VERSION ""

NS_ :

BS_:

BU_: GWM SCMB_PSM HVAC_RCCM GENERIC_GWMWakeup SOBDMD_AHCM_FOH TRM _delete SODL RTM PDM SCMH SCMG RSM SODR DDM RGTM DSM SCME TSTR

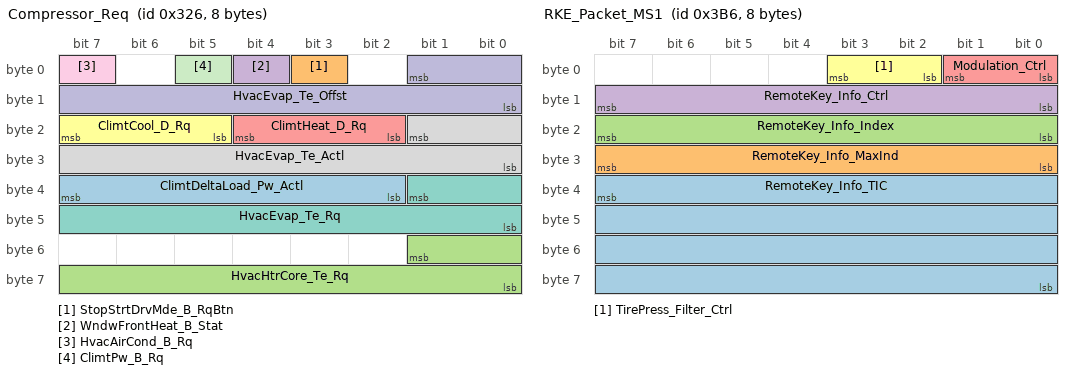
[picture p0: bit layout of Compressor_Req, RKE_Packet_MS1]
BO_ 806 Compressor_Req: 8 HVAC_RCCM
 SG_ ClimtDeltaLoad_Pw_Actl : 39|6@0+ (50,-1600) [-1600|1450] "watts"  GWM
 SG_ StopStrtDrvMde_B_RqBtn : 3|1@0+ (1,0) [0|1] "SED"  GWM
 SG_ HvacHtrCore_Te_Rq : 49|10@0+ (0.25,-50) [-50|205.75] "degC"  GWM
 SG_ WndwFrontHeat_B_Stat : 4|1@0+ (1,0) [0|1] "SED"  GWM
 SG_ ClimtHeat_D_Rq : 20|3@0+ (1,0) [0|7] "SED"  GWM
 SG_ ClimtCool_D_Rq : 23|3@0+ (1,0) [0|7] "SED"  GWM
 SG_ HvacEvap_Te_Rq : 33|10@0+ (0.125,-50) [-50|77.875] "Degrees C"  GWM
 SG_ HvacEvap_Te_Actl : 17|10@0+ (0.125,-50) [-50|77.75] "Degrees C"  GWM
 SG_ HvacAirCond_B_Rq : 7|1@0+ (1,0) [0|1] "SED"  GWM
 SG_ HvacEvap_Te_Offst : 1|10@0+ (0.125,-50) [-50|77.875] "Degrees C"  GWM
 SG_ ClimtPw_B_Rq : 5|1@0+ (1,0) [0|1] "SED"  GWM

BO_ 950 RKE_Packet_MS1: 8 GWM
 SG_ RemoteKey_Info_TIC : 39|32@0+ (1,0) [0|4294967295] "Unitless"  RTM
 SG_ RemoteKey_Info_MaxInd : 31|8@0+ (1,0) [0|255] "Unitless"  RTM
 SG_ RemoteKey_Info_Index : 23|8@0+ (1,0) [0|255] "Unitless"  RTM
 SG_ RemoteKey_Info_Ctrl : 15|8@0+ (1,0) [0|255] "Unitless" Vector__XXX
 SG_ Modulation_Ctrl : 1|2@0+ (1,0) [0|3] "SED" Vector__XXX
 SG_ TirePress_Filter_Ctrl : 3|2@0+ (1,0) [0|3] "SED"  RTM

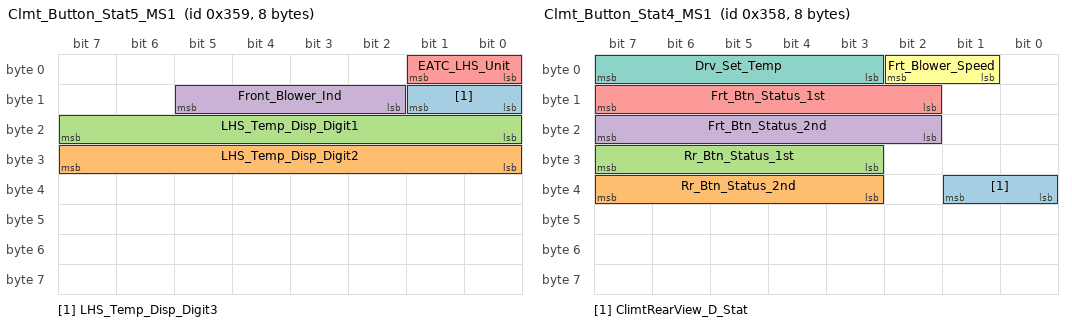
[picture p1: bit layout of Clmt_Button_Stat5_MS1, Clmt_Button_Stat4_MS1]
BO_ 857 Clmt_Button_Stat5_MS1: 8 GWM
 SG_ LHS_Temp_Disp_Digit3 : 9|2@0+ (1,0) [0|3] "SED"  HVAC_RCCM
 SG_ LHS_Temp_Disp_Digit2 : 31|8@0+ (1,0) [0|255] "ASCII"  HVAC_RCCM
 SG_ LHS_Temp_Disp_Digit1 : 23|8@0+ (1,0) [0|255] "ASCII"  HVAC_RCCM
 SG_ Front_Blower_Ind : 13|4@0+ (1,0) [0|15] "SED"  HVAC_RCCM
 SG_ EATC_LHS_Unit : 1|2@0+ (1,0) [0|3] "SED"  HVAC_RCCM

BO_ 856 Clmt_Button_Stat4_MS1: 8 GWM
 SG_ ClimtRearView_D_Stat : 33|2@0+ (1,0) [0|3] "SED" Vector__XXX
 SG_ Rr_Btn_Status_2nd : 39|5@0+ (1,0) [0|31] "SED" Vector__XXX
 SG_ Rr_Btn_Status_1st : 31|5@0+ (1,0) [0|31] "SED" Vector__XXX
 SG_ Frt_Btn_Status_2nd : 23|6@0+ (1,0) [0|63] "SED"  HVAC_RCCM
 SG_ Frt_Btn_Status_1st : 15|6@0+ (1,0) [0|63] "SED"  HVAC_RCCM
 SG_ Frt_Blower_Speed : 2|2@0+ (1,0) [0|3] "SED"  HVAC_RCCM
 SG_ Drv_Set_Temp : 7|5@0+ (1,0) [0|31] "SED"  HVAC_RCCM

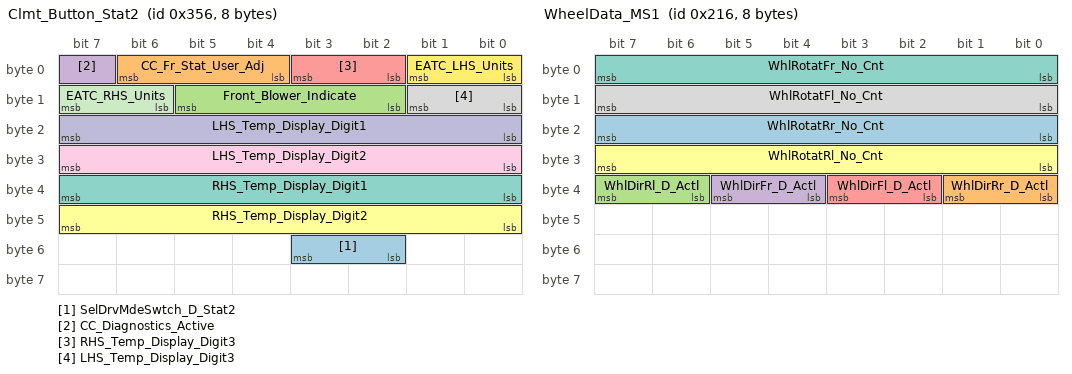
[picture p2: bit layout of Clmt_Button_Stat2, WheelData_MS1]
BO_ 854 Clmt_Button_Stat2: 8 HVAC_RCCM
 SG_ SelDrvMdeSwtch_D_Stat2 : 51|2@0+ (1,0) [0|3] "SED"  GWM
 SG_ CC_Fr_Stat_User_Adj : 6|3@0+ (1,0) [0|7] "SED"  GWM
 SG_ Front_Blower_Indicate : 13|4@0+ (1,0) [0|15] "SED"  GWM
 SG_ CC_Diagnostics_Active : 7|1@0+ (1,0) [0|1] "SED"  GWM
 SG_ RHS_Temp_Display_Digit3 : 3|2@0+ (1,0) [0|3] "SED"  GWM
 SG_ RHS_Temp_Display_Digit2 : 47|8@0+ (1,0) [0|255] "ASCII"  GWM
 SG_ RHS_Temp_Display_Digit1 : 39|8@0+ (1,0) [0|255] "ASCII"  GWM
 SG_ LHS_Temp_Display_Digit3 : 9|2@0+ (1,0) [0|3] "SED"  GWM
 SG_ LHS_Temp_Display_Digit2 : 31|8@0+ (1,0) [0|255] "ASCII"  GWM
 SG_ LHS_Temp_Display_Digit1 : 23|8@0+ (1,0) [0|255] "ASCII"  GWM
 SG_ EATC_RHS_Units : 15|2@0+ (1,0) [0|3] "SED"  GWM
 SG_ EATC_LHS_Units : 1|2@0+ (1,0) [0|3] "SED"  GWM

BO_ 534 WheelData_MS1: 8 GWM
 SG_ WhlRotatRr_No_Cnt : 23|8@0+ (1,0) [0|255] "Unitless"  SODL,SODR
 SG_ WhlDirRr_D_Actl : 33|2@0+ (1,0) [0|3] "SED"  SODL,SODR
 SG_ WhlDirRl_D_Actl : 39|2@0+ (1,0) [0|3] "SED"  SODL,SODR
 SG_ WhlDirFr_D_Actl : 37|2@0+ (1,0) [0|3] "SED"  SODL,SODR
 SG_ WhlDirFl_D_Actl : 35|2@0+ (1,0) [0|3] "SED"  SODL,SODR
 SG_ WhlRotatRl_No_Cnt : 31|8@0+ (1,0) [0|255] "Unitless"  SODL,SODR
 SG_ WhlRotatFr_No_Cnt : 7|8@0+ (1,0) [0|255] "Unitless"  SODL,SODR
 SG_ WhlRotatFl_No_Cnt : 15|8@0+ (1,0) [0|255] "Unitless"  SODL,SODR

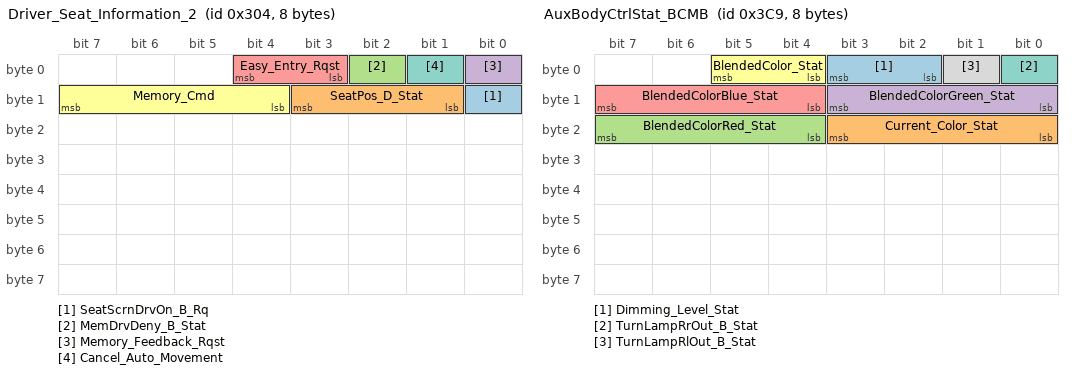
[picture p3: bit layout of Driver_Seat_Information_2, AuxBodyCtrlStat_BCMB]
BO_ 772 Driver_Seat_Information_2: 8 DSM
 SG_ SeatScrnDrvOn_B_Rq : 8|1@0+ (1,0) [0|1] "SED"  GWM
 SG_ SeatPos_D_Stat : 11|3@0+ (1,0) [0|7] "SED"  GWM
 SG_ MemDrvDeny_B_Stat : 2|1@0+ (1,0) [0|1] "SED"  GWM
 SG_ Memory_Feedback_Rqst : 0|1@0+ (1,0) [0|1] "SED"  GWM
 SG_ Easy_Entry_Rqst : 4|2@0+ (1,0) [0|3] "SED"  GWM,SCMH,SCMG
 SG_ Memory_Cmd : 15|4@0+ (1,0) [0|15] "SED"  GWM,SCMH,DDM,PDM,SCMG
 SG_ Cancel_Auto_Movement : 1|1@0+ (1,0) [0|1] "SED"  GWM,SCMH,PDM,DDM,SCMG

BO_ 935 Side_Detect_R_Stat: 8 SODR
 SG_ LcwaRight_D_Stat : 52|3@0+ (1,0) [0|7] "SED"  GWM
 SG_ LcwaDetctRight2_B_Stat : 40|1@0+ (1,0) [0|1] "SED"  GWM
 SG_ LcwaDetctRight1_B_Stat : 41|1@0+ (1,0) [0|1] "SED"  GWM
 SG_ RbaCtaRight_D_Stat : 55|3@0+ (1,0) [0|7] "SED"  SODL,GWM
 SG_ BttRight_D_Stat : 45|3@0+ (1,0) [0|7] "SED"  SODL,GWM
 SG_ BttRight_D_RqDrv : 47|2@0+ (1,0) [0|3] "SED"  SODL,GWM
 SG_ CtaAlrtRight2_D_Stat : 30|3@0+ (1,0) [0|7] "SED"  GWM
 SG_ CtaRightBrkEnbl_B_Rq : 31|1@0+ (1,0) [0|1] "SED"  SODL,GWM
 SG_ CtaRightBrkDecel_B_Rq : 7|1@0+ (1,0) [0|1] "SED"  SODL,GWM
 SG_ Side_Detect_R_Illum : 39|8@0+ (1,0) [0|255] "Percent"  DDM,PDM,GWM
 SG_ CtaSnsRight_D_Stat : 25|2@0+ (1,0) [0|3] "SED"  SODL,GWM
 SG_ CtaAlrtRight_D_Stat : 8|1@0+ (1,0) [0|1] "SED"  DDM,PDM,GWM
 SG_ CtaRight_D_Stat : 18|3@0+ (1,0) [0|7] "SED"  SODL,GWM
 SG_ SodRight_D_Stat : 15|3@0+ (1,0) [0|7] "SED"  SODL,GWM
 SG_ SodSnsRight_D_Stat : 12|2@0+ (1,0) [0|3] "SED"  DDM,PDM,GWM,SODL
 SG_ SodAlrtRight_D_Stat : 10|2@0+ (1,0) [0|3] "SED"  DDM,PDM,GWM
 SG_ SodDetctRight_D_Stat : 23|3@0+ (1,0) [0|7] "SED"  GWM
 SG_ SodWarnRight_Prd_Rq : 6|7@0+ (1,0) [0|127] "millisecond"  DDM,PDM,GWM
 SG_ SodInnrRight_D_Stat : 20|2@0+ (1,0) [0|3] "SED"  SODL,GWM
 SG_ CtaInnrRight_D_Stat : 27|2@0+ (1,0) [0|3] "SED"  GWM,SODL

BO_ 934 Side_Detect_L_Stat: 8 SODL
 SG_ RbaCtaLeft_D_Stat : 55|3@0+ (1,0) [0|7] "SED"  GWM,SODR
 SG_ LcwaLeft_D_Stat : 52|3@0+ (1,0) [0|7] "SED"  GWM,SODR
 SG_ LcwaDetctLeft2_B_Stat : 40|1@0+ (1,0) [0|1] "SED"  GWM,SODR
 SG_ LcwaDetctLeft1_B_Stat : 41|1@0+ (1,0) [0|1] "SED"  GWM,SODR
 SG_ BttLeft_D_Stat : 45|3@0+ (1,0) [0|7] "SED"  GWM,SODR
 SG_ BttLeft_D_RqDrv : 47|2@0+ (1,0) [0|3] "SED"  SODR,GWM
 SG_ CtaAlrtLeft2_D_Stat : 30|3@0+ (1,0) [0|7] "SED"  GWM
 SG_ CtaLeftBrkDecel_B_Rq : 7|1@0+ (1,0) [0|1] "SED"  SODR,GWM
 SG_ CtaLeftBrkEnbl_B_Rq : 31|1@0+ (1,0) [0|1] "SED"  SODR,GWM
 SG_ Side_Detect_L_Illum : 39|8@0+ (1,0) [0|255] "Percent"  GWM,DDM,PDM
 SG_ CtaInnrLeft_D_Stat : 27|2@0+ (1,0) [0|3] "SED"  GWM,SODR
 SG_ CtaSnsLeft_D_Stat : 25|2@0+ (1,0) [0|3] "SED"  SODR,GWM
 SG_ SodDetctLeft_D_Stat : 23|3@0+ (1,0) [0|7] "SED"  GWM
 SG_ CtaLeft_D_Stat : 18|3@0+ (1,0) [0|7] "SED"  SODR,GWM
 SG_ CtaAlrtLeft_D_Stat : 8|1@0+ (1,0) [0|1] "SED"  DDM,PDM,GWM
 SG_ SodLeft_D_Stat : 15|3@0+ (1,0) [0|7] "SED"  SODR,GWM
 SG_ SodSnsLeft_D_Stat : 12|2@0+ (1,0) [0|3] "SED"  DDM,PDM,SODR,GWM
 SG_ SodAlrtLeft_D_Stat : 10|2@0+ (1,0) [0|3] "SED"  DDM,PDM,GWM
 SG_ SodWarnLeft_Prd_Rq : 6|7@0+ (1,0) [0|127] "millisecond"  DDM,PDM,GWM
 SG_ SodInnrLeft_D_Stat : 20|2@0+ (1,0) [0|3] "SED"  SODR,GWM

BO_ 969 AuxBodyCtrlStat_BCMB: 8 GENERIC_GWMWakeup
 SG_ Dimming_Level_Stat : 3|2@0+ (1,0) [0|3] "SED"  GWM
 SG_ Current_Color_Stat : 19|4@0+ (1,0) [0|15] "SED"  GWM
 SG_ BlendedColorRed_Stat : 23|4@0+ (1,0) [0|15] "SED"  GWM
 SG_ BlendedColorGreen_Stat : 11|4@0+ (1,0) [0|15] "SED"  GWM
 SG_ BlendedColorBlue_Stat : 15|4@0+ (1,0) [0|15] "SED"  GWM
 SG_ BlendedColor_Stat : 5|2@0+ (1,0) [0|3] "SED"  GWM
 SG_ TurnLampRrOut_B_Stat : 0|1@0+ (1,0) [0|1] "SED"  GWM
 SG_ TurnLampRlOut_B_Stat : 1|1@0+ (1,0) [0|1] "SED"  GWM

BO_ 1070 EngineData_2_MS1: 8 GWM
 SG_ StopStrtStdby_D_Indic_UB : 43|1@0+ (1,0) [0|1] "SED" Vector__XXX
 SG_ PassRstrnInd_Req_UB : 42|1@0+ (1,0) [0|1] "SED" Vector__XXX
 SG_ HiElPwInhbt_B_Stat_UB : 61|1@0+ (1,0) [0|1] "SED"  DDM,PDM
 SG_ HiElPwInhbt_B_Stat : 47|1@0+ (1,0) [0|1] "SED"  DDM,PDM
 SG_ StopStrtStdby_D_Indic : 46|3@0+ (1,0) [0|7] "SED" Vector__XXX
 SG_ CoolantFanStepAct_UB : 2|1@0+ (1,0) [0|1] "SED"  HVAC_RCCM
 SG_ CoolantFanStepAct : 7|5@0+ (1,0) [0|31] "Steps"  HVAC_RCCM
 SG_ RstrnImpactEvntStatus_UB : 56|1@0+ (1,0) [0|1] "SED"  HVAC_RCCM,SOBDMD_AHCM_FOH
 SG_ EngAirIn_Te_Actl_UB : 60|1@0+ (1,0) [0|1] "SED"  HVAC_RCCM
 SG_ RstrnImpactEvntStatus : 59|3@0+ (1,0) [0|7] "SED"  HVAC_RCCM,SOBDMD_AHCM_FOH
 SG_ EngAirIn_Te_Actl : 55|10@0+ (0.25,-128) [-128|127.25] "degC"  HVAC_RCCM
 SG_ EngAout_N_Actl_UB : 0|1@0+ (1,0) [0|1] "SED"  HVAC_RCCM,SOBDMD_AHCM_FOH
 SG_ EngAout_N_Actl : 28|13@0+ (2,0) [0|16382] "rpm"  HVAC_RCCM,SOBDMD_AHCM_FOH
 SG_ VehVActlEng_D_Qf : 31|2@0+ (1,0) [0|3] "SED"  SCME,HVAC_RCCM,DSM,RTM,DDM,PDM,SODL,SODR
 SG_ Veh_V_ActlEng_UB : 29|1@0+ (1,0) [0|1] "SED"  SCME,HVAC_RCCM,RGTM,DSM,SCMG,SCMH,DDM,PDM,RTM,SODL,SODR
 SG_ Veh_V_ActlEng : 15|16@0+ (0.01,0) [0|655.35] "kph"  SCME,HVAC_RCCM,SODL,RGTM,DSM,SCMG,SCMH,DDM,PDM,RTM,SODR
 SG_ PassRstrnInd_Req : 41|2@0+ (1,0) [0|3] "SED" Vector__XXX

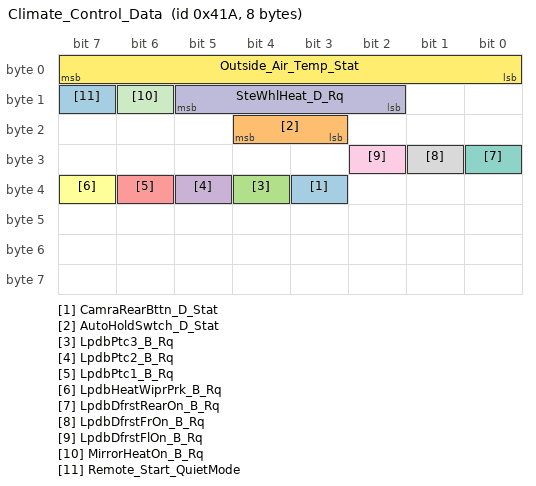
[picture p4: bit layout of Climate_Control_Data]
BO_ 1050 Climate_Control_Data: 8 HVAC_RCCM
 SG_ CamraRearBttn_D_Stat : 35|1@0+ (1,0) [0|1] "SED"  GWM
 SG_ AutoHoldSwtch_D_Stat : 20|2@0+ (1,0) [0|3] "SED"  GWM
 SG_ LpdbPtc3_B_Rq : 36|1@0+ (1,0) [0|1] "SED"  GWM
 SG_ LpdbPtc2_B_Rq : 37|1@0+ (1,0) [0|1] "SED"  GWM
 SG_ LpdbPtc1_B_Rq : 38|1@0+ (1,0) [0|1] "SED"  GWM
 SG_ LpdbHeatWiprPrk_B_Rq : 39|1@0+ (1,0) [0|1] "SED"  GWM
 SG_ LpdbDfrstRearOn_B_Rq : 24|1@0+ (1,0) [0|1] "SED"  GWM
 SG_ LpdbDfrstFrOn_B_Rq : 25|1@0+ (1,0) [0|1] "SED"  GWM
 SG_ LpdbDfrstFlOn_B_Rq : 26|1@0+ (1,0) [0|1] "SED"  GWM
 SG_ SteWhlHeat_D_Rq : 13|4@0+ (1,0) [0|15] "SED"  GWM
 SG_ MirrorHeatOn_B_Rq : 14|1@0+ (1,0) [0|1] "SED"  GWM,DDM,PDM
 SG_ Outside_Air_Temp_Stat : 7|8@0+ (0.5,-40) [-40|86.5] "Degrees C"  RGTM,GWM,DDM,PDM,SOBDMD_AHCM_FOH
 SG_ Remote_Start_QuietMode : 15|1@0+ (1,0) [0|1] "SED"  GWM

BO_ 1856 TesterPhysicalReqDDM: 8 TSTR
 SG_ TesterPhysicalReqDDM : 7|64@0+ (1,0) [0|1.84467E+019] "unitless"  DDM

BO_ 1864 TesterPhysicalResDDM: 8 DDM
 SG_ TesterPhysicalResDDM : 7|64@0+ (1,0) [0|1.84467E+019] "unitless"  TSTR

BO_ 1937 TesterPhysicalReqTRM: 8 TSTR
 SG_ TesterPhysicalReqTRM : 7|64@0+ (1,0) [0|1.84467E+019] "unitless"  TRM

CM_ SG_ 857 LHS_Temp_Disp_Digit3 "Added for MY 08";
CM_ SG_ 857 LHS_Temp_Disp_Digit2 "Added for MY 08";
CM_ SG_ 857 LHS_Temp_Disp_Digit1 "Added for MY 08";
CM_ SG_ 857 EATC_LHS_Unit "Added for MY 08";
CM_ SG_ 854 RHS_Temp_Display_Digit3 "Added for MY 08";
CM_ SG_ 854 RHS_Temp_Display_Digit2 "Added for MY 08";
CM_ SG_ 854 RHS_Temp_Display_Digit1 "Added for MY 08";
CM_ SG_ 854 LHS_Temp_Display_Digit3 "Added for MY 08";
CM_ SG_ 854 LHS_Temp_Display_Digit2 "Added for MY 08";
CM_ SG_ 854 LHS_Temp_Display_Digit1 "Added for MY 08";
CM_ SG_ 854 EATC_RHS_Units "Added for MY 08";
CM_ SG_ 854 EATC_LHS_Units "Added for MY 08";
CM_ SG_ 534 WhlRotatRr_No_Cnt "DCR 1833 to update Tx from GWM to EP100ms. Wheel Count signals are used by complex algorithm to determine Tire Pressure by Location & can't change from 20msec. (jweinfur)";
CM_ SG_ 534 WhlRotatRl_No_Cnt "DCR 1833 to update Tx from GWM to EP100ms. Wheel Count signals are used by complex algorithm to determine Tire Pressure by Location & can't change from 20msec. (jweinfur)";
CM_ SG_ 534 WhlRotatFr_No_Cnt "DCR 1833 to update Tx from GWM to EP100ms. Wheel Count signals are used by complex algorithm to determine Tire Pressure by Location & can't change from 20msec. (jweinfur)";
CM_ SG_ 534 WhlRotatFl_No_Cnt "DCR 1833 to update Tx from GWM to EP100ms. Wheel Count signals are used by complex algorithm to determine Tire Pressure by Location & can't change from 20msec. (jweinfur)";
CM_ SG_ 772 Memory_Feedback_Rqst "Updated to 1 bit for CGEA, Not backwards compatible";
CM_ SG_ 935 Side_Detect_R_Illum "DDMGenSigTimeoutTime=2000";
CM_ SG_ 935 SodRight_D_Stat "IPCGenSigTimeoutTime=1600";
CM_ SG_ 935 SodSnsRight_D_Stat "IPCGenSigTimeoutTime=1600";
CM_ SG_ 935 SodAlrtRight_D_Stat "DDMGenSigTimeoutTime=2000";
CM_ SG_ 935 CtaInnrRight_D_Stat "IPCGenSigTimeoutTime=1600";
CM_ SG_ 934 Side_Detect_L_Illum "DDMGenSigTimeoutTime=2000";
CM_ SG_ 934 CtaInnrLeft_D_Stat "IPCGenSigTimeoutTime=1600";
CM_ SG_ 934 SodLeft_D_Stat "IPCGenSigTimeoutTime=1600";
CM_ SG_ 934 SodSnsLeft_D_Stat "IPCGenSigTimeoutTime=1600";
CM_ SG_ 934 SodAlrtLeft_D_Stat "DDMGenSigTimeoutTime=2000";
CM_ SG_ 969 TurnLampRrOut_B_Stat "Signal not transmitted on vehicles without a BCMB module.";
CM_ SG_ 969 TurnLampRlOut_B_Stat "Signal not transmitted on vehicles without a BCMB module.";
CM_ SG_ 1070 HiElPwInhbt_B_Stat "Signal not transmitted on HEV programs";
CM_ SG_ 1050 Outside_Air_Temp_Stat "Filtered value, i.e. same as disply for customer";
BA_DEF_ BO_  "FrameGatewayNetwork" STRING ;
BA_DEF_ BO_  "FrameGatewayMS1" HEX 0 1407;
BA_DEF_ BO_  "NetworkInitialization" ENUM  "No","Yes";
BA_DEF_ BO_  "FrameGatewayId" HEX 0 1407;
BA_DEF_ BO_  "EventRateOfChange" INT 10 10000;
BA_DEF_ BO_  "GenMsgStartDelayTime" INT 0 10000;
BA_DEF_ BO_  "GenMsgNrOfRepetition" INT 0 100;
BA_DEF_ BO_  "GenMsgDelayTime" INT 0 1000;
BA_DEF_ BO_  "GenMsgCycleTime" INT 0 100000;
BA_DEF_ BO_  "GenMsgSendType" ENUM  "FixedPeriodic","Event","EnabledPeriodic","NotUsed","NotUsed","EventPeriodic","NotUsed","NotUsed","NoMsgSendType";
BA_DEF_ SG_  "U_P702_MY2021_Tx" ENUM  "No","Yes";
BA_DEF_ SG_  "U_CX727_MY2021_Tx" ENUM  "No","Yes";
BA_DEF_ SG_  "U_VN127_MY20_Tx" ENUM  "No","Yes";
BA_DEF_ SG_  "U_H567_MY20_Tx" ENUM  "No","Yes";
BA_DEF_ SG_  "U_CX430_MY2021_Tx" ENUM  "No","Yes";
BA_DEF_ SG_  "U_U611_U625_MY20_Phev_Tx" ENUM  "No","Yes";
BA_DEF_ SG_  "U_B562_MY18_Diesel_Tx" ENUM  "No","Yes";
BA_DEF_ SG_  "U_CX482_CX483_MY20_Tx" ENUM  "No","Yes";
BA_DEF_ SG_  "U_U611_U625_MY20_Hev_Tx" ENUM  "No","Yes";
BA_DEF_ SG_  "U_U611_U625_MY20_Gas_Tx" ENUM  "No","Yes";
BA_DEF_ SG_  "U_B500_MY18_Diesel_Tx" ENUM  "No","Yes";
BA_DEF_ SG_  "U_B500_MY18_Gas_Tx" ENUM  "No","Yes";
BA_DEF_ SG_  "U_C490_MY18_Tx" ENUM  "No","Yes";
BA_DEF_ SG_  "U_B562_MY18_Gas_Tx" ENUM  "No","Yes";
BA_DEF_ SG_  "U_C519_MY18_5_Gas_Tx" ENUM  "No","Yes";
BA_DEF_ SG_  "U_C519_MY18_5_Diesel_Tx" ENUM  "No","Yes";
BA_DEF_ SG_  "U_B515_MCA_MY17_Gas_Tx" ENUM  "No","Yes";
BA_DEF_ SG_  "U_B515_MCA_MY17_Diesel_Tx" ENUM  "No","Yes";
BA_DEF_ SG_  "U_B479_MY17_Diesel_Tx" ENUM  "No","Yes";
BA_DEF_ SG_  "U_B479_MY17_Gas_Tx" ENUM  "No","Yes";
BA_DEF_ SG_  "U_P702_MY2021_Rx" ENUM  "No","Yes";
BA_DEF_ SG_  "U_CX727_MY2021_Rx" ENUM  "No","Yes";
BA_DEF_ SG_  "U_VN127_MY20_Rx" ENUM  "No","Yes";
BA_DEF_ SG_  "U_H567_MY20_Rx" ENUM  "No","Yes";
BA_DEF_ SG_  "U_CX430_MY2021_Rx" ENUM  "No","Yes";
BA_DEF_ SG_  "U_U611_U625_MY20_Phev_Rx" ENUM  "No","Yes";
BA_DEF_ SG_  "U_B562_MY18_Diesel_Rx" ENUM  "No","Yes";
BA_DEF_ SG_  "U_CX482_CX483_MY20_Rx" ENUM  "No","Yes";
BA_DEF_ SG_  "U_U611_U625_MY20_Hev_Rx" ENUM  "No","Yes";
BA_DEF_ SG_  "U_U611_U625_MY20_Gas_Rx" ENUM  "No","Yes";
BA_DEF_ SG_  "U_B500_MY18_Diesel_Rx" ENUM  "No","Yes";
BA_DEF_ SG_  "U_B500_MY18_Gas_Rx" ENUM  "No","Yes";
BA_DEF_ SG_  "U_C490_MY18_Rx" ENUM  "No","Yes";
BA_DEF_ SG_  "U_B562_MY18_Gas_Rx" ENUM  "No","Yes";
BA_DEF_ SG_  "U_LC1_B515_MY17_Gas_Rx" ENUM  "No","Yes";
BA_DEF_ SG_  "U_LC1_B515_MY17_Diesel_Rx" ENUM  "No","Yes";
BA_DEF_ SG_  "U_C519_MY18_5_Gas_Rx" ENUM  "No","Yes";
BA_DEF_ SG_  "U_C519_MY18_5_Diesel_Rx" ENUM  "No","Yes";
BA_DEF_ SG_  "U_B515_MCA_MY17_Gas_Rx" ENUM  "No","Yes";
BA_DEF_ SG_  "U_B515_MCA_MY17_Diesel_Rx" ENUM  "No","Yes";
BA_DEF_ SG_  "U_B479_MY17_Diesel_Rx" ENUM  "No","Yes";
BA_DEF_ SG_  "U_B479_MY17_Gas_Rx" ENUM  "No","Yes";
BA_DEF_ SG_  "U_B562LC_MY15_Gas_Rx" ENUM  "No","Yes";
BA_DEF_ SG_  "U_B562LC_MY15_Diesel_Rx" ENUM  "No","Yes";
BA_DEF_ SG_  "GenSigStartValue" HEX 0 268435455;
BA_DEF_ SG_  "MetaData" ENUM  "No","Yes";
BA_DEF_ SG_  "ContentDependant" ENUM  "No","Yes";
BA_DEF_ SG_  "GenSigStartValueInteger" INT 0 1000000000;
BA_DEF_ SG_  "UsedOnPgmDBC" ENUM  "No","Yes";
BA_DEF_ SG_  "CrossOver_InfoCAN" ENUM  "No","Yes";
BA_DEF_ SG_  "WakeupSignal" ENUM  "No","Yes";
BA_DEF_ SG_  "GenSigInactiveValue" INT 0 100000;
BA_DEF_ SG_  "GenSigSendType" ENUM  "Cyclic","OnWrite","vector_leerstring","OnChange","vector_leerstring","IfActive","vector_leerstring","NoSigSendType";
BA_DEF_ BO_  "AuthFreshnessCounterSyncAttempt" INT 0 2;
BA_DEF_ BO_  "GenMsgRoutingTimeoutTime" INT 0 5000;
BA_DEF_ BO_  "MessageGateway" ENUM  "No","Yes";
BA_DEF_ BO_  "NmAsrMessage" ENUM  "No","Yes";
BA_DEF_ BO_  "DiagState" ENUM  "No","Yes";
BA_DEF_ BO_  "DiagRequest" ENUM  "No","Yes";
BA_DEF_ BO_  "DiagResponse" ENUM  "No","Yes";
BA_DEF_ BO_  "NmMessage" ENUM  "No","Yes";
BA_DEF_ BO_  "GenMsgILSupport" ENUM  "No","Yes";
BA_DEF_DEF_  "FrameGatewayNetwork" "NONE";
BA_DEF_DEF_  "FrameGatewayMS1" 0;
BA_DEF_DEF_  "NetworkInitialization" "Yes";
BA_DEF_DEF_  "FrameGatewayId" 0;
BA_DEF_DEF_  "EventRateOfChange" 10000;
BA_DEF_DEF_  "GenMsgStartDelayTime" 0;
BA_DEF_DEF_  "GenMsgNrOfRepetition" 1;
BA_DEF_DEF_  "GenMsgDelayTime" 20;
BA_DEF_DEF_  "GenMsgCycleTime" 0;
BA_DEF_DEF_  "GenMsgSendType" "NoMsgSendType";
BA_DEF_DEF_  "U_P702_MY2021_Tx" "No";
BA_DEF_DEF_  "U_CX727_MY2021_Tx" "No";
BA_DEF_DEF_  "U_VN127_MY20_Tx" "No";
BA_DEF_DEF_  "U_H567_MY20_Tx" "No";
BA_DEF_DEF_  "U_CX430_MY2021_Tx" "No";
BA_DEF_DEF_  "U_U611_U625_MY20_Phev_Tx" "No";
BA_DEF_DEF_  "U_B562_MY18_Diesel_Tx" "No";
BA_DEF_DEF_  "U_CX482_CX483_MY20_Tx" "No";
BA_DEF_DEF_  "U_U611_U625_MY20_Hev_Tx" "No";
BA_DEF_DEF_  "U_U611_U625_MY20_Gas_Tx" "No";
BA_DEF_DEF_  "U_B500_MY18_Diesel_Tx" "No";
BA_DEF_DEF_  "U_B500_MY18_Gas_Tx" "No";
BA_DEF_DEF_  "U_C490_MY18_Tx" "No";
BA_DEF_DEF_  "U_B562_MY18_Gas_Tx" "No";
BA_DEF_DEF_  "U_C519_MY18_5_Gas_Tx" "No";
BA_DEF_DEF_  "U_C519_MY18_5_Diesel_Tx" "No";
BA_DEF_DEF_  "U_B515_MCA_MY17_Gas_Tx" "No";
BA_DEF_DEF_  "U_B515_MCA_MY17_Diesel_Tx" "No";
BA_DEF_DEF_  "U_B479_MY17_Diesel_Tx" "No";
BA_DEF_DEF_  "U_B479_MY17_Gas_Tx" "No";
BA_DEF_DEF_  "U_P702_MY2021_Rx" "No";
BA_DEF_DEF_  "U_CX727_MY2021_Rx" "No";
BA_DEF_DEF_  "U_VN127_MY20_Rx" "No";
BA_DEF_DEF_  "U_H567_MY20_Rx" "No";
BA_DEF_DEF_  "U_CX430_MY2021_Rx" "No";
BA_DEF_DEF_  "U_U611_U625_MY20_Phev_Rx" "No";
BA_DEF_DEF_  "U_B562_MY18_Diesel_Rx" "No";
BA_DEF_DEF_  "U_CX482_CX483_MY20_Rx" "No";
BA_DEF_DEF_  "U_U611_U625_MY20_Hev_Rx" "No";
BA_DEF_DEF_  "U_U611_U625_MY20_Gas_Rx" "No";
BA_DEF_DEF_  "U_B500_MY18_Diesel_Rx" "No";
BA_DEF_DEF_  "U_B500_MY18_Gas_Rx" "No";
BA_DEF_DEF_  "U_C490_MY18_Rx" "No";
BA_DEF_DEF_  "U_B562_MY18_Gas_Rx" "No";
BA_DEF_DEF_  "U_LC1_B515_MY17_Gas_Rx" "No";
BA_DEF_DEF_  "U_LC1_B515_MY17_Diesel_Rx" "No";
BA_DEF_DEF_  "U_C519_MY18_5_Gas_Rx" "No";
BA_DEF_DEF_  "U_C519_MY18_5_Diesel_Rx" "No";
BA_DEF_DEF_  "U_B515_MCA_MY17_Gas_Rx" "No";
BA_DEF_DEF_  "U_B515_MCA_MY17_Diesel_Rx" "No";
BA_DEF_DEF_  "U_B479_MY17_Diesel_Rx" "No";
BA_DEF_DEF_  "U_B479_MY17_Gas_Rx" "No";
BA_DEF_DEF_  "U_B562LC_MY15_Gas_Rx" "No";
BA_DEF_DEF_  "U_B562LC_MY15_Diesel_Rx" "No";
BA_DEF_DEF_  "GenSigStartValue" 0;
BA_DEF_DEF_  "MetaData" "No";
BA_DEF_DEF_  "ContentDependant" "No";
BA_DEF_DEF_  "GenSigStartValueInteger" 0;
BA_DEF_DEF_  "UsedOnPgmDBC" "Yes";
BA_DEF_DEF_  "CrossOver_InfoCAN" "No";
BA_DEF_DEF_  "WakeupSignal" "No";
BA_DEF_DEF_  "GenSigInactiveValue" 0;
BA_DEF_DEF_  "GenSigSendType" "NoSigSendType";
BA_DEF_DEF_  "AuthFreshnessCounterSyncAttempt" 2;
BA_DEF_DEF_  "GenMsgRoutingTimeoutTime" 0;
BA_DEF_DEF_  "MessageGateway" "No";
BA_DEF_DEF_  "NmAsrMessage" "No";
BA_DEF_DEF_  "DiagState" "No";
BA_DEF_DEF_  "DiagRequest" "No";
BA_DEF_DEF_  "DiagResponse" "No";
BA_DEF_DEF_  "NmMessage" "No";
BA_DEF_DEF_  "GenMsgILSupport" "Yes";
BA_ "GenMsgCycleTime" BO_ 806 100;
BA_ "GenMsgSendType" BO_ 806 0;
BA_ "FrameGatewayNetwork" BO_ 950 "HS1_CAN";
BA_ "FrameGatewayId" BO_ 950 950;
BA_ "GenMsgSendType" BO_ 857 5;
BA_ "GenMsgCycleTime" BO_ 857 1000;
BA_ "FrameGatewayNetwork" BO_ 857 "HS3_CAN";
BA_ "FrameGatewayId" BO_ 857 867;
BA_ "GenMsgSendType" BO_ 856 5;
BA_ "GenMsgCycleTime" BO_ 856 1000;
BA_ "FrameGatewayNetwork" BO_ 856 "HS3_CAN";
BA_ "FrameGatewayId" BO_ 856 866;
BA_ "GenMsgCycleTime" BO_ 854 1000;
BA_ "GenMsgSendType" BO_ 854 5;
BA_ "GenMsgDelayTime" BO_ 534 10;
BA_ "GenMsgCycleTime" BO_ 534 100;
BA_ "GenMsgSendType" BO_ 534 0;
BA_ "GenMsgRoutingTimeoutTime" BO_ 534 60;
BA_ "MessageGateway" BO_ 534 1;
BA_ "GenMsgCycleTime" BO_ 772 1000;
BA_ "GenMsgSendType" BO_ 772 5;
BA_ "GenMsgCycleTime" BO_ 935 200;
BA_ "GenMsgSendType" BO_ 935 5;
BA_ "GenMsgCycleTime" BO_ 934 200;
BA_ "GenMsgSendType" BO_ 934 5;
BA_ "GenMsgCycleTime" BO_ 1070 50;
BA_ "GenMsgSendType" BO_ 1070 5;
BA_ "GenMsgCycleTime" BO_ 1050 1000;
BA_ "GenMsgSendType" BO_ 1050 5;
BA_ "NetworkInitialization" BO_ 1856 0;
BA_ "GenMsgDelayTime" BO_ 1856 0;
BA_ "GenMsgSendType" BO_ 1856 1;
BA_ "DiagRequest" BO_ 1856 1;
BA_ "GenMsgILSupport" BO_ 1856 0;
BA_ "NetworkInitialization" BO_ 1864 0;
BA_ "GenMsgDelayTime" BO_ 1864 0;
BA_ "GenMsgSendType" BO_ 1864 1;
BA_ "DiagResponse" BO_ 1864 1;
BA_ "GenMsgILSupport" BO_ 1864 0;
BA_ "NetworkInitialization" BO_ 1937 0;
BA_ "GenMsgDelayTime" BO_ 1937 0;
BA_ "GenMsgSendType" BO_ 1937 1;
BA_ "DiagRequest" BO_ 1937 1;
BA_ "GenMsgILSupport" BO_ 1937 0;
BA_ "GenSigSendType" SG_ 806 ClimtDeltaLoad_Pw_Actl 3;
BA_ "U_CX727_MY2021_Tx" SG_ 806 ClimtDeltaLoad_Pw_Actl 1;
BA_ "U_CX430_MY2021_Tx" SG_ 806 ClimtDeltaLoad_Pw_Actl 1;
BA_ "U_U611_U625_MY20_Phev_Tx" SG_ 806 ClimtDeltaLoad_Pw_Actl 1;
BA_ "U_B562_MY18_Diesel_Tx" SG_ 806 ClimtDeltaLoad_Pw_Actl 1;
BA_ "U_CX482_CX483_MY20_Tx" SG_ 806 ClimtDeltaLoad_Pw_Actl 1;
BA_ "U_U611_U625_MY20_Hev_Tx" SG_ 806 ClimtDeltaLoad_Pw_Actl 1;
BA_ "U_U611_U625_MY20_Gas_Tx" SG_ 806 ClimtDeltaLoad_Pw_Actl 1;
BA_ "U_B500_MY18_Diesel_Tx" SG_ 806 ClimtDeltaLoad_Pw_Actl 1;
BA_ "U_B500_MY18_Gas_Tx" SG_ 806 ClimtDeltaLoad_Pw_Actl 1;
BA_ "U_B562_MY18_Gas_Tx" SG_ 806 ClimtDeltaLoad_Pw_Actl 1;
BA_ "U_C519_MY18_5_Gas_Tx" SG_ 806 ClimtDeltaLoad_Pw_Actl 1;
BA_ "U_C519_MY18_5_Diesel_Tx" SG_ 806 ClimtDeltaLoad_Pw_Actl 1;
BA_ "U_B515_MCA_MY17_Gas_Tx" SG_ 806 ClimtDeltaLoad_Pw_Actl 1;
BA_ "U_B515_MCA_MY17_Diesel_Tx" SG_ 806 ClimtDeltaLoad_Pw_Actl 1;
BA_ "U_B479_MY17_Diesel_Tx" SG_ 806 ClimtDeltaLoad_Pw_Actl 1;
BA_ "U_B479_MY17_Gas_Tx" SG_ 806 ClimtDeltaLoad_Pw_Actl 1;
BA_ "GenSigStartValueInteger" SG_ 806 ClimtDeltaLoad_Pw_Actl 32;
BA_ "GenSigSendType" SG_ 806 StopStrtDrvMde_B_RqBtn 3;
BA_ "U_CX727_MY2021_Tx" SG_ 806 StopStrtDrvMde_B_RqBtn 1;
BA_ "U_CX430_MY2021_Tx" SG_ 806 StopStrtDrvMde_B_RqBtn 1;
BA_ "U_U611_U625_MY20_Phev_Tx" SG_ 806 StopStrtDrvMde_B_RqBtn 1;
BA_ "U_B562_MY18_Diesel_Tx" SG_ 806 StopStrtDrvMde_B_RqBtn 1;
BA_ "U_CX482_CX483_MY20_Tx" SG_ 806 StopStrtDrvMde_B_RqBtn 1;
BA_ "U_U611_U625_MY20_Hev_Tx" SG_ 806 StopStrtDrvMde_B_RqBtn 1;
BA_ "U_U611_U625_MY20_Gas_Tx" SG_ 806 StopStrtDrvMde_B_RqBtn 1;
BA_ "U_B500_MY18_Diesel_Tx" SG_ 806 StopStrtDrvMde_B_RqBtn 1;
BA_ "U_B500_MY18_Gas_Tx" SG_ 806 StopStrtDrvMde_B_RqBtn 1;
BA_ "U_C490_MY18_Tx" SG_ 806 StopStrtDrvMde_B_RqBtn 1;
BA_ "U_B562_MY18_Gas_Tx" SG_ 806 StopStrtDrvMde_B_RqBtn 1;
BA_ "U_C519_MY18_5_Gas_Tx" SG_ 806 StopStrtDrvMde_B_RqBtn 1;
BA_ "U_C519_MY18_5_Diesel_Tx" SG_ 806 StopStrtDrvMde_B_RqBtn 1;
BA_ "U_B515_MCA_MY17_Gas_Tx" SG_ 806 StopStrtDrvMde_B_RqBtn 1;
BA_ "U_B515_MCA_MY17_Diesel_Tx" SG_ 806 StopStrtDrvMde_B_RqBtn 1;
BA_ "U_B479_MY17_Diesel_Tx" SG_ 806 StopStrtDrvMde_B_RqBtn 1;
BA_ "U_B479_MY17_Gas_Tx" SG_ 806 StopStrtDrvMde_B_RqBtn 1;
BA_ "GenSigSendType" SG_ 806 HvacHtrCore_Te_Rq 3;
BA_ "U_CX727_MY2021_Tx" SG_ 806 HvacHtrCore_Te_Rq 1;
BA_ "U_CX430_MY2021_Tx" SG_ 806 HvacHtrCore_Te_Rq 1;
BA_ "U_U611_U625_MY20_Phev_Tx" SG_ 806 HvacHtrCore_Te_Rq 1;
BA_ "U_B562_MY18_Diesel_Tx" SG_ 806 HvacHtrCore_Te_Rq 1;
BA_ "U_CX482_CX483_MY20_Tx" SG_ 806 HvacHtrCore_Te_Rq 1;
BA_ "U_U611_U625_MY20_Hev_Tx" SG_ 806 HvacHtrCore_Te_Rq 1;
BA_ "U_U611_U625_MY20_Gas_Tx" SG_ 806 HvacHtrCore_Te_Rq 1;
BA_ "U_B562_MY18_Gas_Tx" SG_ 806 HvacHtrCore_Te_Rq 1;
BA_ "U_C519_MY18_5_Gas_Tx" SG_ 806 HvacHtrCore_Te_Rq 1;
BA_ "U_C519_MY18_5_Diesel_Tx" SG_ 806 HvacHtrCore_Te_Rq 1;
BA_ "GenSigSendType" SG_ 806 WndwFrontHeat_B_Stat 3;
BA_ "U_CX727_MY2021_Tx" SG_ 806 WndwFrontHeat_B_Stat 1;
BA_ "U_CX430_MY2021_Tx" SG_ 806 WndwFrontHeat_B_Stat 1;
BA_ "U_U611_U625_MY20_Phev_Tx" SG_ 806 WndwFrontHeat_B_Stat 1;
BA_ "U_B562_MY18_Diesel_Tx" SG_ 806 WndwFrontHeat_B_Stat 1;
BA_ "U_CX482_CX483_MY20_Tx" SG_ 806 WndwFrontHeat_B_Stat 1;
BA_ "U_U611_U625_MY20_Hev_Tx" SG_ 806 WndwFrontHeat_B_Stat 1;
BA_ "U_U611_U625_MY20_Gas_Tx" SG_ 806 WndwFrontHeat_B_Stat 1;
BA_ "U_B500_MY18_Diesel_Tx" SG_ 806 WndwFrontHeat_B_Stat 1;
BA_ "U_B500_MY18_Gas_Tx" SG_ 806 WndwFrontHeat_B_Stat 1;
BA_ "U_B562_MY18_Gas_Tx" SG_ 806 WndwFrontHeat_B_Stat 1;
BA_ "U_C519_MY18_5_Gas_Tx" SG_ 806 WndwFrontHeat_B_Stat 1;
BA_ "U_C519_MY18_5_Diesel_Tx" SG_ 806 WndwFrontHeat_B_Stat 1;
BA_ "U_B515_MCA_MY17_Gas_Tx" SG_ 806 WndwFrontHeat_B_Stat 1;
BA_ "U_B515_MCA_MY17_Diesel_Tx" SG_ 806 WndwFrontHeat_B_Stat 1;
BA_ "U_B479_MY17_Diesel_Tx" SG_ 806 WndwFrontHeat_B_Stat 1;
BA_ "U_B479_MY17_Gas_Tx" SG_ 806 WndwFrontHeat_B_Stat 1;
BA_ "GenSigSendType" SG_ 806 ClimtHeat_D_Rq 3;
BA_ "U_P702_MY2021_Tx" SG_ 806 ClimtHeat_D_Rq 1;
BA_ "U_CX727_MY2021_Tx" SG_ 806 ClimtHeat_D_Rq 1;
BA_ "U_H567_MY20_Tx" SG_ 806 ClimtHeat_D_Rq 1;
BA_ "U_CX430_MY2021_Tx" SG_ 806 ClimtHeat_D_Rq 1;
BA_ "U_U611_U625_MY20_Phev_Tx" SG_ 806 ClimtHeat_D_Rq 1;
BA_ "U_B562_MY18_Diesel_Tx" SG_ 806 ClimtHeat_D_Rq 1;
BA_ "U_CX482_CX483_MY20_Tx" SG_ 806 ClimtHeat_D_Rq 1;
BA_ "U_U611_U625_MY20_Hev_Tx" SG_ 806 ClimtHeat_D_Rq 1;
BA_ "U_U611_U625_MY20_Gas_Tx" SG_ 806 ClimtHeat_D_Rq 1;
BA_ "U_B500_MY18_Diesel_Tx" SG_ 806 ClimtHeat_D_Rq 1;
BA_ "U_B500_MY18_Gas_Tx" SG_ 806 ClimtHeat_D_Rq 1;
BA_ "U_C490_MY18_Tx" SG_ 806 ClimtHeat_D_Rq 1;
BA_ "U_B562_MY18_Gas_Tx" SG_ 806 ClimtHeat_D_Rq 1;
BA_ "U_C519_MY18_5_Gas_Tx" SG_ 806 ClimtHeat_D_Rq 1;
BA_ "U_C519_MY18_5_Diesel_Tx" SG_ 806 ClimtHeat_D_Rq 1;
BA_ "U_B515_MCA_MY17_Gas_Tx" SG_ 806 ClimtHeat_D_Rq 1;
BA_ "U_B515_MCA_MY17_Diesel_Tx" SG_ 806 ClimtHeat_D_Rq 1;
BA_ "U_B479_MY17_Diesel_Tx" SG_ 806 ClimtHeat_D_Rq 1;
BA_ "U_B479_MY17_Gas_Tx" SG_ 806 ClimtHeat_D_Rq 1;
BA_ "GenSigSendType" SG_ 806 ClimtCool_D_Rq 3;
BA_ "U_P702_MY2021_Tx" SG_ 806 ClimtCool_D_Rq 1;
BA_ "U_CX727_MY2021_Tx" SG_ 806 ClimtCool_D_Rq 1;
BA_ "U_CX430_MY2021_Tx" SG_ 806 ClimtCool_D_Rq 1;
BA_ "U_U611_U625_MY20_Phev_Tx" SG_ 806 ClimtCool_D_Rq 1;
BA_ "U_B562_MY18_Diesel_Tx" SG_ 806 ClimtCool_D_Rq 1;
BA_ "U_CX482_CX483_MY20_Tx" SG_ 806 ClimtCool_D_Rq 1;
BA_ "U_U611_U625_MY20_Hev_Tx" SG_ 806 ClimtCool_D_Rq 1;
BA_ "U_U611_U625_MY20_Gas_Tx" SG_ 806 ClimtCool_D_Rq 1;
BA_ "U_B500_MY18_Diesel_Tx" SG_ 806 ClimtCool_D_Rq 1;
BA_ "U_B500_MY18_Gas_Tx" SG_ 806 ClimtCool_D_Rq 1;
BA_ "U_C490_MY18_Tx" SG_ 806 ClimtCool_D_Rq 1;
BA_ "U_B562_MY18_Gas_Tx" SG_ 806 ClimtCool_D_Rq 1;
BA_ "U_C519_MY18_5_Gas_Tx" SG_ 806 ClimtCool_D_Rq 1;
BA_ "U_C519_MY18_5_Diesel_Tx" SG_ 806 ClimtCool_D_Rq 1;
BA_ "U_B515_MCA_MY17_Gas_Tx" SG_ 806 ClimtCool_D_Rq 1;
BA_ "U_B515_MCA_MY17_Diesel_Tx" SG_ 806 ClimtCool_D_Rq 1;
BA_ "U_B479_MY17_Diesel_Tx" SG_ 806 ClimtCool_D_Rq 1;
BA_ "U_B479_MY17_Gas_Tx" SG_ 806 ClimtCool_D_Rq 1;
BA_ "GenSigSendType" SG_ 806 HvacEvap_Te_Rq 3;
BA_ "U_P702_MY2021_Tx" SG_ 806 HvacEvap_Te_Rq 1;
BA_ "U_CX727_MY2021_Tx" SG_ 806 HvacEvap_Te_Rq 1;
BA_ "U_H567_MY20_Tx" SG_ 806 HvacEvap_Te_Rq 1;
BA_ "U_CX430_MY2021_Tx" SG_ 806 HvacEvap_Te_Rq 1;
BA_ "U_U611_U625_MY20_Phev_Tx" SG_ 806 HvacEvap_Te_Rq 1;
BA_ "U_B562_MY18_Diesel_Tx" SG_ 806 HvacEvap_Te_Rq 1;
BA_ "U_CX482_CX483_MY20_Tx" SG_ 806 HvacEvap_Te_Rq 1;
BA_ "U_U611_U625_MY20_Hev_Tx" SG_ 806 HvacEvap_Te_Rq 1;
BA_ "U_U611_U625_MY20_Gas_Tx" SG_ 806 HvacEvap_Te_Rq 1;
BA_ "U_B500_MY18_Diesel_Tx" SG_ 806 HvacEvap_Te_Rq 1;
BA_ "U_B500_MY18_Gas_Tx" SG_ 806 HvacEvap_Te_Rq 1;
BA_ "U_C490_MY18_Tx" SG_ 806 HvacEvap_Te_Rq 1;
BA_ "U_B562_MY18_Gas_Tx" SG_ 806 HvacEvap_Te_Rq 1;
BA_ "U_C519_MY18_5_Gas_Tx" SG_ 806 HvacEvap_Te_Rq 1;
BA_ "U_C519_MY18_5_Diesel_Tx" SG_ 806 HvacEvap_Te_Rq 1;
BA_ "U_B515_MCA_MY17_Gas_Tx" SG_ 806 HvacEvap_Te_Rq 1;
BA_ "U_B515_MCA_MY17_Diesel_Tx" SG_ 806 HvacEvap_Te_Rq 1;
BA_ "U_B479_MY17_Diesel_Tx" SG_ 806 HvacEvap_Te_Rq 1;
BA_ "U_B479_MY17_Gas_Tx" SG_ 806 HvacEvap_Te_Rq 1;
BA_ "GenSigStartValueInteger" SG_ 806 HvacEvap_Te_Rq 400;
BA_ "GenSigSendType" SG_ 806 HvacEvap_Te_Actl 3;
BA_ "U_P702_MY2021_Tx" SG_ 806 HvacEvap_Te_Actl 1;
BA_ "U_CX727_MY2021_Tx" SG_ 806 HvacEvap_Te_Actl 1;
BA_ "U_H567_MY20_Tx" SG_ 806 HvacEvap_Te_Actl 1;
BA_ "U_CX430_MY2021_Tx" SG_ 806 HvacEvap_Te_Actl 1;
BA_ "U_U611_U625_MY20_Phev_Tx" SG_ 806 HvacEvap_Te_Actl 1;
BA_ "U_B562_MY18_Diesel_Tx" SG_ 806 HvacEvap_Te_Actl 1;
BA_ "U_CX482_CX483_MY20_Tx" SG_ 806 HvacEvap_Te_Actl 1;
BA_ "U_U611_U625_MY20_Hev_Tx" SG_ 806 HvacEvap_Te_Actl 1;
BA_ "U_U611_U625_MY20_Gas_Tx" SG_ 806 HvacEvap_Te_Actl 1;
BA_ "U_B500_MY18_Diesel_Tx" SG_ 806 HvacEvap_Te_Actl 1;
BA_ "U_B500_MY18_Gas_Tx" SG_ 806 HvacEvap_Te_Actl 1;
BA_ "U_C490_MY18_Tx" SG_ 806 HvacEvap_Te_Actl 1;
BA_ "U_B562_MY18_Gas_Tx" SG_ 806 HvacEvap_Te_Actl 1;
BA_ "U_C519_MY18_5_Gas_Tx" SG_ 806 HvacEvap_Te_Actl 1;
BA_ "U_C519_MY18_5_Diesel_Tx" SG_ 806 HvacEvap_Te_Actl 1;
BA_ "U_B515_MCA_MY17_Gas_Tx" SG_ 806 HvacEvap_Te_Actl 1;
BA_ "U_B515_MCA_MY17_Diesel_Tx" SG_ 806 HvacEvap_Te_Actl 1;
BA_ "U_B479_MY17_Diesel_Tx" SG_ 806 HvacEvap_Te_Actl 1;
BA_ "U_B479_MY17_Gas_Tx" SG_ 806 HvacEvap_Te_Actl 1;
BA_ "GenSigStartValueInteger" SG_ 806 HvacEvap_Te_Actl 400;
BA_ "GenSigSendType" SG_ 806 HvacAirCond_B_Rq 3;
BA_ "U_P702_MY2021_Tx" SG_ 806 HvacAirCond_B_Rq 1;
BA_ "U_CX727_MY2021_Tx" SG_ 806 HvacAirCond_B_Rq 1;
BA_ "U_H567_MY20_Tx" SG_ 806 HvacAirCond_B_Rq 1;
BA_ "U_CX430_MY2021_Tx" SG_ 806 HvacAirCond_B_Rq 1;
BA_ "U_U611_U625_MY20_Phev_Tx" SG_ 806 HvacAirCond_B_Rq 1;
BA_ "U_B562_MY18_Diesel_Tx" SG_ 806 HvacAirCond_B_Rq 1;
BA_ "U_CX482_CX483_MY20_Tx" SG_ 806 HvacAirCond_B_Rq 1;
BA_ "U_U611_U625_MY20_Hev_Tx" SG_ 806 HvacAirCond_B_Rq 1;
BA_ "U_U611_U625_MY20_Gas_Tx" SG_ 806 HvacAirCond_B_Rq 1;
BA_ "U_B500_MY18_Diesel_Tx" SG_ 806 HvacAirCond_B_Rq 1;
BA_ "U_B500_MY18_Gas_Tx" SG_ 806 HvacAirCond_B_Rq 1;
BA_ "U_C490_MY18_Tx" SG_ 806 HvacAirCond_B_Rq 1;
BA_ "U_B562_MY18_Gas_Tx" SG_ 806 HvacAirCond_B_Rq 1;
BA_ "U_C519_MY18_5_Gas_Tx" SG_ 806 HvacAirCond_B_Rq 1;
BA_ "U_C519_MY18_5_Diesel_Tx" SG_ 806 HvacAirCond_B_Rq 1;
BA_ "U_B515_MCA_MY17_Gas_Tx" SG_ 806 HvacAirCond_B_Rq 1;
BA_ "U_B515_MCA_MY17_Diesel_Tx" SG_ 806 HvacAirCond_B_Rq 1;
BA_ "U_B479_MY17_Diesel_Tx" SG_ 806 HvacAirCond_B_Rq 1;
BA_ "U_B479_MY17_Gas_Tx" SG_ 806 HvacAirCond_B_Rq 1;
BA_ "GenSigSendType" SG_ 806 HvacEvap_Te_Offst 3;
BA_ "U_P702_MY2021_Tx" SG_ 806 HvacEvap_Te_Offst 1;
BA_ "U_CX727_MY2021_Tx" SG_ 806 HvacEvap_Te_Offst 1;
BA_ "U_H567_MY20_Tx" SG_ 806 HvacEvap_Te_Offst 1;
BA_ "U_CX430_MY2021_Tx" SG_ 806 HvacEvap_Te_Offst 1;
BA_ "U_U611_U625_MY20_Phev_Tx" SG_ 806 HvacEvap_Te_Offst 1;
BA_ "U_B562_MY18_Diesel_Tx" SG_ 806 HvacEvap_Te_Offst 1;
BA_ "U_CX482_CX483_MY20_Tx" SG_ 806 HvacEvap_Te_Offst 1;
BA_ "U_U611_U625_MY20_Hev_Tx" SG_ 806 HvacEvap_Te_Offst 1;
BA_ "U_U611_U625_MY20_Gas_Tx" SG_ 806 HvacEvap_Te_Offst 1;
BA_ "U_B500_MY18_Diesel_Tx" SG_ 806 HvacEvap_Te_Offst 1;
BA_ "U_B500_MY18_Gas_Tx" SG_ 806 HvacEvap_Te_Offst 1;
BA_ "U_C490_MY18_Tx" SG_ 806 HvacEvap_Te_Offst 1;
BA_ "U_B562_MY18_Gas_Tx" SG_ 806 HvacEvap_Te_Offst 1;
BA_ "U_C519_MY18_5_Gas_Tx" SG_ 806 HvacEvap_Te_Offst 1;
BA_ "U_C519_MY18_5_Diesel_Tx" SG_ 806 HvacEvap_Te_Offst 1;
BA_ "U_B515_MCA_MY17_Gas_Tx" SG_ 806 HvacEvap_Te_Offst 1;
BA_ "U_B515_MCA_MY17_Diesel_Tx" SG_ 806 HvacEvap_Te_Offst 1;
BA_ "U_B479_MY17_Diesel_Tx" SG_ 806 HvacEvap_Te_Offst 1;
BA_ "U_B479_MY17_Gas_Tx" SG_ 806 HvacEvap_Te_Offst 1;
BA_ "GenSigStartValueInteger" SG_ 806 HvacEvap_Te_Offst 400;
BA_ "GenSigSendType" SG_ 806 ClimtPw_B_Rq 3;
BA_ "U_CX727_MY2021_Tx" SG_ 806 ClimtPw_B_Rq 1;
BA_ "U_CX430_MY2021_Tx" SG_ 806 ClimtPw_B_Rq 1;
BA_ "U_U611_U625_MY20_Phev_Tx" SG_ 806 ClimtPw_B_Rq 1;
BA_ "U_B562_MY18_Diesel_Tx" SG_ 806 ClimtPw_B_Rq 1;
BA_ "U_CX482_CX483_MY20_Tx" SG_ 806 ClimtPw_B_Rq 1;
BA_ "U_U611_U625_MY20_Hev_Tx" SG_ 806 ClimtPw_B_Rq 1;
BA_ "U_U611_U625_MY20_Gas_Tx" SG_ 806 ClimtPw_B_Rq 1;
BA_ "U_B500_MY18_Diesel_Tx" SG_ 806 ClimtPw_B_Rq 1;
BA_ "U_B500_MY18_Gas_Tx" SG_ 806 ClimtPw_B_Rq 1;
BA_ "U_C490_MY18_Tx" SG_ 806 ClimtPw_B_Rq 1;
BA_ "U_B562_MY18_Gas_Tx" SG_ 806 ClimtPw_B_Rq 1;
BA_ "U_C519_MY18_5_Gas_Tx" SG_ 806 ClimtPw_B_Rq 1;
BA_ "U_C519_MY18_5_Diesel_Tx" SG_ 806 ClimtPw_B_Rq 1;
BA_ "U_B515_MCA_MY17_Gas_Tx" SG_ 806 ClimtPw_B_Rq 1;
BA_ "U_B515_MCA_MY17_Diesel_Tx" SG_ 806 ClimtPw_B_Rq 1;
BA_ "U_B479_MY17_Diesel_Tx" SG_ 806 ClimtPw_B_Rq 1;
BA_ "U_B479_MY17_Gas_Tx" SG_ 806 ClimtPw_B_Rq 1;
BA_ "U_P702_MY2021_Rx" SG_ 950 RemoteKey_Info_TIC 1;
BA_ "U_CX727_MY2021_Rx" SG_ 950 RemoteKey_Info_TIC 1;
BA_ "U_VN127_MY20_Rx" SG_ 950 RemoteKey_Info_TIC 1;
BA_ "U_H567_MY20_Rx" SG_ 950 RemoteKey_Info_TIC 1;
BA_ "U_CX430_MY2021_Rx" SG_ 950 RemoteKey_Info_TIC 1;
BA_ "U_U611_U625_MY20_Phev_Rx" SG_ 950 RemoteKey_Info_TIC 1;
BA_ "U_CX482_CX483_MY20_Rx" SG_ 950 RemoteKey_Info_TIC 1;
BA_ "U_U611_U625_MY20_Hev_Rx" SG_ 950 RemoteKey_Info_TIC 1;
BA_ "U_U611_U625_MY20_Gas_Rx" SG_ 950 RemoteKey_Info_TIC 1;
BA_ "U_C519_MY18_5_Gas_Rx" SG_ 950 RemoteKey_Info_TIC 1;
BA_ "U_C519_MY18_5_Diesel_Rx" SG_ 950 RemoteKey_Info_TIC 1;
BA_ "U_B515_MCA_MY17_Gas_Rx" SG_ 950 RemoteKey_Info_TIC 1;
BA_ "U_B515_MCA_MY17_Diesel_Rx" SG_ 950 RemoteKey_Info_TIC 1;
BA_ "U_B479_MY17_Diesel_Rx" SG_ 950 RemoteKey_Info_TIC 1;
BA_ "U_B479_MY17_Gas_Rx" SG_ 950 RemoteKey_Info_TIC 1;
BA_ "U_P702_MY2021_Rx" SG_ 950 RemoteKey_Info_MaxInd 1;
BA_ "U_CX727_MY2021_Rx" SG_ 950 RemoteKey_Info_MaxInd 1;
BA_ "U_VN127_MY20_Rx" SG_ 950 RemoteKey_Info_MaxInd 1;
BA_ "U_H567_MY20_Rx" SG_ 950 RemoteKey_Info_MaxInd 1;
BA_ "U_CX430_MY2021_Rx" SG_ 950 RemoteKey_Info_MaxInd 1;
BA_ "U_U611_U625_MY20_Phev_Rx" SG_ 950 RemoteKey_Info_MaxInd 1;
BA_ "U_CX482_CX483_MY20_Rx" SG_ 950 RemoteKey_Info_MaxInd 1;
BA_ "U_U611_U625_MY20_Hev_Rx" SG_ 950 RemoteKey_Info_MaxInd 1;
BA_ "U_U611_U625_MY20_Gas_Rx" SG_ 950 RemoteKey_Info_MaxInd 1;
BA_ "U_C519_MY18_5_Gas_Rx" SG_ 950 RemoteKey_Info_MaxInd 1;
BA_ "U_C519_MY18_5_Diesel_Rx" SG_ 950 RemoteKey_Info_MaxInd 1;
BA_ "U_B515_MCA_MY17_Gas_Rx" SG_ 950 RemoteKey_Info_MaxInd 1;
BA_ "U_B515_MCA_MY17_Diesel_Rx" SG_ 950 RemoteKey_Info_MaxInd 1;
BA_ "U_B479_MY17_Diesel_Rx" SG_ 950 RemoteKey_Info_MaxInd 1;
BA_ "U_B479_MY17_Gas_Rx" SG_ 950 RemoteKey_Info_MaxInd 1;
BA_ "U_P702_MY2021_Rx" SG_ 950 RemoteKey_Info_Index 1;
BA_ "U_CX727_MY2021_Rx" SG_ 950 RemoteKey_Info_Index 1;
BA_ "U_VN127_MY20_Rx" SG_ 950 RemoteKey_Info_Index 1;
BA_ "U_H567_MY20_Rx" SG_ 950 RemoteKey_Info_Index 1;
BA_ "U_CX430_MY2021_Rx" SG_ 950 RemoteKey_Info_Index 1;
BA_ "U_U611_U625_MY20_Phev_Rx" SG_ 950 RemoteKey_Info_Index 1;
BA_ "U_CX482_CX483_MY20_Rx" SG_ 950 RemoteKey_Info_Index 1;
BA_ "U_U611_U625_MY20_Hev_Rx" SG_ 950 RemoteKey_Info_Index 1;
BA_ "U_U611_U625_MY20_Gas_Rx" SG_ 950 RemoteKey_Info_Index 1;
BA_ "U_C519_MY18_5_Gas_Rx" SG_ 950 RemoteKey_Info_Index 1;
BA_ "U_C519_MY18_5_Diesel_Rx" SG_ 950 RemoteKey_Info_Index 1;
BA_ "U_B515_MCA_MY17_Gas_Rx" SG_ 950 RemoteKey_Info_Index 1;
BA_ "U_B515_MCA_MY17_Diesel_Rx" SG_ 950 RemoteKey_Info_Index 1;
BA_ "U_B479_MY17_Diesel_Rx" SG_ 950 RemoteKey_Info_Index 1;
BA_ "U_B479_MY17_Gas_Rx" SG_ 950 RemoteKey_Info_Index 1;
BA_ "U_P702_MY2021_Rx" SG_ 950 TirePress_Filter_Ctrl 1;
BA_ "U_CX727_MY2021_Rx" SG_ 950 TirePress_Filter_Ctrl 1;
BA_ "U_VN127_MY20_Rx" SG_ 950 TirePress_Filter_Ctrl 1;
BA_ "U_H567_MY20_Rx" SG_ 950 TirePress_Filter_Ctrl 1;
BA_ "U_CX430_MY2021_Rx" SG_ 950 TirePress_Filter_Ctrl 1;
BA_ "U_U611_U625_MY20_Phev_Rx" SG_ 950 TirePress_Filter_Ctrl 1;
BA_ "U_CX482_CX483_MY20_Rx" SG_ 950 TirePress_Filter_Ctrl 1;
BA_ "U_U611_U625_MY20_Hev_Rx" SG_ 950 TirePress_Filter_Ctrl 1;
BA_ "U_U611_U625_MY20_Gas_Rx" SG_ 950 TirePress_Filter_Ctrl 1;
BA_ "U_C519_MY18_5_Gas_Rx" SG_ 950 TirePress_Filter_Ctrl 1;
BA_ "U_C519_MY18_5_Diesel_Rx" SG_ 950 TirePress_Filter_Ctrl 1;
BA_ "U_B515_MCA_MY17_Gas_Rx" SG_ 950 TirePress_Filter_Ctrl 1;
BA_ "U_B515_MCA_MY17_Diesel_Rx" SG_ 950 TirePress_Filter_Ctrl 1;
BA_ "U_B479_MY17_Diesel_Rx" SG_ 950 TirePress_Filter_Ctrl 1;
BA_ "U_B479_MY17_Gas_Rx" SG_ 950 TirePress_Filter_Ctrl 1;
BA_ "GenSigStartValue" SG_ 950 TirePress_Filter_Ctrl 2;
BA_ "GenSigStartValueInteger" SG_ 950 TirePress_Filter_Ctrl 2;
BA_ "U_P702_MY2021_Rx" SG_ 857 LHS_Temp_Disp_Digit3 1;
BA_ "U_CX727_MY2021_Rx" SG_ 857 LHS_Temp_Disp_Digit3 1;
BA_ "U_CX430_MY2021_Rx" SG_ 857 LHS_Temp_Disp_Digit3 1;
BA_ "U_U611_U625_MY20_Phev_Rx" SG_ 857 LHS_Temp_Disp_Digit3 1;
BA_ "U_B562_MY18_Diesel_Rx" SG_ 857 LHS_Temp_Disp_Digit3 1;
BA_ "U_CX482_CX483_MY20_Rx" SG_ 857 LHS_Temp_Disp_Digit3 1;
BA_ "U_U611_U625_MY20_Hev_Rx" SG_ 857 LHS_Temp_Disp_Digit3 1;
BA_ "U_U611_U625_MY20_Gas_Rx" SG_ 857 LHS_Temp_Disp_Digit3 1;
BA_ "U_B500_MY18_Diesel_Rx" SG_ 857 LHS_Temp_Disp_Digit3 1;
BA_ "U_B500_MY18_Gas_Rx" SG_ 857 LHS_Temp_Disp_Digit3 1;
BA_ "U_B562_MY18_Gas_Rx" SG_ 857 LHS_Temp_Disp_Digit3 1;
BA_ "U_C519_MY18_5_Gas_Rx" SG_ 857 LHS_Temp_Disp_Digit3 1;
BA_ "U_C519_MY18_5_Diesel_Rx" SG_ 857 LHS_Temp_Disp_Digit3 1;
BA_ "U_B515_MCA_MY17_Gas_Rx" SG_ 857 LHS_Temp_Disp_Digit3 1;
BA_ "U_B515_MCA_MY17_Diesel_Rx" SG_ 857 LHS_Temp_Disp_Digit3 1;
BA_ "U_B479_MY17_Diesel_Rx" SG_ 857 LHS_Temp_Disp_Digit3 1;
BA_ "U_B479_MY17_Gas_Rx" SG_ 857 LHS_Temp_Disp_Digit3 1;
BA_ "GenSigSendType" SG_ 857 LHS_Temp_Disp_Digit3 3;
BA_ "CrossOver_InfoCAN" SG_ 857 LHS_Temp_Disp_Digit3 1;
BA_ "U_P702_MY2021_Rx" SG_ 857 LHS_Temp_Disp_Digit2 1;
BA_ "U_CX727_MY2021_Rx" SG_ 857 LHS_Temp_Disp_Digit2 1;
BA_ "U_CX430_MY2021_Rx" SG_ 857 LHS_Temp_Disp_Digit2 1;
BA_ "U_U611_U625_MY20_Phev_Rx" SG_ 857 LHS_Temp_Disp_Digit2 1;
BA_ "U_B562_MY18_Diesel_Rx" SG_ 857 LHS_Temp_Disp_Digit2 1;
BA_ "U_CX482_CX483_MY20_Rx" SG_ 857 LHS_Temp_Disp_Digit2 1;
BA_ "U_U611_U625_MY20_Hev_Rx" SG_ 857 LHS_Temp_Disp_Digit2 1;
BA_ "U_U611_U625_MY20_Gas_Rx" SG_ 857 LHS_Temp_Disp_Digit2 1;
BA_ "U_B500_MY18_Diesel_Rx" SG_ 857 LHS_Temp_Disp_Digit2 1;
BA_ "U_B500_MY18_Gas_Rx" SG_ 857 LHS_Temp_Disp_Digit2 1;
BA_ "U_B562_MY18_Gas_Rx" SG_ 857 LHS_Temp_Disp_Digit2 1;
BA_ "U_C519_MY18_5_Gas_Rx" SG_ 857 LHS_Temp_Disp_Digit2 1;
BA_ "U_C519_MY18_5_Diesel_Rx" SG_ 857 LHS_Temp_Disp_Digit2 1;
BA_ "U_B515_MCA_MY17_Gas_Rx" SG_ 857 LHS_Temp_Disp_Digit2 1;
BA_ "U_B515_MCA_MY17_Diesel_Rx" SG_ 857 LHS_Temp_Disp_Digit2 1;
BA_ "U_B479_MY17_Diesel_Rx" SG_ 857 LHS_Temp_Disp_Digit2 1;
BA_ "U_B479_MY17_Gas_Rx" SG_ 857 LHS_Temp_Disp_Digit2 1;
BA_ "GenSigSendType" SG_ 857 LHS_Temp_Disp_Digit2 3;
BA_ "CrossOver_InfoCAN" SG_ 857 LHS_Temp_Disp_Digit2 1;
BA_ "U_P702_MY2021_Rx" SG_ 857 LHS_Temp_Disp_Digit1 1;
BA_ "U_CX727_MY2021_Rx" SG_ 857 LHS_Temp_Disp_Digit1 1;
BA_ "U_CX430_MY2021_Rx" SG_ 857 LHS_Temp_Disp_Digit1 1;
BA_ "U_U611_U625_MY20_Phev_Rx" SG_ 857 LHS_Temp_Disp_Digit1 1;
BA_ "U_B562_MY18_Diesel_Rx" SG_ 857 LHS_Temp_Disp_Digit1 1;
BA_ "U_CX482_CX483_MY20_Rx" SG_ 857 LHS_Temp_Disp_Digit1 1;
BA_ "U_U611_U625_MY20_Hev_Rx" SG_ 857 LHS_Temp_Disp_Digit1 1;
BA_ "U_U611_U625_MY20_Gas_Rx" SG_ 857 LHS_Temp_Disp_Digit1 1;
BA_ "U_B500_MY18_Diesel_Rx" SG_ 857 LHS_Temp_Disp_Digit1 1;
BA_ "U_B500_MY18_Gas_Rx" SG_ 857 LHS_Temp_Disp_Digit1 1;
BA_ "U_B562_MY18_Gas_Rx" SG_ 857 LHS_Temp_Disp_Digit1 1;
BA_ "U_C519_MY18_5_Gas_Rx" SG_ 857 LHS_Temp_Disp_Digit1 1;
BA_ "U_C519_MY18_5_Diesel_Rx" SG_ 857 LHS_Temp_Disp_Digit1 1;
BA_ "U_B515_MCA_MY17_Gas_Rx" SG_ 857 LHS_Temp_Disp_Digit1 1;
BA_ "U_B515_MCA_MY17_Diesel_Rx" SG_ 857 LHS_Temp_Disp_Digit1 1;
BA_ "U_B479_MY17_Diesel_Rx" SG_ 857 LHS_Temp_Disp_Digit1 1;
BA_ "U_B479_MY17_Gas_Rx" SG_ 857 LHS_Temp_Disp_Digit1 1;
BA_ "GenSigSendType" SG_ 857 LHS_Temp_Disp_Digit1 3;
BA_ "CrossOver_InfoCAN" SG_ 857 LHS_Temp_Disp_Digit1 1;
BA_ "U_P702_MY2021_Rx" SG_ 857 Front_Blower_Ind 1;
BA_ "U_CX727_MY2021_Rx" SG_ 857 Front_Blower_Ind 1;
BA_ "U_CX430_MY2021_Rx" SG_ 857 Front_Blower_Ind 1;
BA_ "U_U611_U625_MY20_Phev_Rx" SG_ 857 Front_Blower_Ind 1;
BA_ "U_B562_MY18_Diesel_Rx" SG_ 857 Front_Blower_Ind 1;
BA_ "U_CX482_CX483_MY20_Rx" SG_ 857 Front_Blower_Ind 1;
BA_ "U_U611_U625_MY20_Hev_Rx" SG_ 857 Front_Blower_Ind 1;
BA_ "U_U611_U625_MY20_Gas_Rx" SG_ 857 Front_Blower_Ind 1;
BA_ "U_B500_MY18_Diesel_Rx" SG_ 857 Front_Blower_Ind 1;
BA_ "U_B500_MY18_Gas_Rx" SG_ 857 Front_Blower_Ind 1;
BA_ "U_B562_MY18_Gas_Rx" SG_ 857 Front_Blower_Ind 1;
BA_ "U_C519_MY18_5_Gas_Rx" SG_ 857 Front_Blower_Ind 1;
BA_ "U_C519_MY18_5_Diesel_Rx" SG_ 857 Front_Blower_Ind 1;
BA_ "U_B515_MCA_MY17_Gas_Rx" SG_ 857 Front_Blower_Ind 1;
BA_ "U_B515_MCA_MY17_Diesel_Rx" SG_ 857 Front_Blower_Ind 1;
BA_ "U_B479_MY17_Diesel_Rx" SG_ 857 Front_Blower_Ind 1;
BA_ "U_B479_MY17_Gas_Rx" SG_ 857 Front_Blower_Ind 1;
BA_ "GenSigSendType" SG_ 857 Front_Blower_Ind 3;
BA_ "GenSigStartValue" SG_ 857 Front_Blower_Ind 15;
BA_ "GenSigStartValueInteger" SG_ 857 Front_Blower_Ind 15;
BA_ "CrossOver_InfoCAN" SG_ 857 Front_Blower_Ind 1;
BA_ "U_P702_MY2021_Rx" SG_ 857 EATC_LHS_Unit 1;
BA_ "U_CX727_MY2021_Rx" SG_ 857 EATC_LHS_Unit 1;
BA_ "U_CX430_MY2021_Rx" SG_ 857 EATC_LHS_Unit 1;
BA_ "U_U611_U625_MY20_Phev_Rx" SG_ 857 EATC_LHS_Unit 1;
BA_ "U_B562_MY18_Diesel_Rx" SG_ 857 EATC_LHS_Unit 1;
BA_ "U_CX482_CX483_MY20_Rx" SG_ 857 EATC_LHS_Unit 1;
BA_ "U_U611_U625_MY20_Hev_Rx" SG_ 857 EATC_LHS_Unit 1;
BA_ "U_U611_U625_MY20_Gas_Rx" SG_ 857 EATC_LHS_Unit 1;
BA_ "U_B500_MY18_Diesel_Rx" SG_ 857 EATC_LHS_Unit 1;
BA_ "U_B500_MY18_Gas_Rx" SG_ 857 EATC_LHS_Unit 1;
BA_ "U_B562_MY18_Gas_Rx" SG_ 857 EATC_LHS_Unit 1;
BA_ "U_C519_MY18_5_Gas_Rx" SG_ 857 EATC_LHS_Unit 1;
BA_ "U_C519_MY18_5_Diesel_Rx" SG_ 857 EATC_LHS_Unit 1;
BA_ "U_B515_MCA_MY17_Gas_Rx" SG_ 857 EATC_LHS_Unit 1;
BA_ "U_B515_MCA_MY17_Diesel_Rx" SG_ 857 EATC_LHS_Unit 1;
BA_ "U_B479_MY17_Diesel_Rx" SG_ 857 EATC_LHS_Unit 1;
BA_ "U_B479_MY17_Gas_Rx" SG_ 857 EATC_LHS_Unit 1;
BA_ "GenSigSendType" SG_ 857 EATC_LHS_Unit 3;
BA_ "CrossOver_InfoCAN" SG_ 857 EATC_LHS_Unit 1;
BA_ "CrossOver_InfoCAN" SG_ 856 Rr_Btn_Status_2nd 1;
BA_ "CrossOver_InfoCAN" SG_ 856 Rr_Btn_Status_1st 1;
BA_ "GenSigSendType" SG_ 856 Frt_Btn_Status_2nd 3;
BA_ "U_P702_MY2021_Rx" SG_ 856 Frt_Btn_Status_2nd 1;
BA_ "U_CX727_MY2021_Rx" SG_ 856 Frt_Btn_Status_2nd 1;
BA_ "U_CX430_MY2021_Rx" SG_ 856 Frt_Btn_Status_2nd 1;
BA_ "U_U611_U625_MY20_Phev_Rx" SG_ 856 Frt_Btn_Status_2nd 1;
BA_ "U_B562_MY18_Diesel_Rx" SG_ 856 Frt_Btn_Status_2nd 1;
BA_ "U_CX482_CX483_MY20_Rx" SG_ 856 Frt_Btn_Status_2nd 1;
BA_ "U_U611_U625_MY20_Hev_Rx" SG_ 856 Frt_Btn_Status_2nd 1;
BA_ "U_U611_U625_MY20_Gas_Rx" SG_ 856 Frt_Btn_Status_2nd 1;
BA_ "U_B500_MY18_Diesel_Rx" SG_ 856 Frt_Btn_Status_2nd 1;
BA_ "U_B500_MY18_Gas_Rx" SG_ 856 Frt_Btn_Status_2nd 1;
BA_ "U_B562_MY18_Gas_Rx" SG_ 856 Frt_Btn_Status_2nd 1;
BA_ "U_C519_MY18_5_Gas_Rx" SG_ 856 Frt_Btn_Status_2nd 1;
BA_ "U_C519_MY18_5_Diesel_Rx" SG_ 856 Frt_Btn_Status_2nd 1;
BA_ "U_B515_MCA_MY17_Gas_Rx" SG_ 856 Frt_Btn_Status_2nd 1;
BA_ "U_B515_MCA_MY17_Diesel_Rx" SG_ 856 Frt_Btn_Status_2nd 1;
BA_ "U_B479_MY17_Diesel_Rx" SG_ 856 Frt_Btn_Status_2nd 1;
BA_ "U_B479_MY17_Gas_Rx" SG_ 856 Frt_Btn_Status_2nd 1;
BA_ "CrossOver_InfoCAN" SG_ 856 Frt_Btn_Status_2nd 1;
BA_ "GenSigSendType" SG_ 856 Frt_Btn_Status_1st 3;
BA_ "U_P702_MY2021_Rx" SG_ 856 Frt_Btn_Status_1st 1;
BA_ "U_CX727_MY2021_Rx" SG_ 856 Frt_Btn_Status_1st 1;
BA_ "U_CX430_MY2021_Rx" SG_ 856 Frt_Btn_Status_1st 1;
BA_ "U_U611_U625_MY20_Phev_Rx" SG_ 856 Frt_Btn_Status_1st 1;
BA_ "U_B562_MY18_Diesel_Rx" SG_ 856 Frt_Btn_Status_1st 1;
BA_ "U_CX482_CX483_MY20_Rx" SG_ 856 Frt_Btn_Status_1st 1;
BA_ "U_U611_U625_MY20_Hev_Rx" SG_ 856 Frt_Btn_Status_1st 1;
BA_ "U_U611_U625_MY20_Gas_Rx" SG_ 856 Frt_Btn_Status_1st 1;
BA_ "U_B500_MY18_Diesel_Rx" SG_ 856 Frt_Btn_Status_1st 1;
BA_ "U_B500_MY18_Gas_Rx" SG_ 856 Frt_Btn_Status_1st 1;
BA_ "U_B562_MY18_Gas_Rx" SG_ 856 Frt_Btn_Status_1st 1;
BA_ "U_C519_MY18_5_Gas_Rx" SG_ 856 Frt_Btn_Status_1st 1;
BA_ "U_C519_MY18_5_Diesel_Rx" SG_ 856 Frt_Btn_Status_1st 1;
BA_ "U_B515_MCA_MY17_Gas_Rx" SG_ 856 Frt_Btn_Status_1st 1;
BA_ "U_B515_MCA_MY17_Diesel_Rx" SG_ 856 Frt_Btn_Status_1st 1;
BA_ "U_B479_MY17_Diesel_Rx" SG_ 856 Frt_Btn_Status_1st 1;
BA_ "U_B479_MY17_Gas_Rx" SG_ 856 Frt_Btn_Status_1st 1;
BA_ "CrossOver_InfoCAN" SG_ 856 Frt_Btn_Status_1st 1;
BA_ "GenSigSendType" SG_ 856 Frt_Blower_Speed 3;
BA_ "U_P702_MY2021_Rx" SG_ 856 Frt_Blower_Speed 1;
BA_ "U_CX727_MY2021_Rx" SG_ 856 Frt_Blower_Speed 1;
BA_ "U_CX430_MY2021_Rx" SG_ 856 Frt_Blower_Speed 1;
BA_ "U_U611_U625_MY20_Phev_Rx" SG_ 856 Frt_Blower_Speed 1;
BA_ "U_B562_MY18_Diesel_Rx" SG_ 856 Frt_Blower_Speed 1;
BA_ "U_CX482_CX483_MY20_Rx" SG_ 856 Frt_Blower_Speed 1;
BA_ "U_U611_U625_MY20_Hev_Rx" SG_ 856 Frt_Blower_Speed 1;
BA_ "U_U611_U625_MY20_Gas_Rx" SG_ 856 Frt_Blower_Speed 1;
BA_ "U_B500_MY18_Diesel_Rx" SG_ 856 Frt_Blower_Speed 1;
BA_ "U_B500_MY18_Gas_Rx" SG_ 856 Frt_Blower_Speed 1;
BA_ "U_B562_MY18_Gas_Rx" SG_ 856 Frt_Blower_Speed 1;
BA_ "U_C519_MY18_5_Gas_Rx" SG_ 856 Frt_Blower_Speed 1;
BA_ "U_C519_MY18_5_Diesel_Rx" SG_ 856 Frt_Blower_Speed 1;
BA_ "U_B515_MCA_MY17_Gas_Rx" SG_ 856 Frt_Blower_Speed 1;
BA_ "U_B515_MCA_MY17_Diesel_Rx" SG_ 856 Frt_Blower_Speed 1;
BA_ "U_B479_MY17_Diesel_Rx" SG_ 856 Frt_Blower_Speed 1;
BA_ "U_B479_MY17_Gas_Rx" SG_ 856 Frt_Blower_Speed 1;
BA_ "CrossOver_InfoCAN" SG_ 856 Frt_Blower_Speed 1;
BA_ "GenSigSendType" SG_ 856 Drv_Set_Temp 3;
BA_ "U_P702_MY2021_Rx" SG_ 856 Drv_Set_Temp 1;
BA_ "U_CX727_MY2021_Rx" SG_ 856 Drv_Set_Temp 1;
BA_ "U_CX430_MY2021_Rx" SG_ 856 Drv_Set_Temp 1;
BA_ "U_U611_U625_MY20_Phev_Rx" SG_ 856 Drv_Set_Temp 1;
BA_ "U_B562_MY18_Diesel_Rx" SG_ 856 Drv_Set_Temp 1;
BA_ "U_CX482_CX483_MY20_Rx" SG_ 856 Drv_Set_Temp 1;
BA_ "U_U611_U625_MY20_Hev_Rx" SG_ 856 Drv_Set_Temp 1;
BA_ "U_U611_U625_MY20_Gas_Rx" SG_ 856 Drv_Set_Temp 1;
BA_ "U_B500_MY18_Diesel_Rx" SG_ 856 Drv_Set_Temp 1;
BA_ "U_B500_MY18_Gas_Rx" SG_ 856 Drv_Set_Temp 1;
BA_ "U_B562_MY18_Gas_Rx" SG_ 856 Drv_Set_Temp 1;
BA_ "U_C519_MY18_5_Gas_Rx" SG_ 856 Drv_Set_Temp 1;
BA_ "U_C519_MY18_5_Diesel_Rx" SG_ 856 Drv_Set_Temp 1;
BA_ "U_B515_MCA_MY17_Gas_Rx" SG_ 856 Drv_Set_Temp 1;
BA_ "U_B515_MCA_MY17_Diesel_Rx" SG_ 856 Drv_Set_Temp 1;
BA_ "U_B479_MY17_Diesel_Rx" SG_ 856 Drv_Set_Temp 1;
BA_ "U_B479_MY17_Gas_Rx" SG_ 856 Drv_Set_Temp 1;
BA_ "CrossOver_InfoCAN" SG_ 856 Drv_Set_Temp 1;
BA_ "U_CX727_MY2021_Tx" SG_ 854 SelDrvMdeSwtch_D_Stat2 1;
BA_ "U_CX430_MY2021_Tx" SG_ 854 SelDrvMdeSwtch_D_Stat2 1;
BA_ "U_U611_U625_MY20_Phev_Tx" SG_ 854 SelDrvMdeSwtch_D_Stat2 1;
BA_ "U_CX482_CX483_MY20_Tx" SG_ 854 SelDrvMdeSwtch_D_Stat2 1;
BA_ "U_U611_U625_MY20_Hev_Tx" SG_ 854 SelDrvMdeSwtch_D_Stat2 1;
BA_ "U_U611_U625_MY20_Gas_Tx" SG_ 854 SelDrvMdeSwtch_D_Stat2 1;
BA_ "U_B500_MY18_Diesel_Tx" SG_ 854 SelDrvMdeSwtch_D_Stat2 1;
BA_ "U_B500_MY18_Gas_Tx" SG_ 854 SelDrvMdeSwtch_D_Stat2 1;
BA_ "U_C519_MY18_5_Gas_Tx" SG_ 854 SelDrvMdeSwtch_D_Stat2 1;
BA_ "U_C519_MY18_5_Diesel_Tx" SG_ 854 SelDrvMdeSwtch_D_Stat2 1;
BA_ "U_B515_MCA_MY17_Gas_Tx" SG_ 854 SelDrvMdeSwtch_D_Stat2 1;
BA_ "U_B515_MCA_MY17_Diesel_Tx" SG_ 854 SelDrvMdeSwtch_D_Stat2 1;
BA_ "U_B479_MY17_Diesel_Tx" SG_ 854 SelDrvMdeSwtch_D_Stat2 1;
BA_ "U_B479_MY17_Gas_Tx" SG_ 854 SelDrvMdeSwtch_D_Stat2 1;
BA_ "GenSigSendType" SG_ 854 SelDrvMdeSwtch_D_Stat2 3;
BA_ "U_P702_MY2021_Tx" SG_ 854 CC_Fr_Stat_User_Adj 1;
BA_ "U_CX727_MY2021_Tx" SG_ 854 CC_Fr_Stat_User_Adj 1;
BA_ "U_CX430_MY2021_Tx" SG_ 854 CC_Fr_Stat_User_Adj 1;
BA_ "U_U611_U625_MY20_Phev_Tx" SG_ 854 CC_Fr_Stat_User_Adj 1;
BA_ "U_B562_MY18_Diesel_Tx" SG_ 854 CC_Fr_Stat_User_Adj 1;
BA_ "U_CX482_CX483_MY20_Tx" SG_ 854 CC_Fr_Stat_User_Adj 1;
BA_ "U_U611_U625_MY20_Hev_Tx" SG_ 854 CC_Fr_Stat_User_Adj 1;
BA_ "U_U611_U625_MY20_Gas_Tx" SG_ 854 CC_Fr_Stat_User_Adj 1;
BA_ "U_B500_MY18_Diesel_Tx" SG_ 854 CC_Fr_Stat_User_Adj 1;
BA_ "U_B500_MY18_Gas_Tx" SG_ 854 CC_Fr_Stat_User_Adj 1;
BA_ "U_B562_MY18_Gas_Tx" SG_ 854 CC_Fr_Stat_User_Adj 1;
BA_ "U_C519_MY18_5_Gas_Tx" SG_ 854 CC_Fr_Stat_User_Adj 1;
BA_ "U_C519_MY18_5_Diesel_Tx" SG_ 854 CC_Fr_Stat_User_Adj 1;
BA_ "U_B515_MCA_MY17_Gas_Tx" SG_ 854 CC_Fr_Stat_User_Adj 1;
BA_ "U_B515_MCA_MY17_Diesel_Tx" SG_ 854 CC_Fr_Stat_User_Adj 1;
BA_ "U_B479_MY17_Diesel_Tx" SG_ 854 CC_Fr_Stat_User_Adj 1;
BA_ "U_B479_MY17_Gas_Tx" SG_ 854 CC_Fr_Stat_User_Adj 1;
BA_ "GenSigSendType" SG_ 854 CC_Fr_Stat_User_Adj 3;
BA_ "CrossOver_InfoCAN" SG_ 854 CC_Fr_Stat_User_Adj 1;
BA_ "U_P702_MY2021_Tx" SG_ 854 Front_Blower_Indicate 1;
BA_ "U_CX727_MY2021_Tx" SG_ 854 Front_Blower_Indicate 1;
BA_ "U_CX430_MY2021_Tx" SG_ 854 Front_Blower_Indicate 1;
BA_ "U_U611_U625_MY20_Phev_Tx" SG_ 854 Front_Blower_Indicate 1;
BA_ "U_B562_MY18_Diesel_Tx" SG_ 854 Front_Blower_Indicate 1;
BA_ "U_CX482_CX483_MY20_Tx" SG_ 854 Front_Blower_Indicate 1;
BA_ "U_U611_U625_MY20_Hev_Tx" SG_ 854 Front_Blower_Indicate 1;
BA_ "U_U611_U625_MY20_Gas_Tx" SG_ 854 Front_Blower_Indicate 1;
BA_ "U_B500_MY18_Diesel_Tx" SG_ 854 Front_Blower_Indicate 1;
BA_ "U_B500_MY18_Gas_Tx" SG_ 854 Front_Blower_Indicate 1;
BA_ "U_B562_MY18_Gas_Tx" SG_ 854 Front_Blower_Indicate 1;
BA_ "U_C519_MY18_5_Gas_Tx" SG_ 854 Front_Blower_Indicate 1;
BA_ "U_C519_MY18_5_Diesel_Tx" SG_ 854 Front_Blower_Indicate 1;
BA_ "U_B515_MCA_MY17_Gas_Tx" SG_ 854 Front_Blower_Indicate 1;
BA_ "U_B515_MCA_MY17_Diesel_Tx" SG_ 854 Front_Blower_Indicate 1;
BA_ "U_B479_MY17_Diesel_Tx" SG_ 854 Front_Blower_Indicate 1;
BA_ "U_B479_MY17_Gas_Tx" SG_ 854 Front_Blower_Indicate 1;
BA_ "GenSigSendType" SG_ 854 Front_Blower_Indicate 3;
BA_ "GenSigStartValue" SG_ 854 Front_Blower_Indicate 15;
BA_ "GenSigStartValueInteger" SG_ 854 Front_Blower_Indicate 15;
BA_ "CrossOver_InfoCAN" SG_ 854 Front_Blower_Indicate 1;
BA_ "U_P702_MY2021_Tx" SG_ 854 CC_Diagnostics_Active 1;
BA_ "U_CX727_MY2021_Tx" SG_ 854 CC_Diagnostics_Active 1;
BA_ "U_CX430_MY2021_Tx" SG_ 854 CC_Diagnostics_Active 1;
BA_ "U_U611_U625_MY20_Phev_Tx" SG_ 854 CC_Diagnostics_Active 1;
BA_ "U_B562_MY18_Diesel_Tx" SG_ 854 CC_Diagnostics_Active 1;
BA_ "U_CX482_CX483_MY20_Tx" SG_ 854 CC_Diagnostics_Active 1;
BA_ "U_U611_U625_MY20_Hev_Tx" SG_ 854 CC_Diagnostics_Active 1;
BA_ "U_U611_U625_MY20_Gas_Tx" SG_ 854 CC_Diagnostics_Active 1;
BA_ "U_B500_MY18_Diesel_Tx" SG_ 854 CC_Diagnostics_Active 1;
BA_ "U_B500_MY18_Gas_Tx" SG_ 854 CC_Diagnostics_Active 1;
BA_ "U_B562_MY18_Gas_Tx" SG_ 854 CC_Diagnostics_Active 1;
BA_ "U_C519_MY18_5_Gas_Tx" SG_ 854 CC_Diagnostics_Active 1;
BA_ "U_C519_MY18_5_Diesel_Tx" SG_ 854 CC_Diagnostics_Active 1;
BA_ "U_B515_MCA_MY17_Gas_Tx" SG_ 854 CC_Diagnostics_Active 1;
BA_ "U_B515_MCA_MY17_Diesel_Tx" SG_ 854 CC_Diagnostics_Active 1;
BA_ "U_B479_MY17_Diesel_Tx" SG_ 854 CC_Diagnostics_Active 1;
BA_ "U_B479_MY17_Gas_Tx" SG_ 854 CC_Diagnostics_Active 1;
BA_ "GenSigSendType" SG_ 854 CC_Diagnostics_Active 3;
BA_ "CrossOver_InfoCAN" SG_ 854 CC_Diagnostics_Active 1;
BA_ "U_P702_MY2021_Tx" SG_ 854 RHS_Temp_Display_Digit3 1;
BA_ "U_CX727_MY2021_Tx" SG_ 854 RHS_Temp_Display_Digit3 1;
BA_ "U_CX430_MY2021_Tx" SG_ 854 RHS_Temp_Display_Digit3 1;
BA_ "U_U611_U625_MY20_Phev_Tx" SG_ 854 RHS_Temp_Display_Digit3 1;
BA_ "U_CX482_CX483_MY20_Tx" SG_ 854 RHS_Temp_Display_Digit3 1;
BA_ "U_U611_U625_MY20_Hev_Tx" SG_ 854 RHS_Temp_Display_Digit3 1;
BA_ "U_U611_U625_MY20_Gas_Tx" SG_ 854 RHS_Temp_Display_Digit3 1;
BA_ "U_B500_MY18_Diesel_Tx" SG_ 854 RHS_Temp_Display_Digit3 1;
BA_ "U_B500_MY18_Gas_Tx" SG_ 854 RHS_Temp_Display_Digit3 1;
BA_ "U_C519_MY18_5_Gas_Tx" SG_ 854 RHS_Temp_Display_Digit3 1;
BA_ "U_C519_MY18_5_Diesel_Tx" SG_ 854 RHS_Temp_Display_Digit3 1;
BA_ "U_B515_MCA_MY17_Gas_Tx" SG_ 854 RHS_Temp_Display_Digit3 1;
BA_ "U_B515_MCA_MY17_Diesel_Tx" SG_ 854 RHS_Temp_Display_Digit3 1;
BA_ "U_B479_MY17_Diesel_Tx" SG_ 854 RHS_Temp_Display_Digit3 1;
BA_ "U_B479_MY17_Gas_Tx" SG_ 854 RHS_Temp_Display_Digit3 1;
BA_ "GenSigSendType" SG_ 854 RHS_Temp_Display_Digit3 3;
BA_ "CrossOver_InfoCAN" SG_ 854 RHS_Temp_Display_Digit3 1;
BA_ "U_P702_MY2021_Tx" SG_ 854 RHS_Temp_Display_Digit2 1;
BA_ "U_CX727_MY2021_Tx" SG_ 854 RHS_Temp_Display_Digit2 1;
BA_ "U_CX430_MY2021_Tx" SG_ 854 RHS_Temp_Display_Digit2 1;
BA_ "U_U611_U625_MY20_Phev_Tx" SG_ 854 RHS_Temp_Display_Digit2 1;
BA_ "U_CX482_CX483_MY20_Tx" SG_ 854 RHS_Temp_Display_Digit2 1;
BA_ "U_U611_U625_MY20_Hev_Tx" SG_ 854 RHS_Temp_Display_Digit2 1;
BA_ "U_U611_U625_MY20_Gas_Tx" SG_ 854 RHS_Temp_Display_Digit2 1;
BA_ "U_B500_MY18_Diesel_Tx" SG_ 854 RHS_Temp_Display_Digit2 1;
BA_ "U_B500_MY18_Gas_Tx" SG_ 854 RHS_Temp_Display_Digit2 1;
BA_ "U_C519_MY18_5_Gas_Tx" SG_ 854 RHS_Temp_Display_Digit2 1;
BA_ "U_C519_MY18_5_Diesel_Tx" SG_ 854 RHS_Temp_Display_Digit2 1;
BA_ "U_B515_MCA_MY17_Gas_Tx" SG_ 854 RHS_Temp_Display_Digit2 1;
BA_ "U_B515_MCA_MY17_Diesel_Tx" SG_ 854 RHS_Temp_Display_Digit2 1;
BA_ "U_B479_MY17_Diesel_Tx" SG_ 854 RHS_Temp_Display_Digit2 1;
BA_ "U_B479_MY17_Gas_Tx" SG_ 854 RHS_Temp_Display_Digit2 1;
BA_ "GenSigSendType" SG_ 854 RHS_Temp_Display_Digit2 3;
BA_ "CrossOver_InfoCAN" SG_ 854 RHS_Temp_Display_Digit2 1;
BA_ "U_P702_MY2021_Tx" SG_ 854 RHS_Temp_Display_Digit1 1;
BA_ "U_CX727_MY2021_Tx" SG_ 854 RHS_Temp_Display_Digit1 1;
BA_ "U_CX430_MY2021_Tx" SG_ 854 RHS_Temp_Display_Digit1 1;
BA_ "U_U611_U625_MY20_Phev_Tx" SG_ 854 RHS_Temp_Display_Digit1 1;
BA_ "U_CX482_CX483_MY20_Tx" SG_ 854 RHS_Temp_Display_Digit1 1;
BA_ "U_U611_U625_MY20_Hev_Tx" SG_ 854 RHS_Temp_Display_Digit1 1;
BA_ "U_U611_U625_MY20_Gas_Tx" SG_ 854 RHS_Temp_Display_Digit1 1;
BA_ "U_B500_MY18_Diesel_Tx" SG_ 854 RHS_Temp_Display_Digit1 1;
BA_ "U_B500_MY18_Gas_Tx" SG_ 854 RHS_Temp_Display_Digit1 1;
BA_ "U_C519_MY18_5_Gas_Tx" SG_ 854 RHS_Temp_Display_Digit1 1;
BA_ "U_C519_MY18_5_Diesel_Tx" SG_ 854 RHS_Temp_Display_Digit1 1;
BA_ "U_B515_MCA_MY17_Gas_Tx" SG_ 854 RHS_Temp_Display_Digit1 1;
BA_ "U_B515_MCA_MY17_Diesel_Tx" SG_ 854 RHS_Temp_Display_Digit1 1;
BA_ "U_B479_MY17_Diesel_Tx" SG_ 854 RHS_Temp_Display_Digit1 1;
BA_ "U_B479_MY17_Gas_Tx" SG_ 854 RHS_Temp_Display_Digit1 1;
BA_ "GenSigSendType" SG_ 854 RHS_Temp_Display_Digit1 3;
BA_ "CrossOver_InfoCAN" SG_ 854 RHS_Temp_Display_Digit1 1;
BA_ "U_P702_MY2021_Tx" SG_ 854 LHS_Temp_Display_Digit3 1;
BA_ "U_CX727_MY2021_Tx" SG_ 854 LHS_Temp_Display_Digit3 1;
BA_ "U_CX430_MY2021_Tx" SG_ 854 LHS_Temp_Display_Digit3 1;
BA_ "U_U611_U625_MY20_Phev_Tx" SG_ 854 LHS_Temp_Display_Digit3 1;
BA_ "U_B562_MY18_Diesel_Tx" SG_ 854 LHS_Temp_Display_Digit3 1;
BA_ "U_CX482_CX483_MY20_Tx" SG_ 854 LHS_Temp_Display_Digit3 1;
BA_ "U_U611_U625_MY20_Hev_Tx" SG_ 854 LHS_Temp_Display_Digit3 1;
BA_ "U_U611_U625_MY20_Gas_Tx" SG_ 854 LHS_Temp_Display_Digit3 1;
BA_ "U_B500_MY18_Diesel_Tx" SG_ 854 LHS_Temp_Display_Digit3 1;
BA_ "U_B500_MY18_Gas_Tx" SG_ 854 LHS_Temp_Display_Digit3 1;
BA_ "U_B562_MY18_Gas_Tx" SG_ 854 LHS_Temp_Display_Digit3 1;
BA_ "U_C519_MY18_5_Gas_Tx" SG_ 854 LHS_Temp_Display_Digit3 1;
BA_ "U_C519_MY18_5_Diesel_Tx" SG_ 854 LHS_Temp_Display_Digit3 1;
BA_ "U_B515_MCA_MY17_Gas_Tx" SG_ 854 LHS_Temp_Display_Digit3 1;
BA_ "U_B515_MCA_MY17_Diesel_Tx" SG_ 854 LHS_Temp_Display_Digit3 1;
BA_ "U_B479_MY17_Diesel_Tx" SG_ 854 LHS_Temp_Display_Digit3 1;
BA_ "U_B479_MY17_Gas_Tx" SG_ 854 LHS_Temp_Display_Digit3 1;
BA_ "GenSigSendType" SG_ 854 LHS_Temp_Display_Digit3 3;
BA_ "CrossOver_InfoCAN" SG_ 854 LHS_Temp_Display_Digit3 1;
BA_ "U_P702_MY2021_Tx" SG_ 854 LHS_Temp_Display_Digit2 1;
BA_ "U_CX727_MY2021_Tx" SG_ 854 LHS_Temp_Display_Digit2 1;
BA_ "U_CX430_MY2021_Tx" SG_ 854 LHS_Temp_Display_Digit2 1;
BA_ "U_U611_U625_MY20_Phev_Tx" SG_ 854 LHS_Temp_Display_Digit2 1;
BA_ "U_B562_MY18_Diesel_Tx" SG_ 854 LHS_Temp_Display_Digit2 1;
BA_ "U_CX482_CX483_MY20_Tx" SG_ 854 LHS_Temp_Display_Digit2 1;
BA_ "U_U611_U625_MY20_Hev_Tx" SG_ 854 LHS_Temp_Display_Digit2 1;
BA_ "U_U611_U625_MY20_Gas_Tx" SG_ 854 LHS_Temp_Display_Digit2 1;
BA_ "U_B500_MY18_Diesel_Tx" SG_ 854 LHS_Temp_Display_Digit2 1;
BA_ "U_B500_MY18_Gas_Tx" SG_ 854 LHS_Temp_Display_Digit2 1;
BA_ "U_B562_MY18_Gas_Tx" SG_ 854 LHS_Temp_Display_Digit2 1;
BA_ "U_C519_MY18_5_Gas_Tx" SG_ 854 LHS_Temp_Display_Digit2 1;
BA_ "U_C519_MY18_5_Diesel_Tx" SG_ 854 LHS_Temp_Display_Digit2 1;
BA_ "U_B515_MCA_MY17_Gas_Tx" SG_ 854 LHS_Temp_Display_Digit2 1;
BA_ "U_B515_MCA_MY17_Diesel_Tx" SG_ 854 LHS_Temp_Display_Digit2 1;
BA_ "U_B479_MY17_Diesel_Tx" SG_ 854 LHS_Temp_Display_Digit2 1;
BA_ "U_B479_MY17_Gas_Tx" SG_ 854 LHS_Temp_Display_Digit2 1;
BA_ "GenSigSendType" SG_ 854 LHS_Temp_Display_Digit2 3;
BA_ "CrossOver_InfoCAN" SG_ 854 LHS_Temp_Display_Digit2 1;
BA_ "U_P702_MY2021_Tx" SG_ 854 LHS_Temp_Display_Digit1 1;
BA_ "U_CX727_MY2021_Tx" SG_ 854 LHS_Temp_Display_Digit1 1;
BA_ "U_CX430_MY2021_Tx" SG_ 854 LHS_Temp_Display_Digit1 1;
BA_ "U_U611_U625_MY20_Phev_Tx" SG_ 854 LHS_Temp_Display_Digit1 1;
BA_ "U_B562_MY18_Diesel_Tx" SG_ 854 LHS_Temp_Display_Digit1 1;
BA_ "U_CX482_CX483_MY20_Tx" SG_ 854 LHS_Temp_Display_Digit1 1;
BA_ "U_U611_U625_MY20_Hev_Tx" SG_ 854 LHS_Temp_Display_Digit1 1;
BA_ "U_U611_U625_MY20_Gas_Tx" SG_ 854 LHS_Temp_Display_Digit1 1;
BA_ "U_B500_MY18_Diesel_Tx" SG_ 854 LHS_Temp_Display_Digit1 1;
BA_ "U_B500_MY18_Gas_Tx" SG_ 854 LHS_Temp_Display_Digit1 1;
BA_ "U_B562_MY18_Gas_Tx" SG_ 854 LHS_Temp_Display_Digit1 1;
BA_ "U_C519_MY18_5_Gas_Tx" SG_ 854 LHS_Temp_Display_Digit1 1;
BA_ "U_C519_MY18_5_Diesel_Tx" SG_ 854 LHS_Temp_Display_Digit1 1;
BA_ "U_B515_MCA_MY17_Gas_Tx" SG_ 854 LHS_Temp_Display_Digit1 1;
BA_ "U_B515_MCA_MY17_Diesel_Tx" SG_ 854 LHS_Temp_Display_Digit1 1;
BA_ "U_B479_MY17_Diesel_Tx" SG_ 854 LHS_Temp_Display_Digit1 1;
BA_ "U_B479_MY17_Gas_Tx" SG_ 854 LHS_Temp_Display_Digit1 1;
BA_ "GenSigSendType" SG_ 854 LHS_Temp_Display_Digit1 3;
BA_ "CrossOver_InfoCAN" SG_ 854 LHS_Temp_Display_Digit1 1;
BA_ "U_P702_MY2021_Tx" SG_ 854 EATC_RHS_Units 1;
BA_ "U_CX727_MY2021_Tx" SG_ 854 EATC_RHS_Units 1;
BA_ "U_CX430_MY2021_Tx" SG_ 854 EATC_RHS_Units 1;
BA_ "U_U611_U625_MY20_Phev_Tx" SG_ 854 EATC_RHS_Units 1;
BA_ "U_B562_MY18_Diesel_Tx" SG_ 854 EATC_RHS_Units 1;
BA_ "U_CX482_CX483_MY20_Tx" SG_ 854 EATC_RHS_Units 1;
BA_ "U_U611_U625_MY20_Hev_Tx" SG_ 854 EATC_RHS_Units 1;
BA_ "U_U611_U625_MY20_Gas_Tx" SG_ 854 EATC_RHS_Units 1;
BA_ "U_B500_MY18_Diesel_Tx" SG_ 854 EATC_RHS_Units 1;
BA_ "U_B500_MY18_Gas_Tx" SG_ 854 EATC_RHS_Units 1;
BA_ "U_B562_MY18_Gas_Tx" SG_ 854 EATC_RHS_Units 1;
BA_ "U_C519_MY18_5_Gas_Tx" SG_ 854 EATC_RHS_Units 1;
BA_ "U_C519_MY18_5_Diesel_Tx" SG_ 854 EATC_RHS_Units 1;
BA_ "U_B515_MCA_MY17_Gas_Tx" SG_ 854 EATC_RHS_Units 1;
BA_ "U_B515_MCA_MY17_Diesel_Tx" SG_ 854 EATC_RHS_Units 1;
BA_ "U_B479_MY17_Diesel_Tx" SG_ 854 EATC_RHS_Units 1;
BA_ "U_B479_MY17_Gas_Tx" SG_ 854 EATC_RHS_Units 1;
BA_ "GenSigSendType" SG_ 854 EATC_RHS_Units 3;
BA_ "CrossOver_InfoCAN" SG_ 854 EATC_RHS_Units 1;
BA_ "U_P702_MY2021_Tx" SG_ 854 EATC_LHS_Units 1;
BA_ "U_CX727_MY2021_Tx" SG_ 854 EATC_LHS_Units 1;
BA_ "U_CX430_MY2021_Tx" SG_ 854 EATC_LHS_Units 1;
BA_ "U_U611_U625_MY20_Phev_Tx" SG_ 854 EATC_LHS_Units 1;
BA_ "U_B562_MY18_Diesel_Tx" SG_ 854 EATC_LHS_Units 1;
BA_ "U_CX482_CX483_MY20_Tx" SG_ 854 EATC_LHS_Units 1;
BA_ "U_U611_U625_MY20_Hev_Tx" SG_ 854 EATC_LHS_Units 1;
BA_ "U_U611_U625_MY20_Gas_Tx" SG_ 854 EATC_LHS_Units 1;
BA_ "U_B500_MY18_Diesel_Tx" SG_ 854 EATC_LHS_Units 1;
BA_ "U_B500_MY18_Gas_Tx" SG_ 854 EATC_LHS_Units 1;
BA_ "U_B562_MY18_Gas_Tx" SG_ 854 EATC_LHS_Units 1;
BA_ "U_C519_MY18_5_Gas_Tx" SG_ 854 EATC_LHS_Units 1;
BA_ "U_C519_MY18_5_Diesel_Tx" SG_ 854 EATC_LHS_Units 1;
BA_ "U_B515_MCA_MY17_Gas_Tx" SG_ 854 EATC_LHS_Units 1;
BA_ "U_B515_MCA_MY17_Diesel_Tx" SG_ 854 EATC_LHS_Units 1;
BA_ "U_B479_MY17_Diesel_Tx" SG_ 854 EATC_LHS_Units 1;
BA_ "U_B479_MY17_Gas_Tx" SG_ 854 EATC_LHS_Units 1;
BA_ "GenSigSendType" SG_ 854 EATC_LHS_Units 3;
BA_ "CrossOver_InfoCAN" SG_ 854 EATC_LHS_Units 1;
BA_ "U_CX430_MY2021_Rx" SG_ 534 WhlRotatRr_No_Cnt 1;
BA_ "U_U611_U625_MY20_Phev_Rx" SG_ 534 WhlRotatRr_No_Cnt 1;
BA_ "U_CX482_CX483_MY20_Rx" SG_ 534 WhlRotatRr_No_Cnt 1;
BA_ "U_U611_U625_MY20_Hev_Rx" SG_ 534 WhlRotatRr_No_Cnt 1;
BA_ "U_U611_U625_MY20_Gas_Rx" SG_ 534 WhlRotatRr_No_Cnt 1;
BA_ "U_C519_MY18_5_Gas_Rx" SG_ 534 WhlRotatRr_No_Cnt 1;
BA_ "U_C519_MY18_5_Diesel_Rx" SG_ 534 WhlRotatRr_No_Cnt 1;
BA_ "CrossOver_InfoCAN" SG_ 534 WhlRotatRr_No_Cnt 1;
BA_ "U_CX430_MY2021_Rx" SG_ 534 WhlDirRr_D_Actl 1;
BA_ "U_U611_U625_MY20_Phev_Rx" SG_ 534 WhlDirRr_D_Actl 1;
BA_ "U_CX482_CX483_MY20_Rx" SG_ 534 WhlDirRr_D_Actl 1;
BA_ "U_U611_U625_MY20_Hev_Rx" SG_ 534 WhlDirRr_D_Actl 1;
BA_ "U_U611_U625_MY20_Gas_Rx" SG_ 534 WhlDirRr_D_Actl 1;
BA_ "U_C519_MY18_5_Gas_Rx" SG_ 534 WhlDirRr_D_Actl 1;
BA_ "U_C519_MY18_5_Diesel_Rx" SG_ 534 WhlDirRr_D_Actl 1;
BA_ "CrossOver_InfoCAN" SG_ 534 WhlDirRr_D_Actl 1;
BA_ "U_CX430_MY2021_Rx" SG_ 534 WhlDirRl_D_Actl 1;
BA_ "U_U611_U625_MY20_Phev_Rx" SG_ 534 WhlDirRl_D_Actl 1;
BA_ "U_CX482_CX483_MY20_Rx" SG_ 534 WhlDirRl_D_Actl 1;
BA_ "U_U611_U625_MY20_Hev_Rx" SG_ 534 WhlDirRl_D_Actl 1;
BA_ "U_U611_U625_MY20_Gas_Rx" SG_ 534 WhlDirRl_D_Actl 1;
BA_ "U_C519_MY18_5_Gas_Rx" SG_ 534 WhlDirRl_D_Actl 1;
BA_ "U_C519_MY18_5_Diesel_Rx" SG_ 534 WhlDirRl_D_Actl 1;
BA_ "CrossOver_InfoCAN" SG_ 534 WhlDirRl_D_Actl 1;
BA_ "U_CX727_MY2021_Rx" SG_ 534 WhlDirFr_D_Actl 1;
BA_ "U_CX430_MY2021_Rx" SG_ 534 WhlDirFr_D_Actl 1;
BA_ "U_U611_U625_MY20_Phev_Rx" SG_ 534 WhlDirFr_D_Actl 1;
BA_ "U_CX482_CX483_MY20_Rx" SG_ 534 WhlDirFr_D_Actl 1;
BA_ "U_U611_U625_MY20_Hev_Rx" SG_ 534 WhlDirFr_D_Actl 1;
BA_ "U_U611_U625_MY20_Gas_Rx" SG_ 534 WhlDirFr_D_Actl 1;
BA_ "U_C519_MY18_5_Gas_Rx" SG_ 534 WhlDirFr_D_Actl 1;
BA_ "U_C519_MY18_5_Diesel_Rx" SG_ 534 WhlDirFr_D_Actl 1;
BA_ "CrossOver_InfoCAN" SG_ 534 WhlDirFr_D_Actl 1;
BA_ "U_CX430_MY2021_Rx" SG_ 534 WhlDirFl_D_Actl 1;
BA_ "U_U611_U625_MY20_Phev_Rx" SG_ 534 WhlDirFl_D_Actl 1;
BA_ "U_CX482_CX483_MY20_Rx" SG_ 534 WhlDirFl_D_Actl 1;
BA_ "U_U611_U625_MY20_Hev_Rx" SG_ 534 WhlDirFl_D_Actl 1;
BA_ "U_U611_U625_MY20_Gas_Rx" SG_ 534 WhlDirFl_D_Actl 1;
BA_ "U_C519_MY18_5_Gas_Rx" SG_ 534 WhlDirFl_D_Actl 1;
BA_ "U_C519_MY18_5_Diesel_Rx" SG_ 534 WhlDirFl_D_Actl 1;
BA_ "CrossOver_InfoCAN" SG_ 534 WhlDirFl_D_Actl 1;
BA_ "U_CX430_MY2021_Rx" SG_ 534 WhlRotatRl_No_Cnt 1;
BA_ "U_U611_U625_MY20_Phev_Rx" SG_ 534 WhlRotatRl_No_Cnt 1;
BA_ "U_CX482_CX483_MY20_Rx" SG_ 534 WhlRotatRl_No_Cnt 1;
BA_ "U_U611_U625_MY20_Hev_Rx" SG_ 534 WhlRotatRl_No_Cnt 1;
BA_ "U_U611_U625_MY20_Gas_Rx" SG_ 534 WhlRotatRl_No_Cnt 1;
BA_ "U_C519_MY18_5_Gas_Rx" SG_ 534 WhlRotatRl_No_Cnt 1;
BA_ "U_C519_MY18_5_Diesel_Rx" SG_ 534 WhlRotatRl_No_Cnt 1;
BA_ "CrossOver_InfoCAN" SG_ 534 WhlRotatRl_No_Cnt 1;
BA_ "U_CX727_MY2021_Rx" SG_ 534 WhlRotatFr_No_Cnt 1;
BA_ "U_CX430_MY2021_Rx" SG_ 534 WhlRotatFr_No_Cnt 1;
BA_ "U_U611_U625_MY20_Phev_Rx" SG_ 534 WhlRotatFr_No_Cnt 1;
BA_ "U_CX482_CX483_MY20_Rx" SG_ 534 WhlRotatFr_No_Cnt 1;
BA_ "U_U611_U625_MY20_Hev_Rx" SG_ 534 WhlRotatFr_No_Cnt 1;
BA_ "U_U611_U625_MY20_Gas_Rx" SG_ 534 WhlRotatFr_No_Cnt 1;
BA_ "U_C519_MY18_5_Gas_Rx" SG_ 534 WhlRotatFr_No_Cnt 1;
BA_ "U_C519_MY18_5_Diesel_Rx" SG_ 534 WhlRotatFr_No_Cnt 1;
BA_ "U_B515_MCA_MY17_Gas_Rx" SG_ 534 WhlRotatFr_No_Cnt 1;
BA_ "U_B515_MCA_MY17_Diesel_Rx" SG_ 534 WhlRotatFr_No_Cnt 1;
BA_ "U_B479_MY17_Diesel_Rx" SG_ 534 WhlRotatFr_No_Cnt 1;
BA_ "U_B479_MY17_Gas_Rx" SG_ 534 WhlRotatFr_No_Cnt 1;
BA_ "CrossOver_InfoCAN" SG_ 534 WhlRotatFr_No_Cnt 1;
BA_ "U_CX430_MY2021_Rx" SG_ 534 WhlRotatFl_No_Cnt 1;
BA_ "U_U611_U625_MY20_Phev_Rx" SG_ 534 WhlRotatFl_No_Cnt 1;
BA_ "U_CX482_CX483_MY20_Rx" SG_ 534 WhlRotatFl_No_Cnt 1;
BA_ "U_U611_U625_MY20_Hev_Rx" SG_ 534 WhlRotatFl_No_Cnt 1;
BA_ "U_U611_U625_MY20_Gas_Rx" SG_ 534 WhlRotatFl_No_Cnt 1;
BA_ "U_C519_MY18_5_Gas_Rx" SG_ 534 WhlRotatFl_No_Cnt 1;
BA_ "U_C519_MY18_5_Diesel_Rx" SG_ 534 WhlRotatFl_No_Cnt 1;
BA_ "CrossOver_InfoCAN" SG_ 534 WhlRotatFl_No_Cnt 1;
BA_ "U_P702_MY2021_Tx" SG_ 772 SeatScrnDrvOn_B_Rq 1;
BA_ "U_U611_U625_MY20_Phev_Tx" SG_ 772 SeatScrnDrvOn_B_Rq 1;
BA_ "U_CX482_CX483_MY20_Tx" SG_ 772 SeatScrnDrvOn_B_Rq 1;
BA_ "U_U611_U625_MY20_Hev_Tx" SG_ 772 SeatScrnDrvOn_B_Rq 1;
BA_ "U_U611_U625_MY20_Gas_Tx" SG_ 772 SeatScrnDrvOn_B_Rq 1;
BA_ "GenSigSendType" SG_ 772 SeatScrnDrvOn_B_Rq 3;
BA_ "WakeupSignal" SG_ 772 SeatScrnDrvOn_B_Rq 1;
BA_ "U_P702_MY2021_Tx" SG_ 772 SeatPos_D_Stat 1;
BA_ "U_CX727_MY2021_Tx" SG_ 772 SeatPos_D_Stat 1;
BA_ "U_CX430_MY2021_Tx" SG_ 772 SeatPos_D_Stat 1;
BA_ "U_U611_U625_MY20_Phev_Tx" SG_ 772 SeatPos_D_Stat 1;
BA_ "U_CX482_CX483_MY20_Tx" SG_ 772 SeatPos_D_Stat 1;
BA_ "U_U611_U625_MY20_Hev_Tx" SG_ 772 SeatPos_D_Stat 1;
BA_ "U_U611_U625_MY20_Gas_Tx" SG_ 772 SeatPos_D_Stat 1;
BA_ "GenSigSendType" SG_ 772 SeatPos_D_Stat 3;
BA_ "U_P702_MY2021_Tx" SG_ 772 MemDrvDeny_B_Stat 1;
BA_ "U_CX727_MY2021_Tx" SG_ 772 MemDrvDeny_B_Stat 1;
BA_ "U_CX430_MY2021_Tx" SG_ 772 MemDrvDeny_B_Stat 1;
BA_ "U_U611_U625_MY20_Phev_Tx" SG_ 772 MemDrvDeny_B_Stat 1;
BA_ "U_CX482_CX483_MY20_Tx" SG_ 772 MemDrvDeny_B_Stat 1;
BA_ "U_U611_U625_MY20_Hev_Tx" SG_ 772 MemDrvDeny_B_Stat 1;
BA_ "U_U611_U625_MY20_Gas_Tx" SG_ 772 MemDrvDeny_B_Stat 1;
BA_ "U_C490_MY18_Tx" SG_ 772 MemDrvDeny_B_Stat 1;
BA_ "GenSigSendType" SG_ 772 MemDrvDeny_B_Stat 3;
BA_ "U_P702_MY2021_Tx" SG_ 772 Memory_Feedback_Rqst 1;
BA_ "U_CX727_MY2021_Tx" SG_ 772 Memory_Feedback_Rqst 1;
BA_ "U_CX430_MY2021_Tx" SG_ 772 Memory_Feedback_Rqst 1;
BA_ "U_U611_U625_MY20_Phev_Tx" SG_ 772 Memory_Feedback_Rqst 1;
BA_ "U_CX482_CX483_MY20_Tx" SG_ 772 Memory_Feedback_Rqst 1;
BA_ "U_U611_U625_MY20_Hev_Tx" SG_ 772 Memory_Feedback_Rqst 1;
BA_ "U_U611_U625_MY20_Gas_Tx" SG_ 772 Memory_Feedback_Rqst 1;
BA_ "U_C490_MY18_Tx" SG_ 772 Memory_Feedback_Rqst 1;
BA_ "U_B479_MY17_Gas_Rx" SG_ 772 Memory_Feedback_Rqst 1;
BA_ "GenSigSendType" SG_ 772 Memory_Feedback_Rqst 3;
BA_ "CrossOver_InfoCAN" SG_ 772 Memory_Feedback_Rqst 1;
BA_ "WakeupSignal" SG_ 772 Memory_Feedback_Rqst 1;
BA_ "U_P702_MY2021_Tx" SG_ 772 Easy_Entry_Rqst 1;
BA_ "U_CX727_MY2021_Tx" SG_ 772 Easy_Entry_Rqst 1;
BA_ "U_CX430_MY2021_Tx" SG_ 772 Easy_Entry_Rqst 1;
BA_ "U_U611_U625_MY20_Phev_Tx" SG_ 772 Easy_Entry_Rqst 1;
BA_ "U_CX482_CX483_MY20_Tx" SG_ 772 Easy_Entry_Rqst 1;
BA_ "U_U611_U625_MY20_Hev_Tx" SG_ 772 Easy_Entry_Rqst 1;
BA_ "U_U611_U625_MY20_Gas_Tx" SG_ 772 Easy_Entry_Rqst 1;
BA_ "U_P702_MY2021_Rx" SG_ 772 Easy_Entry_Rqst 1;
BA_ "U_U611_U625_MY20_Phev_Rx" SG_ 772 Easy_Entry_Rqst 1;
BA_ "U_CX482_CX483_MY20_Rx" SG_ 772 Easy_Entry_Rqst 1;
BA_ "U_U611_U625_MY20_Hev_Rx" SG_ 772 Easy_Entry_Rqst 1;
BA_ "U_U611_U625_MY20_Gas_Rx" SG_ 772 Easy_Entry_Rqst 1;
BA_ "GenSigSendType" SG_ 772 Easy_Entry_Rqst 3;
BA_ "WakeupSignal" SG_ 772 Easy_Entry_Rqst 1;
BA_ "U_P702_MY2021_Tx" SG_ 772 Memory_Cmd 1;
BA_ "U_CX727_MY2021_Tx" SG_ 772 Memory_Cmd 1;
BA_ "U_CX430_MY2021_Tx" SG_ 772 Memory_Cmd 1;
BA_ "U_U611_U625_MY20_Phev_Tx" SG_ 772 Memory_Cmd 1;
BA_ "U_CX482_CX483_MY20_Tx" SG_ 772 Memory_Cmd 1;
BA_ "U_U611_U625_MY20_Hev_Tx" SG_ 772 Memory_Cmd 1;
BA_ "U_U611_U625_MY20_Gas_Tx" SG_ 772 Memory_Cmd 1;
BA_ "U_C490_MY18_Tx" SG_ 772 Memory_Cmd 1;
BA_ "U_CX727_MY2021_Rx" SG_ 772 Memory_Cmd 1;
BA_ "U_CX430_MY2021_Rx" SG_ 772 Memory_Cmd 1;
BA_ "U_C490_MY18_Rx" SG_ 772 Memory_Cmd 1;
BA_ "U_B515_MCA_MY17_Gas_Rx" SG_ 772 Memory_Cmd 1;
BA_ "U_B515_MCA_MY17_Diesel_Rx" SG_ 772 Memory_Cmd 1;
BA_ "U_P702_MY2021_Rx" SG_ 772 Memory_Cmd 1;
BA_ "U_U611_U625_MY20_Phev_Rx" SG_ 772 Memory_Cmd 1;
BA_ "U_CX482_CX483_MY20_Rx" SG_ 772 Memory_Cmd 1;
BA_ "U_U611_U625_MY20_Hev_Rx" SG_ 772 Memory_Cmd 1;
BA_ "U_U611_U625_MY20_Gas_Rx" SG_ 772 Memory_Cmd 1;
BA_ "GenSigSendType" SG_ 772 Memory_Cmd 3;
BA_ "WakeupSignal" SG_ 772 Memory_Cmd 1;
BA_ "U_P702_MY2021_Tx" SG_ 772 Cancel_Auto_Movement 1;
BA_ "U_CX727_MY2021_Tx" SG_ 772 Cancel_Auto_Movement 1;
BA_ "U_CX430_MY2021_Tx" SG_ 772 Cancel_Auto_Movement 1;
BA_ "U_U611_U625_MY20_Phev_Tx" SG_ 772 Cancel_Auto_Movement 1;
BA_ "U_CX482_CX483_MY20_Tx" SG_ 772 Cancel_Auto_Movement 1;
BA_ "U_U611_U625_MY20_Hev_Tx" SG_ 772 Cancel_Auto_Movement 1;
BA_ "U_U611_U625_MY20_Gas_Tx" SG_ 772 Cancel_Auto_Movement 1;
BA_ "U_C490_MY18_Tx" SG_ 772 Cancel_Auto_Movement 1;
BA_ "U_CX727_MY2021_Rx" SG_ 772 Cancel_Auto_Movement 1;
BA_ "U_CX430_MY2021_Rx" SG_ 772 Cancel_Auto_Movement 1;
BA_ "U_C490_MY18_Rx" SG_ 772 Cancel_Auto_Movement 1;
BA_ "U_B515_MCA_MY17_Gas_Rx" SG_ 772 Cancel_Auto_Movement 1;
BA_ "U_B515_MCA_MY17_Diesel_Rx" SG_ 772 Cancel_Auto_Movement 1;
BA_ "U_P702_MY2021_Rx" SG_ 772 Cancel_Auto_Movement 1;
BA_ "U_U611_U625_MY20_Phev_Rx" SG_ 772 Cancel_Auto_Movement 1;
BA_ "U_CX482_CX483_MY20_Rx" SG_ 772 Cancel_Auto_Movement 1;
BA_ "U_U611_U625_MY20_Hev_Rx" SG_ 772 Cancel_Auto_Movement 1;
BA_ "U_U611_U625_MY20_Gas_Rx" SG_ 772 Cancel_Auto_Movement 1;
BA_ "GenSigSendType" SG_ 772 Cancel_Auto_Movement 3;
BA_ "WakeupSignal" SG_ 772 Cancel_Auto_Movement 1;
BA_ "GenSigSendType" SG_ 935 LcwaRight_D_Stat 3;
BA_ "GenSigSendType" SG_ 935 LcwaDetctRight2_B_Stat 3;
BA_ "GenSigSendType" SG_ 935 LcwaDetctRight1_B_Stat 3;
BA_ "GenSigSendType" SG_ 935 RbaCtaRight_D_Stat 3;
BA_ "CrossOver_InfoCAN" SG_ 935 RbaCtaRight_D_Stat 1;
BA_ "U_U611_U625_MY20_Gas_Rx" SG_ 935 RbaCtaRight_D_Stat 1;
BA_ "U_U611_U625_MY20_Hev_Rx" SG_ 935 RbaCtaRight_D_Stat 1;
BA_ "U_U611_U625_MY20_Phev_Rx" SG_ 935 RbaCtaRight_D_Stat 1;
BA_ "U_U611_U625_MY20_Gas_Tx" SG_ 935 RbaCtaRight_D_Stat 1;
BA_ "U_U611_U625_MY20_Hev_Tx" SG_ 935 RbaCtaRight_D_Stat 1;
BA_ "U_U611_U625_MY20_Phev_Tx" SG_ 935 RbaCtaRight_D_Stat 1;
BA_ "GenSigSendType" SG_ 935 BttRight_D_Stat 3;
BA_ "U_B515_MCA_MY17_Diesel_Rx" SG_ 935 BttRight_D_Stat 1;
BA_ "U_B515_MCA_MY17_Gas_Rx" SG_ 935 BttRight_D_Stat 1;
BA_ "U_C519_MY18_5_Diesel_Rx" SG_ 935 BttRight_D_Stat 1;
BA_ "U_C519_MY18_5_Gas_Rx" SG_ 935 BttRight_D_Stat 1;
BA_ "U_U611_U625_MY20_Gas_Rx" SG_ 935 BttRight_D_Stat 1;
BA_ "U_U611_U625_MY20_Hev_Rx" SG_ 935 BttRight_D_Stat 1;
BA_ "U_U611_U625_MY20_Phev_Rx" SG_ 935 BttRight_D_Stat 1;
BA_ "U_CX430_MY2021_Rx" SG_ 935 BttRight_D_Stat 1;
BA_ "U_B479_MY17_Gas_Tx" SG_ 935 BttRight_D_Stat 1;
BA_ "U_B479_MY17_Diesel_Tx" SG_ 935 BttRight_D_Stat 1;
BA_ "U_B515_MCA_MY17_Diesel_Tx" SG_ 935 BttRight_D_Stat 1;
BA_ "U_B515_MCA_MY17_Gas_Tx" SG_ 935 BttRight_D_Stat 1;
BA_ "U_C519_MY18_5_Diesel_Tx" SG_ 935 BttRight_D_Stat 1;
BA_ "U_C519_MY18_5_Gas_Tx" SG_ 935 BttRight_D_Stat 1;
BA_ "U_U611_U625_MY20_Gas_Tx" SG_ 935 BttRight_D_Stat 1;
BA_ "U_U611_U625_MY20_Hev_Tx" SG_ 935 BttRight_D_Stat 1;
BA_ "U_U611_U625_MY20_Phev_Tx" SG_ 935 BttRight_D_Stat 1;
BA_ "U_CX430_MY2021_Tx" SG_ 935 BttRight_D_Stat 1;
BA_ "GenSigSendType" SG_ 935 BttRight_D_RqDrv 3;
BA_ "U_B515_MCA_MY17_Diesel_Rx" SG_ 935 BttRight_D_RqDrv 1;
BA_ "U_B515_MCA_MY17_Gas_Rx" SG_ 935 BttRight_D_RqDrv 1;
BA_ "U_C519_MY18_5_Diesel_Rx" SG_ 935 BttRight_D_RqDrv 1;
BA_ "U_C519_MY18_5_Gas_Rx" SG_ 935 BttRight_D_RqDrv 1;
BA_ "U_U611_U625_MY20_Gas_Rx" SG_ 935 BttRight_D_RqDrv 1;
BA_ "U_U611_U625_MY20_Hev_Rx" SG_ 935 BttRight_D_RqDrv 1;
BA_ "U_U611_U625_MY20_Phev_Rx" SG_ 935 BttRight_D_RqDrv 1;
BA_ "U_CX430_MY2021_Rx" SG_ 935 BttRight_D_RqDrv 1;
BA_ "U_B479_MY17_Gas_Tx" SG_ 935 BttRight_D_RqDrv 1;
BA_ "U_B479_MY17_Diesel_Tx" SG_ 935 BttRight_D_RqDrv 1;
BA_ "U_B515_MCA_MY17_Diesel_Tx" SG_ 935 BttRight_D_RqDrv 1;
BA_ "U_B515_MCA_MY17_Gas_Tx" SG_ 935 BttRight_D_RqDrv 1;
BA_ "U_C519_MY18_5_Diesel_Tx" SG_ 935 BttRight_D_RqDrv 1;
BA_ "U_C519_MY18_5_Gas_Tx" SG_ 935 BttRight_D_RqDrv 1;
BA_ "U_U611_U625_MY20_Gas_Tx" SG_ 935 BttRight_D_RqDrv 1;
BA_ "U_U611_U625_MY20_Hev_Tx" SG_ 935 BttRight_D_RqDrv 1;
BA_ "U_U611_U625_MY20_Phev_Tx" SG_ 935 BttRight_D_RqDrv 1;
BA_ "U_CX430_MY2021_Tx" SG_ 935 BttRight_D_RqDrv 1;
BA_ "U_CX727_MY2021_Tx" SG_ 935 CtaAlrtRight2_D_Stat 1;
BA_ "U_CX430_MY2021_Tx" SG_ 935 CtaAlrtRight2_D_Stat 1;
BA_ "U_U611_U625_MY20_Phev_Tx" SG_ 935 CtaAlrtRight2_D_Stat 1;
BA_ "U_U611_U625_MY20_Hev_Tx" SG_ 935 CtaAlrtRight2_D_Stat 1;
BA_ "U_U611_U625_MY20_Gas_Tx" SG_ 935 CtaAlrtRight2_D_Stat 1;
BA_ "U_C519_MY18_5_Gas_Tx" SG_ 935 CtaAlrtRight2_D_Stat 1;
BA_ "U_C519_MY18_5_Diesel_Tx" SG_ 935 CtaAlrtRight2_D_Stat 1;
BA_ "U_B515_MCA_MY17_Gas_Tx" SG_ 935 CtaAlrtRight2_D_Stat 1;
BA_ "U_B515_MCA_MY17_Diesel_Tx" SG_ 935 CtaAlrtRight2_D_Stat 1;
BA_ "U_B479_MY17_Diesel_Tx" SG_ 935 CtaAlrtRight2_D_Stat 1;
BA_ "U_B479_MY17_Gas_Tx" SG_ 935 CtaAlrtRight2_D_Stat 1;
BA_ "GenSigSendType" SG_ 935 CtaAlrtRight2_D_Stat 3;
BA_ "U_CX727_MY2021_Tx" SG_ 935 CtaRightBrkEnbl_B_Rq 1;
BA_ "U_U611_U625_MY20_Phev_Tx" SG_ 935 CtaRightBrkEnbl_B_Rq 1;
BA_ "U_CX482_CX483_MY20_Tx" SG_ 935 CtaRightBrkEnbl_B_Rq 1;
BA_ "U_U611_U625_MY20_Hev_Tx" SG_ 935 CtaRightBrkEnbl_B_Rq 1;
BA_ "U_U611_U625_MY20_Gas_Tx" SG_ 935 CtaRightBrkEnbl_B_Rq 1;
BA_ "U_C519_MY18_5_Gas_Tx" SG_ 935 CtaRightBrkEnbl_B_Rq 1;
BA_ "U_C519_MY18_5_Diesel_Tx" SG_ 935 CtaRightBrkEnbl_B_Rq 1;
BA_ "U_U611_U625_MY20_Phev_Rx" SG_ 935 CtaRightBrkEnbl_B_Rq 1;
BA_ "U_CX482_CX483_MY20_Rx" SG_ 935 CtaRightBrkEnbl_B_Rq 1;
BA_ "U_U611_U625_MY20_Hev_Rx" SG_ 935 CtaRightBrkEnbl_B_Rq 1;
BA_ "U_U611_U625_MY20_Gas_Rx" SG_ 935 CtaRightBrkEnbl_B_Rq 1;
BA_ "U_C519_MY18_5_Gas_Rx" SG_ 935 CtaRightBrkEnbl_B_Rq 1;
BA_ "U_C519_MY18_5_Diesel_Rx" SG_ 935 CtaRightBrkEnbl_B_Rq 1;
BA_ "GenSigSendType" SG_ 935 CtaRightBrkEnbl_B_Rq 3;
BA_ "U_CX727_MY2021_Tx" SG_ 935 CtaRightBrkDecel_B_Rq 1;
BA_ "U_U611_U625_MY20_Phev_Tx" SG_ 935 CtaRightBrkDecel_B_Rq 1;
BA_ "U_CX482_CX483_MY20_Tx" SG_ 935 CtaRightBrkDecel_B_Rq 1;
BA_ "U_U611_U625_MY20_Hev_Tx" SG_ 935 CtaRightBrkDecel_B_Rq 1;
BA_ "U_U611_U625_MY20_Gas_Tx" SG_ 935 CtaRightBrkDecel_B_Rq 1;
BA_ "U_C519_MY18_5_Gas_Tx" SG_ 935 CtaRightBrkDecel_B_Rq 1;
BA_ "U_C519_MY18_5_Diesel_Tx" SG_ 935 CtaRightBrkDecel_B_Rq 1;
BA_ "U_U611_U625_MY20_Phev_Rx" SG_ 935 CtaRightBrkDecel_B_Rq 1;
BA_ "U_CX482_CX483_MY20_Rx" SG_ 935 CtaRightBrkDecel_B_Rq 1;
BA_ "U_U611_U625_MY20_Hev_Rx" SG_ 935 CtaRightBrkDecel_B_Rq 1;
BA_ "U_U611_U625_MY20_Gas_Rx" SG_ 935 CtaRightBrkDecel_B_Rq 1;
BA_ "U_C519_MY18_5_Gas_Rx" SG_ 935 CtaRightBrkDecel_B_Rq 1;
BA_ "U_C519_MY18_5_Diesel_Rx" SG_ 935 CtaRightBrkDecel_B_Rq 1;
BA_ "GenSigSendType" SG_ 935 CtaRightBrkDecel_B_Rq 3;
BA_ "U_CX727_MY2021_Tx" SG_ 935 Side_Detect_R_Illum 1;
BA_ "U_CX430_MY2021_Tx" SG_ 935 Side_Detect_R_Illum 1;
BA_ "U_U611_U625_MY20_Phev_Tx" SG_ 935 Side_Detect_R_Illum 1;
BA_ "U_CX482_CX483_MY20_Tx" SG_ 935 Side_Detect_R_Illum 1;
BA_ "U_U611_U625_MY20_Hev_Tx" SG_ 935 Side_Detect_R_Illum 1;
BA_ "U_U611_U625_MY20_Gas_Tx" SG_ 935 Side_Detect_R_Illum 1;
BA_ "U_C519_MY18_5_Gas_Tx" SG_ 935 Side_Detect_R_Illum 1;
BA_ "U_C519_MY18_5_Diesel_Tx" SG_ 935 Side_Detect_R_Illum 1;
BA_ "U_B515_MCA_MY17_Gas_Tx" SG_ 935 Side_Detect_R_Illum 1;
BA_ "U_B515_MCA_MY17_Diesel_Tx" SG_ 935 Side_Detect_R_Illum 1;
BA_ "U_B479_MY17_Diesel_Tx" SG_ 935 Side_Detect_R_Illum 1;
BA_ "U_B479_MY17_Gas_Tx" SG_ 935 Side_Detect_R_Illum 1;
BA_ "U_CX727_MY2021_Rx" SG_ 935 Side_Detect_R_Illum 1;
BA_ "U_P702_MY2021_Rx" SG_ 935 Side_Detect_R_Illum 1;
BA_ "U_CX430_MY2021_Rx" SG_ 935 Side_Detect_R_Illum 1;
BA_ "U_U611_U625_MY20_Phev_Rx" SG_ 935 Side_Detect_R_Illum 1;
BA_ "U_CX482_CX483_MY20_Rx" SG_ 935 Side_Detect_R_Illum 1;
BA_ "U_U611_U625_MY20_Hev_Rx" SG_ 935 Side_Detect_R_Illum 1;
BA_ "U_U611_U625_MY20_Gas_Rx" SG_ 935 Side_Detect_R_Illum 1;
BA_ "U_C519_MY18_5_Gas_Rx" SG_ 935 Side_Detect_R_Illum 1;
BA_ "U_C519_MY18_5_Diesel_Rx" SG_ 935 Side_Detect_R_Illum 1;
BA_ "U_B515_MCA_MY17_Gas_Rx" SG_ 935 Side_Detect_R_Illum 1;
BA_ "U_B515_MCA_MY17_Diesel_Rx" SG_ 935 Side_Detect_R_Illum 1;
BA_ "U_B479_MY17_Diesel_Rx" SG_ 935 Side_Detect_R_Illum 1;
BA_ "U_B479_MY17_Gas_Rx" SG_ 935 Side_Detect_R_Illum 1;
BA_ "GenSigSendType" SG_ 935 Side_Detect_R_Illum 3;
BA_ "GenSigStartValue" SG_ 935 Side_Detect_R_Illum 100;
BA_ "GenSigStartValueInteger" SG_ 935 Side_Detect_R_Illum 100;
BA_ "CrossOver_InfoCAN" SG_ 935 Side_Detect_R_Illum 1;
BA_ "U_CX727_MY2021_Tx" SG_ 935 CtaSnsRight_D_Stat 1;
BA_ "U_CX430_MY2021_Tx" SG_ 935 CtaSnsRight_D_Stat 1;
BA_ "U_U611_U625_MY20_Phev_Tx" SG_ 935 CtaSnsRight_D_Stat 1;
BA_ "U_CX482_CX483_MY20_Tx" SG_ 935 CtaSnsRight_D_Stat 1;
BA_ "U_U611_U625_MY20_Hev_Tx" SG_ 935 CtaSnsRight_D_Stat 1;
BA_ "U_U611_U625_MY20_Gas_Tx" SG_ 935 CtaSnsRight_D_Stat 1;
BA_ "U_C519_MY18_5_Gas_Tx" SG_ 935 CtaSnsRight_D_Stat 1;
BA_ "U_C519_MY18_5_Diesel_Tx" SG_ 935 CtaSnsRight_D_Stat 1;
BA_ "U_B515_MCA_MY17_Gas_Tx" SG_ 935 CtaSnsRight_D_Stat 1;
BA_ "U_B515_MCA_MY17_Diesel_Tx" SG_ 935 CtaSnsRight_D_Stat 1;
BA_ "U_B479_MY17_Diesel_Tx" SG_ 935 CtaSnsRight_D_Stat 1;
BA_ "U_B479_MY17_Gas_Tx" SG_ 935 CtaSnsRight_D_Stat 1;
BA_ "U_CX727_MY2021_Rx" SG_ 935 CtaSnsRight_D_Stat 1;
BA_ "U_CX430_MY2021_Rx" SG_ 935 CtaSnsRight_D_Stat 1;
BA_ "U_U611_U625_MY20_Phev_Rx" SG_ 935 CtaSnsRight_D_Stat 1;
BA_ "U_CX482_CX483_MY20_Rx" SG_ 935 CtaSnsRight_D_Stat 1;
BA_ "U_U611_U625_MY20_Hev_Rx" SG_ 935 CtaSnsRight_D_Stat 1;
BA_ "U_U611_U625_MY20_Gas_Rx" SG_ 935 CtaSnsRight_D_Stat 1;
BA_ "U_C519_MY18_5_Gas_Rx" SG_ 935 CtaSnsRight_D_Stat 1;
BA_ "U_C519_MY18_5_Diesel_Rx" SG_ 935 CtaSnsRight_D_Stat 1;
BA_ "U_B515_MCA_MY17_Gas_Rx" SG_ 935 CtaSnsRight_D_Stat 1;
BA_ "U_B515_MCA_MY17_Diesel_Rx" SG_ 935 CtaSnsRight_D_Stat 1;
BA_ "U_B479_MY17_Diesel_Rx" SG_ 935 CtaSnsRight_D_Stat 1;
BA_ "U_B479_MY17_Gas_Rx" SG_ 935 CtaSnsRight_D_Stat 1;
BA_ "GenSigSendType" SG_ 935 CtaSnsRight_D_Stat 3;
BA_ "CrossOver_InfoCAN" SG_ 935 CtaSnsRight_D_Stat 1;
BA_ "U_CX727_MY2021_Tx" SG_ 935 CtaAlrtRight_D_Stat 1;
BA_ "U_CX430_MY2021_Tx" SG_ 935 CtaAlrtRight_D_Stat 1;
BA_ "U_U611_U625_MY20_Phev_Tx" SG_ 935 CtaAlrtRight_D_Stat 1;
BA_ "U_CX482_CX483_MY20_Tx" SG_ 935 CtaAlrtRight_D_Stat 1;
BA_ "U_U611_U625_MY20_Hev_Tx" SG_ 935 CtaAlrtRight_D_Stat 1;
BA_ "U_U611_U625_MY20_Gas_Tx" SG_ 935 CtaAlrtRight_D_Stat 1;
BA_ "U_C519_MY18_5_Gas_Tx" SG_ 935 CtaAlrtRight_D_Stat 1;
BA_ "U_C519_MY18_5_Diesel_Tx" SG_ 935 CtaAlrtRight_D_Stat 1;
BA_ "U_B515_MCA_MY17_Gas_Tx" SG_ 935 CtaAlrtRight_D_Stat 1;
BA_ "U_B515_MCA_MY17_Diesel_Tx" SG_ 935 CtaAlrtRight_D_Stat 1;
BA_ "U_B479_MY17_Diesel_Tx" SG_ 935 CtaAlrtRight_D_Stat 1;
BA_ "U_B479_MY17_Gas_Tx" SG_ 935 CtaAlrtRight_D_Stat 1;
BA_ "U_CX727_MY2021_Rx" SG_ 935 CtaAlrtRight_D_Stat 1;
BA_ "U_P702_MY2021_Rx" SG_ 935 CtaAlrtRight_D_Stat 1;
BA_ "U_CX430_MY2021_Rx" SG_ 935 CtaAlrtRight_D_Stat 1;
BA_ "U_U611_U625_MY20_Phev_Rx" SG_ 935 CtaAlrtRight_D_Stat 1;
BA_ "U_CX482_CX483_MY20_Rx" SG_ 935 CtaAlrtRight_D_Stat 1;
BA_ "U_U611_U625_MY20_Hev_Rx" SG_ 935 CtaAlrtRight_D_Stat 1;
BA_ "U_U611_U625_MY20_Gas_Rx" SG_ 935 CtaAlrtRight_D_Stat 1;
BA_ "U_C519_MY18_5_Gas_Rx" SG_ 935 CtaAlrtRight_D_Stat 1;
BA_ "U_C519_MY18_5_Diesel_Rx" SG_ 935 CtaAlrtRight_D_Stat 1;
BA_ "U_B515_MCA_MY17_Gas_Rx" SG_ 935 CtaAlrtRight_D_Stat 1;
BA_ "U_B515_MCA_MY17_Diesel_Rx" SG_ 935 CtaAlrtRight_D_Stat 1;
BA_ "U_B479_MY17_Diesel_Rx" SG_ 935 CtaAlrtRight_D_Stat 1;
BA_ "U_B479_MY17_Gas_Rx" SG_ 935 CtaAlrtRight_D_Stat 1;
BA_ "GenSigSendType" SG_ 935 CtaAlrtRight_D_Stat 3;
BA_ "CrossOver_InfoCAN" SG_ 935 CtaAlrtRight_D_Stat 1;
BA_ "U_CX727_MY2021_Tx" SG_ 935 CtaRight_D_Stat 1;
BA_ "U_CX430_MY2021_Tx" SG_ 935 CtaRight_D_Stat 1;
BA_ "U_U611_U625_MY20_Phev_Tx" SG_ 935 CtaRight_D_Stat 1;
BA_ "U_CX482_CX483_MY20_Tx" SG_ 935 CtaRight_D_Stat 1;
BA_ "U_U611_U625_MY20_Hev_Tx" SG_ 935 CtaRight_D_Stat 1;
BA_ "U_U611_U625_MY20_Gas_Tx" SG_ 935 CtaRight_D_Stat 1;
BA_ "U_C519_MY18_5_Gas_Tx" SG_ 935 CtaRight_D_Stat 1;
BA_ "U_C519_MY18_5_Diesel_Tx" SG_ 935 CtaRight_D_Stat 1;
BA_ "U_B515_MCA_MY17_Gas_Tx" SG_ 935 CtaRight_D_Stat 1;
BA_ "U_B515_MCA_MY17_Diesel_Tx" SG_ 935 CtaRight_D_Stat 1;
BA_ "U_B479_MY17_Diesel_Tx" SG_ 935 CtaRight_D_Stat 1;
BA_ "U_B479_MY17_Gas_Tx" SG_ 935 CtaRight_D_Stat 1;
BA_ "U_CX727_MY2021_Rx" SG_ 935 CtaRight_D_Stat 1;
BA_ "U_CX430_MY2021_Rx" SG_ 935 CtaRight_D_Stat 1;
BA_ "U_U611_U625_MY20_Phev_Rx" SG_ 935 CtaRight_D_Stat 1;
BA_ "U_CX482_CX483_MY20_Rx" SG_ 935 CtaRight_D_Stat 1;
BA_ "U_U611_U625_MY20_Hev_Rx" SG_ 935 CtaRight_D_Stat 1;
BA_ "U_U611_U625_MY20_Gas_Rx" SG_ 935 CtaRight_D_Stat 1;
BA_ "U_C519_MY18_5_Gas_Rx" SG_ 935 CtaRight_D_Stat 1;
BA_ "U_C519_MY18_5_Diesel_Rx" SG_ 935 CtaRight_D_Stat 1;
BA_ "U_B515_MCA_MY17_Gas_Rx" SG_ 935 CtaRight_D_Stat 1;
BA_ "U_B515_MCA_MY17_Diesel_Rx" SG_ 935 CtaRight_D_Stat 1;
BA_ "U_B479_MY17_Diesel_Rx" SG_ 935 CtaRight_D_Stat 1;
BA_ "U_B479_MY17_Gas_Rx" SG_ 935 CtaRight_D_Stat 1;
BA_ "GenSigSendType" SG_ 935 CtaRight_D_Stat 3;
BA_ "CrossOver_InfoCAN" SG_ 935 CtaRight_D_Stat 1;
BA_ "U_CX727_MY2021_Tx" SG_ 935 SodRight_D_Stat 1;
BA_ "U_CX430_MY2021_Tx" SG_ 935 SodRight_D_Stat 1;
BA_ "U_U611_U625_MY20_Phev_Tx" SG_ 935 SodRight_D_Stat 1;
BA_ "U_CX482_CX483_MY20_Tx" SG_ 935 SodRight_D_Stat 1;
BA_ "U_U611_U625_MY20_Hev_Tx" SG_ 935 SodRight_D_Stat 1;
BA_ "U_U611_U625_MY20_Gas_Tx" SG_ 935 SodRight_D_Stat 1;
BA_ "U_C519_MY18_5_Gas_Tx" SG_ 935 SodRight_D_Stat 1;
BA_ "U_C519_MY18_5_Diesel_Tx" SG_ 935 SodRight_D_Stat 1;
BA_ "U_B515_MCA_MY17_Gas_Tx" SG_ 935 SodRight_D_Stat 1;
BA_ "U_B515_MCA_MY17_Diesel_Tx" SG_ 935 SodRight_D_Stat 1;
BA_ "U_B479_MY17_Diesel_Tx" SG_ 935 SodRight_D_Stat 1;
BA_ "U_B479_MY17_Gas_Tx" SG_ 935 SodRight_D_Stat 1;
BA_ "U_CX727_MY2021_Rx" SG_ 935 SodRight_D_Stat 1;
BA_ "U_CX430_MY2021_Rx" SG_ 935 SodRight_D_Stat 1;
BA_ "U_U611_U625_MY20_Phev_Rx" SG_ 935 SodRight_D_Stat 1;
BA_ "U_CX482_CX483_MY20_Rx" SG_ 935 SodRight_D_Stat 1;
BA_ "U_U611_U625_MY20_Hev_Rx" SG_ 935 SodRight_D_Stat 1;
BA_ "U_U611_U625_MY20_Gas_Rx" SG_ 935 SodRight_D_Stat 1;
BA_ "U_C519_MY18_5_Gas_Rx" SG_ 935 SodRight_D_Stat 1;
BA_ "U_C519_MY18_5_Diesel_Rx" SG_ 935 SodRight_D_Stat 1;
BA_ "U_B515_MCA_MY17_Gas_Rx" SG_ 935 SodRight_D_Stat 1;
BA_ "U_B515_MCA_MY17_Diesel_Rx" SG_ 935 SodRight_D_Stat 1;
BA_ "U_B479_MY17_Diesel_Rx" SG_ 935 SodRight_D_Stat 1;
BA_ "U_B479_MY17_Gas_Rx" SG_ 935 SodRight_D_Stat 1;
BA_ "GenSigSendType" SG_ 935 SodRight_D_Stat 3;
BA_ "GenSigStartValue" SG_ 935 SodRight_D_Stat 2;
BA_ "GenSigStartValueInteger" SG_ 935 SodRight_D_Stat 2;
BA_ "CrossOver_InfoCAN" SG_ 935 SodRight_D_Stat 1;
BA_ "U_CX727_MY2021_Tx" SG_ 935 SodSnsRight_D_Stat 1;
BA_ "U_CX430_MY2021_Tx" SG_ 935 SodSnsRight_D_Stat 1;
BA_ "U_U611_U625_MY20_Phev_Tx" SG_ 935 SodSnsRight_D_Stat 1;
BA_ "U_CX482_CX483_MY20_Tx" SG_ 935 SodSnsRight_D_Stat 1;
BA_ "U_U611_U625_MY20_Hev_Tx" SG_ 935 SodSnsRight_D_Stat 1;
BA_ "U_U611_U625_MY20_Gas_Tx" SG_ 935 SodSnsRight_D_Stat 1;
BA_ "U_C519_MY18_5_Gas_Tx" SG_ 935 SodSnsRight_D_Stat 1;
BA_ "U_C519_MY18_5_Diesel_Tx" SG_ 935 SodSnsRight_D_Stat 1;
BA_ "U_B515_MCA_MY17_Gas_Tx" SG_ 935 SodSnsRight_D_Stat 1;
BA_ "U_B515_MCA_MY17_Diesel_Tx" SG_ 935 SodSnsRight_D_Stat 1;
BA_ "U_B479_MY17_Diesel_Tx" SG_ 935 SodSnsRight_D_Stat 1;
BA_ "U_B479_MY17_Gas_Tx" SG_ 935 SodSnsRight_D_Stat 1;
BA_ "U_P702_MY2021_Rx" SG_ 935 SodSnsRight_D_Stat 1;
BA_ "U_CX727_MY2021_Rx" SG_ 935 SodSnsRight_D_Stat 1;
BA_ "U_CX430_MY2021_Rx" SG_ 935 SodSnsRight_D_Stat 1;
BA_ "U_U611_U625_MY20_Phev_Rx" SG_ 935 SodSnsRight_D_Stat 1;
BA_ "U_CX482_CX483_MY20_Rx" SG_ 935 SodSnsRight_D_Stat 1;
BA_ "U_U611_U625_MY20_Hev_Rx" SG_ 935 SodSnsRight_D_Stat 1;
BA_ "U_U611_U625_MY20_Gas_Rx" SG_ 935 SodSnsRight_D_Stat 1;
BA_ "U_C519_MY18_5_Gas_Rx" SG_ 935 SodSnsRight_D_Stat 1;
BA_ "U_C519_MY18_5_Diesel_Rx" SG_ 935 SodSnsRight_D_Stat 1;
BA_ "U_B515_MCA_MY17_Gas_Rx" SG_ 935 SodSnsRight_D_Stat 1;
BA_ "U_B515_MCA_MY17_Diesel_Rx" SG_ 935 SodSnsRight_D_Stat 1;
BA_ "U_B479_MY17_Diesel_Rx" SG_ 935 SodSnsRight_D_Stat 1;
BA_ "U_B479_MY17_Gas_Rx" SG_ 935 SodSnsRight_D_Stat 1;
BA_ "GenSigSendType" SG_ 935 SodSnsRight_D_Stat 3;
BA_ "CrossOver_InfoCAN" SG_ 935 SodSnsRight_D_Stat 1;
BA_ "U_CX727_MY2021_Tx" SG_ 935 SodAlrtRight_D_Stat 1;
BA_ "U_CX430_MY2021_Tx" SG_ 935 SodAlrtRight_D_Stat 1;
BA_ "U_U611_U625_MY20_Phev_Tx" SG_ 935 SodAlrtRight_D_Stat 1;
BA_ "U_CX482_CX483_MY20_Tx" SG_ 935 SodAlrtRight_D_Stat 1;
BA_ "U_U611_U625_MY20_Hev_Tx" SG_ 935 SodAlrtRight_D_Stat 1;
BA_ "U_U611_U625_MY20_Gas_Tx" SG_ 935 SodAlrtRight_D_Stat 1;
BA_ "U_C519_MY18_5_Gas_Tx" SG_ 935 SodAlrtRight_D_Stat 1;
BA_ "U_C519_MY18_5_Diesel_Tx" SG_ 935 SodAlrtRight_D_Stat 1;
BA_ "U_B515_MCA_MY17_Gas_Tx" SG_ 935 SodAlrtRight_D_Stat 1;
BA_ "U_B515_MCA_MY17_Diesel_Tx" SG_ 935 SodAlrtRight_D_Stat 1;
BA_ "U_B479_MY17_Diesel_Tx" SG_ 935 SodAlrtRight_D_Stat 1;
BA_ "U_B479_MY17_Gas_Tx" SG_ 935 SodAlrtRight_D_Stat 1;
BA_ "U_CX727_MY2021_Rx" SG_ 935 SodAlrtRight_D_Stat 1;
BA_ "U_P702_MY2021_Rx" SG_ 935 SodAlrtRight_D_Stat 1;
BA_ "U_CX430_MY2021_Rx" SG_ 935 SodAlrtRight_D_Stat 1;
BA_ "U_U611_U625_MY20_Phev_Rx" SG_ 935 SodAlrtRight_D_Stat 1;
BA_ "U_CX482_CX483_MY20_Rx" SG_ 935 SodAlrtRight_D_Stat 1;
BA_ "U_U611_U625_MY20_Hev_Rx" SG_ 935 SodAlrtRight_D_Stat 1;
BA_ "U_U611_U625_MY20_Gas_Rx" SG_ 935 SodAlrtRight_D_Stat 1;
BA_ "U_C519_MY18_5_Gas_Rx" SG_ 935 SodAlrtRight_D_Stat 1;
BA_ "U_C519_MY18_5_Diesel_Rx" SG_ 935 SodAlrtRight_D_Stat 1;
BA_ "U_B515_MCA_MY17_Gas_Rx" SG_ 935 SodAlrtRight_D_Stat 1;
BA_ "U_B515_MCA_MY17_Diesel_Rx" SG_ 935 SodAlrtRight_D_Stat 1;
BA_ "U_B479_MY17_Diesel_Rx" SG_ 935 SodAlrtRight_D_Stat 1;
BA_ "U_B479_MY17_Gas_Rx" SG_ 935 SodAlrtRight_D_Stat 1;
BA_ "GenSigSendType" SG_ 935 SodAlrtRight_D_Stat 3;
BA_ "CrossOver_InfoCAN" SG_ 935 SodAlrtRight_D_Stat 1;
BA_ "U_CX727_MY2021_Tx" SG_ 935 SodDetctRight_D_Stat 1;
BA_ "U_CX430_MY2021_Tx" SG_ 935 SodDetctRight_D_Stat 1;
BA_ "U_U611_U625_MY20_Phev_Tx" SG_ 935 SodDetctRight_D_Stat 1;
BA_ "U_CX482_CX483_MY20_Tx" SG_ 935 SodDetctRight_D_Stat 1;
BA_ "U_U611_U625_MY20_Hev_Tx" SG_ 935 SodDetctRight_D_Stat 1;
BA_ "U_U611_U625_MY20_Gas_Tx" SG_ 935 SodDetctRight_D_Stat 1;
BA_ "U_C519_MY18_5_Gas_Tx" SG_ 935 SodDetctRight_D_Stat 1;
BA_ "U_C519_MY18_5_Diesel_Tx" SG_ 935 SodDetctRight_D_Stat 1;
BA_ "U_B515_MCA_MY17_Gas_Tx" SG_ 935 SodDetctRight_D_Stat 1;
BA_ "U_B515_MCA_MY17_Diesel_Tx" SG_ 935 SodDetctRight_D_Stat 1;
BA_ "U_B479_MY17_Diesel_Tx" SG_ 935 SodDetctRight_D_Stat 1;
BA_ "U_B479_MY17_Gas_Tx" SG_ 935 SodDetctRight_D_Stat 1;
BA_ "GenSigSendType" SG_ 935 SodDetctRight_D_Stat 3;
BA_ "CrossOver_InfoCAN" SG_ 935 SodDetctRight_D_Stat 1;
BA_ "U_CX727_MY2021_Tx" SG_ 935 SodWarnRight_Prd_Rq 1;
BA_ "U_CX430_MY2021_Tx" SG_ 935 SodWarnRight_Prd_Rq 1;
BA_ "U_U611_U625_MY20_Phev_Tx" SG_ 935 SodWarnRight_Prd_Rq 1;
BA_ "U_CX482_CX483_MY20_Tx" SG_ 935 SodWarnRight_Prd_Rq 1;
BA_ "U_U611_U625_MY20_Hev_Tx" SG_ 935 SodWarnRight_Prd_Rq 1;
BA_ "U_U611_U625_MY20_Gas_Tx" SG_ 935 SodWarnRight_Prd_Rq 1;
BA_ "U_C519_MY18_5_Gas_Tx" SG_ 935 SodWarnRight_Prd_Rq 1;
BA_ "U_C519_MY18_5_Diesel_Tx" SG_ 935 SodWarnRight_Prd_Rq 1;
BA_ "U_B515_MCA_MY17_Gas_Tx" SG_ 935 SodWarnRight_Prd_Rq 1;
BA_ "U_B515_MCA_MY17_Diesel_Tx" SG_ 935 SodWarnRight_Prd_Rq 1;
BA_ "U_B479_MY17_Diesel_Tx" SG_ 935 SodWarnRight_Prd_Rq 1;
BA_ "U_B479_MY17_Gas_Tx" SG_ 935 SodWarnRight_Prd_Rq 1;
BA_ "U_CX727_MY2021_Rx" SG_ 935 SodWarnRight_Prd_Rq 1;
BA_ "U_P702_MY2021_Rx" SG_ 935 SodWarnRight_Prd_Rq 1;
BA_ "U_CX430_MY2021_Rx" SG_ 935 SodWarnRight_Prd_Rq 1;
BA_ "U_U611_U625_MY20_Phev_Rx" SG_ 935 SodWarnRight_Prd_Rq 1;
BA_ "U_CX482_CX483_MY20_Rx" SG_ 935 SodWarnRight_Prd_Rq 1;
BA_ "U_U611_U625_MY20_Hev_Rx" SG_ 935 SodWarnRight_Prd_Rq 1;
BA_ "U_U611_U625_MY20_Gas_Rx" SG_ 935 SodWarnRight_Prd_Rq 1;
BA_ "U_C519_MY18_5_Gas_Rx" SG_ 935 SodWarnRight_Prd_Rq 1;
BA_ "U_C519_MY18_5_Diesel_Rx" SG_ 935 SodWarnRight_Prd_Rq 1;
BA_ "U_B515_MCA_MY17_Gas_Rx" SG_ 935 SodWarnRight_Prd_Rq 1;
BA_ "U_B515_MCA_MY17_Diesel_Rx" SG_ 935 SodWarnRight_Prd_Rq 1;
BA_ "U_B479_MY17_Diesel_Rx" SG_ 935 SodWarnRight_Prd_Rq 1;
BA_ "U_B479_MY17_Gas_Rx" SG_ 935 SodWarnRight_Prd_Rq 1;
BA_ "GenSigSendType" SG_ 935 SodWarnRight_Prd_Rq 3;
BA_ "GenSigStartValue" SG_ 935 SodWarnRight_Prd_Rq 14;
BA_ "GenSigStartValueInteger" SG_ 935 SodWarnRight_Prd_Rq 14;
BA_ "CrossOver_InfoCAN" SG_ 935 SodWarnRight_Prd_Rq 1;
BA_ "U_CX727_MY2021_Tx" SG_ 935 SodInnrRight_D_Stat 1;
BA_ "U_CX430_MY2021_Tx" SG_ 935 SodInnrRight_D_Stat 1;
BA_ "U_U611_U625_MY20_Phev_Tx" SG_ 935 SodInnrRight_D_Stat 1;
BA_ "U_CX482_CX483_MY20_Tx" SG_ 935 SodInnrRight_D_Stat 1;
BA_ "U_U611_U625_MY20_Hev_Tx" SG_ 935 SodInnrRight_D_Stat 1;
BA_ "U_U611_U625_MY20_Gas_Tx" SG_ 935 SodInnrRight_D_Stat 1;
BA_ "U_C519_MY18_5_Gas_Tx" SG_ 935 SodInnrRight_D_Stat 1;
BA_ "U_C519_MY18_5_Diesel_Tx" SG_ 935 SodInnrRight_D_Stat 1;
BA_ "U_B515_MCA_MY17_Gas_Tx" SG_ 935 SodInnrRight_D_Stat 1;
BA_ "U_B515_MCA_MY17_Diesel_Tx" SG_ 935 SodInnrRight_D_Stat 1;
BA_ "U_B479_MY17_Diesel_Tx" SG_ 935 SodInnrRight_D_Stat 1;
BA_ "U_B479_MY17_Gas_Tx" SG_ 935 SodInnrRight_D_Stat 1;
BA_ "U_CX727_MY2021_Rx" SG_ 935 SodInnrRight_D_Stat 1;
BA_ "U_CX430_MY2021_Rx" SG_ 935 SodInnrRight_D_Stat 1;
BA_ "U_U611_U625_MY20_Phev_Rx" SG_ 935 SodInnrRight_D_Stat 1;
BA_ "U_CX482_CX483_MY20_Rx" SG_ 935 SodInnrRight_D_Stat 1;
BA_ "U_U611_U625_MY20_Hev_Rx" SG_ 935 SodInnrRight_D_Stat 1;
BA_ "U_U611_U625_MY20_Gas_Rx" SG_ 935 SodInnrRight_D_Stat 1;
BA_ "U_C519_MY18_5_Gas_Rx" SG_ 935 SodInnrRight_D_Stat 1;
BA_ "U_C519_MY18_5_Diesel_Rx" SG_ 935 SodInnrRight_D_Stat 1;
BA_ "GenSigSendType" SG_ 935 SodInnrRight_D_Stat 3;
BA_ "CrossOver_InfoCAN" SG_ 935 SodInnrRight_D_Stat 1;
BA_ "U_CX727_MY2021_Tx" SG_ 935 CtaInnrRight_D_Stat 1;
BA_ "U_CX430_MY2021_Tx" SG_ 935 CtaInnrRight_D_Stat 1;
BA_ "U_U611_U625_MY20_Phev_Tx" SG_ 935 CtaInnrRight_D_Stat 1;
BA_ "U_CX482_CX483_MY20_Tx" SG_ 935 CtaInnrRight_D_Stat 1;
BA_ "U_U611_U625_MY20_Hev_Tx" SG_ 935 CtaInnrRight_D_Stat 1;
BA_ "U_U611_U625_MY20_Gas_Tx" SG_ 935 CtaInnrRight_D_Stat 1;
BA_ "U_C519_MY18_5_Gas_Tx" SG_ 935 CtaInnrRight_D_Stat 1;
BA_ "U_C519_MY18_5_Diesel_Tx" SG_ 935 CtaInnrRight_D_Stat 1;
BA_ "U_B515_MCA_MY17_Gas_Tx" SG_ 935 CtaInnrRight_D_Stat 1;
BA_ "U_B515_MCA_MY17_Diesel_Tx" SG_ 935 CtaInnrRight_D_Stat 1;
BA_ "U_B479_MY17_Diesel_Tx" SG_ 935 CtaInnrRight_D_Stat 1;
BA_ "U_B479_MY17_Gas_Tx" SG_ 935 CtaInnrRight_D_Stat 1;
BA_ "U_CX727_MY2021_Rx" SG_ 935 CtaInnrRight_D_Stat 1;
BA_ "U_CX430_MY2021_Rx" SG_ 935 CtaInnrRight_D_Stat 1;
BA_ "U_U611_U625_MY20_Phev_Rx" SG_ 935 CtaInnrRight_D_Stat 1;
BA_ "U_CX482_CX483_MY20_Rx" SG_ 935 CtaInnrRight_D_Stat 1;
BA_ "U_U611_U625_MY20_Hev_Rx" SG_ 935 CtaInnrRight_D_Stat 1;
BA_ "U_U611_U625_MY20_Gas_Rx" SG_ 935 CtaInnrRight_D_Stat 1;
BA_ "U_C519_MY18_5_Gas_Rx" SG_ 935 CtaInnrRight_D_Stat 1;
BA_ "U_C519_MY18_5_Diesel_Rx" SG_ 935 CtaInnrRight_D_Stat 1;
BA_ "GenSigSendType" SG_ 935 CtaInnrRight_D_Stat 3;
BA_ "CrossOver_InfoCAN" SG_ 935 CtaInnrRight_D_Stat 1;
BA_ "GenSigSendType" SG_ 934 RbaCtaLeft_D_Stat 3;
BA_ "CrossOver_InfoCAN" SG_ 934 RbaCtaLeft_D_Stat 1;
BA_ "U_U611_U625_MY20_Gas_Rx" SG_ 934 RbaCtaLeft_D_Stat 1;
BA_ "U_U611_U625_MY20_Hev_Rx" SG_ 934 RbaCtaLeft_D_Stat 1;
BA_ "U_U611_U625_MY20_Phev_Rx" SG_ 934 RbaCtaLeft_D_Stat 1;
BA_ "U_U611_U625_MY20_Gas_Tx" SG_ 934 RbaCtaLeft_D_Stat 1;
BA_ "U_U611_U625_MY20_Hev_Tx" SG_ 934 RbaCtaLeft_D_Stat 1;
BA_ "U_U611_U625_MY20_Phev_Tx" SG_ 934 RbaCtaLeft_D_Stat 1;
BA_ "GenSigSendType" SG_ 934 LcwaLeft_D_Stat 3;
BA_ "GenSigSendType" SG_ 934 LcwaDetctLeft2_B_Stat 3;
BA_ "GenSigSendType" SG_ 934 LcwaDetctLeft1_B_Stat 3;
BA_ "GenSigSendType" SG_ 934 BttLeft_D_Stat 3;
BA_ "U_B515_MCA_MY17_Diesel_Rx" SG_ 934 BttLeft_D_Stat 1;
BA_ "U_B515_MCA_MY17_Gas_Rx" SG_ 934 BttLeft_D_Stat 1;
BA_ "U_C519_MY18_5_Diesel_Rx" SG_ 934 BttLeft_D_Stat 1;
BA_ "U_C519_MY18_5_Gas_Rx" SG_ 934 BttLeft_D_Stat 1;
BA_ "U_U611_U625_MY20_Gas_Rx" SG_ 934 BttLeft_D_Stat 1;
BA_ "U_U611_U625_MY20_Hev_Rx" SG_ 934 BttLeft_D_Stat 1;
BA_ "U_CX482_CX483_MY20_Rx" SG_ 934 BttLeft_D_Stat 1;
BA_ "U_U611_U625_MY20_Phev_Rx" SG_ 934 BttLeft_D_Stat 1;
BA_ "U_CX430_MY2021_Rx" SG_ 934 BttLeft_D_Stat 1;
BA_ "U_B479_MY17_Gas_Tx" SG_ 934 BttLeft_D_Stat 1;
BA_ "U_B479_MY17_Diesel_Tx" SG_ 934 BttLeft_D_Stat 1;
BA_ "U_B515_MCA_MY17_Diesel_Tx" SG_ 934 BttLeft_D_Stat 1;
BA_ "U_B515_MCA_MY17_Gas_Tx" SG_ 934 BttLeft_D_Stat 1;
BA_ "U_C519_MY18_5_Diesel_Tx" SG_ 934 BttLeft_D_Stat 1;
BA_ "U_C519_MY18_5_Gas_Tx" SG_ 934 BttLeft_D_Stat 1;
BA_ "U_U611_U625_MY20_Gas_Tx" SG_ 934 BttLeft_D_Stat 1;
BA_ "U_U611_U625_MY20_Hev_Tx" SG_ 934 BttLeft_D_Stat 1;
BA_ "U_U611_U625_MY20_Phev_Tx" SG_ 934 BttLeft_D_Stat 1;
BA_ "U_CX430_MY2021_Tx" SG_ 934 BttLeft_D_Stat 1;
BA_ "GenSigSendType" SG_ 934 BttLeft_D_RqDrv 3;
BA_ "U_B515_MCA_MY17_Diesel_Rx" SG_ 934 BttLeft_D_RqDrv 1;
BA_ "U_B515_MCA_MY17_Gas_Rx" SG_ 934 BttLeft_D_RqDrv 1;
BA_ "U_C519_MY18_5_Diesel_Rx" SG_ 934 BttLeft_D_RqDrv 1;
BA_ "U_C519_MY18_5_Gas_Rx" SG_ 934 BttLeft_D_RqDrv 1;
BA_ "U_U611_U625_MY20_Gas_Rx" SG_ 934 BttLeft_D_RqDrv 1;
BA_ "U_U611_U625_MY20_Hev_Rx" SG_ 934 BttLeft_D_RqDrv 1;
BA_ "U_CX482_CX483_MY20_Rx" SG_ 934 BttLeft_D_RqDrv 1;
BA_ "U_U611_U625_MY20_Phev_Rx" SG_ 934 BttLeft_D_RqDrv 1;
BA_ "U_CX430_MY2021_Rx" SG_ 934 BttLeft_D_RqDrv 1;
BA_ "U_B479_MY17_Gas_Tx" SG_ 934 BttLeft_D_RqDrv 1;
BA_ "U_B479_MY17_Diesel_Tx" SG_ 934 BttLeft_D_RqDrv 1;
BA_ "U_B515_MCA_MY17_Diesel_Tx" SG_ 934 BttLeft_D_RqDrv 1;
BA_ "U_B515_MCA_MY17_Gas_Tx" SG_ 934 BttLeft_D_RqDrv 1;
BA_ "U_C519_MY18_5_Diesel_Tx" SG_ 934 BttLeft_D_RqDrv 1;
BA_ "U_C519_MY18_5_Gas_Tx" SG_ 934 BttLeft_D_RqDrv 1;
BA_ "U_U611_U625_MY20_Gas_Tx" SG_ 934 BttLeft_D_RqDrv 1;
BA_ "U_U611_U625_MY20_Hev_Tx" SG_ 934 BttLeft_D_RqDrv 1;
BA_ "U_U611_U625_MY20_Phev_Tx" SG_ 934 BttLeft_D_RqDrv 1;
BA_ "U_CX430_MY2021_Tx" SG_ 934 BttLeft_D_RqDrv 1;
BA_ "U_CX727_MY2021_Tx" SG_ 934 CtaAlrtLeft2_D_Stat 1;
BA_ "U_CX430_MY2021_Tx" SG_ 934 CtaAlrtLeft2_D_Stat 1;
BA_ "U_U611_U625_MY20_Phev_Tx" SG_ 934 CtaAlrtLeft2_D_Stat 1;
BA_ "U_CX482_CX483_MY20_Tx" SG_ 934 CtaAlrtLeft2_D_Stat 1;
BA_ "U_U611_U625_MY20_Hev_Tx" SG_ 934 CtaAlrtLeft2_D_Stat 1;
BA_ "U_U611_U625_MY20_Gas_Tx" SG_ 934 CtaAlrtLeft2_D_Stat 1;
BA_ "U_C519_MY18_5_Gas_Tx" SG_ 934 CtaAlrtLeft2_D_Stat 1;
BA_ "U_C519_MY18_5_Diesel_Tx" SG_ 934 CtaAlrtLeft2_D_Stat 1;
BA_ "U_B515_MCA_MY17_Gas_Tx" SG_ 934 CtaAlrtLeft2_D_Stat 1;
BA_ "U_B515_MCA_MY17_Diesel_Tx" SG_ 934 CtaAlrtLeft2_D_Stat 1;
BA_ "U_B479_MY17_Diesel_Tx" SG_ 934 CtaAlrtLeft2_D_Stat 1;
BA_ "U_B479_MY17_Gas_Tx" SG_ 934 CtaAlrtLeft2_D_Stat 1;
BA_ "GenSigSendType" SG_ 934 CtaAlrtLeft2_D_Stat 3;
BA_ "U_CX727_MY2021_Tx" SG_ 934 CtaLeftBrkDecel_B_Rq 1;
BA_ "U_U611_U625_MY20_Phev_Tx" SG_ 934 CtaLeftBrkDecel_B_Rq 1;
BA_ "U_CX482_CX483_MY20_Tx" SG_ 934 CtaLeftBrkDecel_B_Rq 1;
BA_ "U_U611_U625_MY20_Hev_Tx" SG_ 934 CtaLeftBrkDecel_B_Rq 1;
BA_ "U_U611_U625_MY20_Gas_Tx" SG_ 934 CtaLeftBrkDecel_B_Rq 1;
BA_ "U_C519_MY18_5_Gas_Tx" SG_ 934 CtaLeftBrkDecel_B_Rq 1;
BA_ "U_C519_MY18_5_Diesel_Tx" SG_ 934 CtaLeftBrkDecel_B_Rq 1;
BA_ "U_U611_U625_MY20_Phev_Rx" SG_ 934 CtaLeftBrkDecel_B_Rq 1;
BA_ "U_CX482_CX483_MY20_Rx" SG_ 934 CtaLeftBrkDecel_B_Rq 1;
BA_ "U_U611_U625_MY20_Hev_Rx" SG_ 934 CtaLeftBrkDecel_B_Rq 1;
BA_ "U_U611_U625_MY20_Gas_Rx" SG_ 934 CtaLeftBrkDecel_B_Rq 1;
BA_ "U_C519_MY18_5_Gas_Rx" SG_ 934 CtaLeftBrkDecel_B_Rq 1;
BA_ "U_C519_MY18_5_Diesel_Rx" SG_ 934 CtaLeftBrkDecel_B_Rq 1;
BA_ "GenSigSendType" SG_ 934 CtaLeftBrkDecel_B_Rq 3;
BA_ "U_CX727_MY2021_Tx" SG_ 934 CtaLeftBrkEnbl_B_Rq 1;
BA_ "U_U611_U625_MY20_Phev_Tx" SG_ 934 CtaLeftBrkEnbl_B_Rq 1;
BA_ "U_CX482_CX483_MY20_Tx" SG_ 934 CtaLeftBrkEnbl_B_Rq 1;
BA_ "U_U611_U625_MY20_Hev_Tx" SG_ 934 CtaLeftBrkEnbl_B_Rq 1;
BA_ "U_U611_U625_MY20_Gas_Tx" SG_ 934 CtaLeftBrkEnbl_B_Rq 1;
BA_ "U_C519_MY18_5_Gas_Tx" SG_ 934 CtaLeftBrkEnbl_B_Rq 1;
BA_ "U_C519_MY18_5_Diesel_Tx" SG_ 934 CtaLeftBrkEnbl_B_Rq 1;
BA_ "U_U611_U625_MY20_Phev_Rx" SG_ 934 CtaLeftBrkEnbl_B_Rq 1;
BA_ "U_CX482_CX483_MY20_Rx" SG_ 934 CtaLeftBrkEnbl_B_Rq 1;
BA_ "U_U611_U625_MY20_Hev_Rx" SG_ 934 CtaLeftBrkEnbl_B_Rq 1;
BA_ "U_U611_U625_MY20_Gas_Rx" SG_ 934 CtaLeftBrkEnbl_B_Rq 1;
BA_ "U_C519_MY18_5_Gas_Rx" SG_ 934 CtaLeftBrkEnbl_B_Rq 1;
BA_ "U_C519_MY18_5_Diesel_Rx" SG_ 934 CtaLeftBrkEnbl_B_Rq 1;
BA_ "GenSigSendType" SG_ 934 CtaLeftBrkEnbl_B_Rq 3;
BA_ "U_CX727_MY2021_Tx" SG_ 934 Side_Detect_L_Illum 1;
BA_ "U_CX430_MY2021_Tx" SG_ 934 Side_Detect_L_Illum 1;
BA_ "U_U611_U625_MY20_Phev_Tx" SG_ 934 Side_Detect_L_Illum 1;
BA_ "U_CX482_CX483_MY20_Tx" SG_ 934 Side_Detect_L_Illum 1;
BA_ "U_U611_U625_MY20_Hev_Tx" SG_ 934 Side_Detect_L_Illum 1;
BA_ "U_U611_U625_MY20_Gas_Tx" SG_ 934 Side_Detect_L_Illum 1;
BA_ "U_C519_MY18_5_Gas_Tx" SG_ 934 Side_Detect_L_Illum 1;
BA_ "U_C519_MY18_5_Diesel_Tx" SG_ 934 Side_Detect_L_Illum 1;
BA_ "U_B515_MCA_MY17_Gas_Tx" SG_ 934 Side_Detect_L_Illum 1;
BA_ "U_B515_MCA_MY17_Diesel_Tx" SG_ 934 Side_Detect_L_Illum 1;
BA_ "U_B479_MY17_Diesel_Tx" SG_ 934 Side_Detect_L_Illum 1;
BA_ "U_B479_MY17_Gas_Tx" SG_ 934 Side_Detect_L_Illum 1;
BA_ "U_CX727_MY2021_Rx" SG_ 934 Side_Detect_L_Illum 1;
BA_ "U_P702_MY2021_Rx" SG_ 934 Side_Detect_L_Illum 1;
BA_ "U_CX430_MY2021_Rx" SG_ 934 Side_Detect_L_Illum 1;
BA_ "U_U611_U625_MY20_Phev_Rx" SG_ 934 Side_Detect_L_Illum 1;
BA_ "U_CX482_CX483_MY20_Rx" SG_ 934 Side_Detect_L_Illum 1;
BA_ "U_U611_U625_MY20_Hev_Rx" SG_ 934 Side_Detect_L_Illum 1;
BA_ "U_U611_U625_MY20_Gas_Rx" SG_ 934 Side_Detect_L_Illum 1;
BA_ "U_C519_MY18_5_Gas_Rx" SG_ 934 Side_Detect_L_Illum 1;
BA_ "U_C519_MY18_5_Diesel_Rx" SG_ 934 Side_Detect_L_Illum 1;
BA_ "U_B515_MCA_MY17_Gas_Rx" SG_ 934 Side_Detect_L_Illum 1;
BA_ "U_B515_MCA_MY17_Diesel_Rx" SG_ 934 Side_Detect_L_Illum 1;
BA_ "U_B479_MY17_Diesel_Rx" SG_ 934 Side_Detect_L_Illum 1;
BA_ "U_B479_MY17_Gas_Rx" SG_ 934 Side_Detect_L_Illum 1;
BA_ "GenSigStartValue" SG_ 934 Side_Detect_L_Illum 100;
BA_ "GenSigStartValueInteger" SG_ 934 Side_Detect_L_Illum 100;
BA_ "CrossOver_InfoCAN" SG_ 934 Side_Detect_L_Illum 1;
BA_ "U_CX727_MY2021_Tx" SG_ 934 CtaInnrLeft_D_Stat 1;
BA_ "U_CX430_MY2021_Tx" SG_ 934 CtaInnrLeft_D_Stat 1;
BA_ "U_U611_U625_MY20_Phev_Tx" SG_ 934 CtaInnrLeft_D_Stat 1;
BA_ "U_CX482_CX483_MY20_Tx" SG_ 934 CtaInnrLeft_D_Stat 1;
BA_ "U_U611_U625_MY20_Hev_Tx" SG_ 934 CtaInnrLeft_D_Stat 1;
BA_ "U_U611_U625_MY20_Gas_Tx" SG_ 934 CtaInnrLeft_D_Stat 1;
BA_ "U_C519_MY18_5_Gas_Tx" SG_ 934 CtaInnrLeft_D_Stat 1;
BA_ "U_C519_MY18_5_Diesel_Tx" SG_ 934 CtaInnrLeft_D_Stat 1;
BA_ "U_B515_MCA_MY17_Gas_Tx" SG_ 934 CtaInnrLeft_D_Stat 1;
BA_ "U_B515_MCA_MY17_Diesel_Tx" SG_ 934 CtaInnrLeft_D_Stat 1;
BA_ "U_B479_MY17_Diesel_Tx" SG_ 934 CtaInnrLeft_D_Stat 1;
BA_ "U_B479_MY17_Gas_Tx" SG_ 934 CtaInnrLeft_D_Stat 1;
BA_ "U_CX727_MY2021_Rx" SG_ 934 CtaInnrLeft_D_Stat 1;
BA_ "U_CX430_MY2021_Rx" SG_ 934 CtaInnrLeft_D_Stat 1;
BA_ "U_U611_U625_MY20_Phev_Rx" SG_ 934 CtaInnrLeft_D_Stat 1;
BA_ "U_CX482_CX483_MY20_Rx" SG_ 934 CtaInnrLeft_D_Stat 1;
BA_ "U_U611_U625_MY20_Hev_Rx" SG_ 934 CtaInnrLeft_D_Stat 1;
BA_ "U_U611_U625_MY20_Gas_Rx" SG_ 934 CtaInnrLeft_D_Stat 1;
BA_ "U_C519_MY18_5_Gas_Rx" SG_ 934 CtaInnrLeft_D_Stat 1;
BA_ "U_C519_MY18_5_Diesel_Rx" SG_ 934 CtaInnrLeft_D_Stat 1;
BA_ "U_B562LC_MY15_Gas_Rx" SG_ 934 CtaInnrLeft_D_Stat 1;
BA_ "GenSigSendType" SG_ 934 CtaInnrLeft_D_Stat 3;
BA_ "CrossOver_InfoCAN" SG_ 934 CtaInnrLeft_D_Stat 1;
BA_ "U_CX727_MY2021_Tx" SG_ 934 CtaSnsLeft_D_Stat 1;
BA_ "U_CX430_MY2021_Tx" SG_ 934 CtaSnsLeft_D_Stat 1;
BA_ "U_U611_U625_MY20_Phev_Tx" SG_ 934 CtaSnsLeft_D_Stat 1;
BA_ "U_CX482_CX483_MY20_Tx" SG_ 934 CtaSnsLeft_D_Stat 1;
BA_ "U_U611_U625_MY20_Hev_Tx" SG_ 934 CtaSnsLeft_D_Stat 1;
BA_ "U_U611_U625_MY20_Gas_Tx" SG_ 934 CtaSnsLeft_D_Stat 1;
BA_ "U_C519_MY18_5_Gas_Tx" SG_ 934 CtaSnsLeft_D_Stat 1;
BA_ "U_C519_MY18_5_Diesel_Tx" SG_ 934 CtaSnsLeft_D_Stat 1;
BA_ "U_B515_MCA_MY17_Gas_Tx" SG_ 934 CtaSnsLeft_D_Stat 1;
BA_ "U_B515_MCA_MY17_Diesel_Tx" SG_ 934 CtaSnsLeft_D_Stat 1;
BA_ "U_B479_MY17_Diesel_Tx" SG_ 934 CtaSnsLeft_D_Stat 1;
BA_ "U_B479_MY17_Gas_Tx" SG_ 934 CtaSnsLeft_D_Stat 1;
BA_ "U_CX727_MY2021_Rx" SG_ 934 CtaSnsLeft_D_Stat 1;
BA_ "U_CX430_MY2021_Rx" SG_ 934 CtaSnsLeft_D_Stat 1;
BA_ "U_U611_U625_MY20_Phev_Rx" SG_ 934 CtaSnsLeft_D_Stat 1;
BA_ "U_CX482_CX483_MY20_Rx" SG_ 934 CtaSnsLeft_D_Stat 1;
BA_ "U_U611_U625_MY20_Hev_Rx" SG_ 934 CtaSnsLeft_D_Stat 1;
BA_ "U_U611_U625_MY20_Gas_Rx" SG_ 934 CtaSnsLeft_D_Stat 1;
BA_ "U_C519_MY18_5_Gas_Rx" SG_ 934 CtaSnsLeft_D_Stat 1;
BA_ "U_C519_MY18_5_Diesel_Rx" SG_ 934 CtaSnsLeft_D_Stat 1;
BA_ "U_B515_MCA_MY17_Gas_Rx" SG_ 934 CtaSnsLeft_D_Stat 1;
BA_ "U_B515_MCA_MY17_Diesel_Rx" SG_ 934 CtaSnsLeft_D_Stat 1;
BA_ "U_B479_MY17_Diesel_Rx" SG_ 934 CtaSnsLeft_D_Stat 1;
BA_ "U_B479_MY17_Gas_Rx" SG_ 934 CtaSnsLeft_D_Stat 1;
BA_ "U_B562LC_MY15_Gas_Rx" SG_ 934 CtaSnsLeft_D_Stat 1;
BA_ "GenSigSendType" SG_ 934 CtaSnsLeft_D_Stat 3;
BA_ "CrossOver_InfoCAN" SG_ 934 CtaSnsLeft_D_Stat 1;
BA_ "U_CX727_MY2021_Tx" SG_ 934 SodDetctLeft_D_Stat 1;
BA_ "U_CX430_MY2021_Tx" SG_ 934 SodDetctLeft_D_Stat 1;
BA_ "U_U611_U625_MY20_Phev_Tx" SG_ 934 SodDetctLeft_D_Stat 1;
BA_ "U_CX482_CX483_MY20_Tx" SG_ 934 SodDetctLeft_D_Stat 1;
BA_ "U_U611_U625_MY20_Hev_Tx" SG_ 934 SodDetctLeft_D_Stat 1;
BA_ "U_U611_U625_MY20_Gas_Tx" SG_ 934 SodDetctLeft_D_Stat 1;
BA_ "U_C519_MY18_5_Gas_Tx" SG_ 934 SodDetctLeft_D_Stat 1;
BA_ "U_C519_MY18_5_Diesel_Tx" SG_ 934 SodDetctLeft_D_Stat 1;
BA_ "U_B515_MCA_MY17_Gas_Tx" SG_ 934 SodDetctLeft_D_Stat 1;
BA_ "U_B515_MCA_MY17_Diesel_Tx" SG_ 934 SodDetctLeft_D_Stat 1;
BA_ "U_B479_MY17_Diesel_Tx" SG_ 934 SodDetctLeft_D_Stat 1;
BA_ "U_B479_MY17_Gas_Tx" SG_ 934 SodDetctLeft_D_Stat 1;
BA_ "GenSigSendType" SG_ 934 SodDetctLeft_D_Stat 3;
BA_ "CrossOver_InfoCAN" SG_ 934 SodDetctLeft_D_Stat 1;
BA_ "U_CX727_MY2021_Tx" SG_ 934 CtaLeft_D_Stat 1;
BA_ "U_CX430_MY2021_Tx" SG_ 934 CtaLeft_D_Stat 1;
BA_ "U_U611_U625_MY20_Phev_Tx" SG_ 934 CtaLeft_D_Stat 1;
BA_ "U_CX482_CX483_MY20_Tx" SG_ 934 CtaLeft_D_Stat 1;
BA_ "U_U611_U625_MY20_Hev_Tx" SG_ 934 CtaLeft_D_Stat 1;
BA_ "U_U611_U625_MY20_Gas_Tx" SG_ 934 CtaLeft_D_Stat 1;
BA_ "U_C519_MY18_5_Gas_Tx" SG_ 934 CtaLeft_D_Stat 1;
BA_ "U_C519_MY18_5_Diesel_Tx" SG_ 934 CtaLeft_D_Stat 1;
BA_ "U_B515_MCA_MY17_Gas_Tx" SG_ 934 CtaLeft_D_Stat 1;
BA_ "U_B515_MCA_MY17_Diesel_Tx" SG_ 934 CtaLeft_D_Stat 1;
BA_ "U_B479_MY17_Diesel_Tx" SG_ 934 CtaLeft_D_Stat 1;
BA_ "U_B479_MY17_Gas_Tx" SG_ 934 CtaLeft_D_Stat 1;
BA_ "U_CX727_MY2021_Rx" SG_ 934 CtaLeft_D_Stat 1;
BA_ "U_CX430_MY2021_Rx" SG_ 934 CtaLeft_D_Stat 1;
BA_ "U_U611_U625_MY20_Phev_Rx" SG_ 934 CtaLeft_D_Stat 1;
BA_ "U_CX482_CX483_MY20_Rx" SG_ 934 CtaLeft_D_Stat 1;
BA_ "U_U611_U625_MY20_Hev_Rx" SG_ 934 CtaLeft_D_Stat 1;
BA_ "U_U611_U625_MY20_Gas_Rx" SG_ 934 CtaLeft_D_Stat 1;
BA_ "U_C519_MY18_5_Gas_Rx" SG_ 934 CtaLeft_D_Stat 1;
BA_ "U_C519_MY18_5_Diesel_Rx" SG_ 934 CtaLeft_D_Stat 1;
BA_ "U_B515_MCA_MY17_Gas_Rx" SG_ 934 CtaLeft_D_Stat 1;
BA_ "U_B515_MCA_MY17_Diesel_Rx" SG_ 934 CtaLeft_D_Stat 1;
BA_ "U_B479_MY17_Diesel_Rx" SG_ 934 CtaLeft_D_Stat 1;
BA_ "U_B479_MY17_Gas_Rx" SG_ 934 CtaLeft_D_Stat 1;
BA_ "GenSigSendType" SG_ 934 CtaLeft_D_Stat 3;
BA_ "CrossOver_InfoCAN" SG_ 934 CtaLeft_D_Stat 1;
BA_ "U_CX727_MY2021_Tx" SG_ 934 CtaAlrtLeft_D_Stat 1;
BA_ "U_CX430_MY2021_Tx" SG_ 934 CtaAlrtLeft_D_Stat 1;
BA_ "U_U611_U625_MY20_Phev_Tx" SG_ 934 CtaAlrtLeft_D_Stat 1;
BA_ "U_CX482_CX483_MY20_Tx" SG_ 934 CtaAlrtLeft_D_Stat 1;
BA_ "U_U611_U625_MY20_Hev_Tx" SG_ 934 CtaAlrtLeft_D_Stat 1;
BA_ "U_U611_U625_MY20_Gas_Tx" SG_ 934 CtaAlrtLeft_D_Stat 1;
BA_ "U_C519_MY18_5_Gas_Tx" SG_ 934 CtaAlrtLeft_D_Stat 1;
BA_ "U_C519_MY18_5_Diesel_Tx" SG_ 934 CtaAlrtLeft_D_Stat 1;
BA_ "U_B515_MCA_MY17_Gas_Tx" SG_ 934 CtaAlrtLeft_D_Stat 1;
BA_ "U_B515_MCA_MY17_Diesel_Tx" SG_ 934 CtaAlrtLeft_D_Stat 1;
BA_ "U_B479_MY17_Diesel_Tx" SG_ 934 CtaAlrtLeft_D_Stat 1;
BA_ "U_B479_MY17_Gas_Tx" SG_ 934 CtaAlrtLeft_D_Stat 1;
BA_ "U_CX727_MY2021_Rx" SG_ 934 CtaAlrtLeft_D_Stat 1;
BA_ "U_P702_MY2021_Rx" SG_ 934 CtaAlrtLeft_D_Stat 1;
BA_ "U_CX430_MY2021_Rx" SG_ 934 CtaAlrtLeft_D_Stat 1;
BA_ "U_U611_U625_MY20_Phev_Rx" SG_ 934 CtaAlrtLeft_D_Stat 1;
BA_ "U_CX482_CX483_MY20_Rx" SG_ 934 CtaAlrtLeft_D_Stat 1;
BA_ "U_U611_U625_MY20_Hev_Rx" SG_ 934 CtaAlrtLeft_D_Stat 1;
BA_ "U_U611_U625_MY20_Gas_Rx" SG_ 934 CtaAlrtLeft_D_Stat 1;
BA_ "U_C519_MY18_5_Gas_Rx" SG_ 934 CtaAlrtLeft_D_Stat 1;
BA_ "U_C519_MY18_5_Diesel_Rx" SG_ 934 CtaAlrtLeft_D_Stat 1;
BA_ "U_B515_MCA_MY17_Gas_Rx" SG_ 934 CtaAlrtLeft_D_Stat 1;
BA_ "U_B515_MCA_MY17_Diesel_Rx" SG_ 934 CtaAlrtLeft_D_Stat 1;
BA_ "U_B479_MY17_Diesel_Rx" SG_ 934 CtaAlrtLeft_D_Stat 1;
BA_ "U_B479_MY17_Gas_Rx" SG_ 934 CtaAlrtLeft_D_Stat 1;
BA_ "GenSigSendType" SG_ 934 CtaAlrtLeft_D_Stat 3;
BA_ "CrossOver_InfoCAN" SG_ 934 CtaAlrtLeft_D_Stat 1;
BA_ "U_CX727_MY2021_Tx" SG_ 934 SodLeft_D_Stat 1;
BA_ "U_CX430_MY2021_Tx" SG_ 934 SodLeft_D_Stat 1;
BA_ "U_U611_U625_MY20_Phev_Tx" SG_ 934 SodLeft_D_Stat 1;
BA_ "U_CX482_CX483_MY20_Tx" SG_ 934 SodLeft_D_Stat 1;
BA_ "U_U611_U625_MY20_Hev_Tx" SG_ 934 SodLeft_D_Stat 1;
BA_ "U_U611_U625_MY20_Gas_Tx" SG_ 934 SodLeft_D_Stat 1;
BA_ "U_C519_MY18_5_Gas_Tx" SG_ 934 SodLeft_D_Stat 1;
BA_ "U_C519_MY18_5_Diesel_Tx" SG_ 934 SodLeft_D_Stat 1;
BA_ "U_B515_MCA_MY17_Gas_Tx" SG_ 934 SodLeft_D_Stat 1;
BA_ "U_B515_MCA_MY17_Diesel_Tx" SG_ 934 SodLeft_D_Stat 1;
BA_ "U_B479_MY17_Diesel_Tx" SG_ 934 SodLeft_D_Stat 1;
BA_ "U_B479_MY17_Gas_Tx" SG_ 934 SodLeft_D_Stat 1;
BA_ "U_CX727_MY2021_Rx" SG_ 934 SodLeft_D_Stat 1;
BA_ "U_CX430_MY2021_Rx" SG_ 934 SodLeft_D_Stat 1;
BA_ "U_U611_U625_MY20_Phev_Rx" SG_ 934 SodLeft_D_Stat 1;
BA_ "U_CX482_CX483_MY20_Rx" SG_ 934 SodLeft_D_Stat 1;
BA_ "U_U611_U625_MY20_Hev_Rx" SG_ 934 SodLeft_D_Stat 1;
BA_ "U_U611_U625_MY20_Gas_Rx" SG_ 934 SodLeft_D_Stat 1;
BA_ "U_C519_MY18_5_Gas_Rx" SG_ 934 SodLeft_D_Stat 1;
BA_ "U_C519_MY18_5_Diesel_Rx" SG_ 934 SodLeft_D_Stat 1;
BA_ "U_B515_MCA_MY17_Gas_Rx" SG_ 934 SodLeft_D_Stat 1;
BA_ "U_B515_MCA_MY17_Diesel_Rx" SG_ 934 SodLeft_D_Stat 1;
BA_ "U_B479_MY17_Diesel_Rx" SG_ 934 SodLeft_D_Stat 1;
BA_ "U_B479_MY17_Gas_Rx" SG_ 934 SodLeft_D_Stat 1;
BA_ "GenSigSendType" SG_ 934 SodLeft_D_Stat 3;
BA_ "GenSigStartValue" SG_ 934 SodLeft_D_Stat 2;
BA_ "GenSigStartValueInteger" SG_ 934 SodLeft_D_Stat 2;
BA_ "CrossOver_InfoCAN" SG_ 934 SodLeft_D_Stat 1;
BA_ "U_CX727_MY2021_Tx" SG_ 934 SodSnsLeft_D_Stat 1;
BA_ "U_CX430_MY2021_Tx" SG_ 934 SodSnsLeft_D_Stat 1;
BA_ "U_U611_U625_MY20_Phev_Tx" SG_ 934 SodSnsLeft_D_Stat 1;
BA_ "U_CX482_CX483_MY20_Tx" SG_ 934 SodSnsLeft_D_Stat 1;
BA_ "U_U611_U625_MY20_Hev_Tx" SG_ 934 SodSnsLeft_D_Stat 1;
BA_ "U_U611_U625_MY20_Gas_Tx" SG_ 934 SodSnsLeft_D_Stat 1;
BA_ "U_C519_MY18_5_Gas_Tx" SG_ 934 SodSnsLeft_D_Stat 1;
BA_ "U_C519_MY18_5_Diesel_Tx" SG_ 934 SodSnsLeft_D_Stat 1;
BA_ "U_B515_MCA_MY17_Gas_Tx" SG_ 934 SodSnsLeft_D_Stat 1;
BA_ "U_B515_MCA_MY17_Diesel_Tx" SG_ 934 SodSnsLeft_D_Stat 1;
BA_ "U_B479_MY17_Diesel_Tx" SG_ 934 SodSnsLeft_D_Stat 1;
BA_ "U_B479_MY17_Gas_Tx" SG_ 934 SodSnsLeft_D_Stat 1;
BA_ "U_P702_MY2021_Rx" SG_ 934 SodSnsLeft_D_Stat 1;
BA_ "U_CX727_MY2021_Rx" SG_ 934 SodSnsLeft_D_Stat 1;
BA_ "U_CX430_MY2021_Rx" SG_ 934 SodSnsLeft_D_Stat 1;
BA_ "U_U611_U625_MY20_Phev_Rx" SG_ 934 SodSnsLeft_D_Stat 1;
BA_ "U_CX482_CX483_MY20_Rx" SG_ 934 SodSnsLeft_D_Stat 1;
BA_ "U_U611_U625_MY20_Hev_Rx" SG_ 934 SodSnsLeft_D_Stat 1;
BA_ "U_U611_U625_MY20_Gas_Rx" SG_ 934 SodSnsLeft_D_Stat 1;
BA_ "U_C519_MY18_5_Gas_Rx" SG_ 934 SodSnsLeft_D_Stat 1;
BA_ "U_C519_MY18_5_Diesel_Rx" SG_ 934 SodSnsLeft_D_Stat 1;
BA_ "U_B515_MCA_MY17_Gas_Rx" SG_ 934 SodSnsLeft_D_Stat 1;
BA_ "U_B515_MCA_MY17_Diesel_Rx" SG_ 934 SodSnsLeft_D_Stat 1;
BA_ "U_B479_MY17_Diesel_Rx" SG_ 934 SodSnsLeft_D_Stat 1;
BA_ "U_B479_MY17_Gas_Rx" SG_ 934 SodSnsLeft_D_Stat 1;
BA_ "U_B562LC_MY15_Gas_Rx" SG_ 934 SodSnsLeft_D_Stat 1;
BA_ "GenSigSendType" SG_ 934 SodSnsLeft_D_Stat 3;
BA_ "CrossOver_InfoCAN" SG_ 934 SodSnsLeft_D_Stat 1;
BA_ "U_CX727_MY2021_Tx" SG_ 934 SodAlrtLeft_D_Stat 1;
BA_ "U_CX430_MY2021_Tx" SG_ 934 SodAlrtLeft_D_Stat 1;
BA_ "U_U611_U625_MY20_Phev_Tx" SG_ 934 SodAlrtLeft_D_Stat 1;
BA_ "U_CX482_CX483_MY20_Tx" SG_ 934 SodAlrtLeft_D_Stat 1;
BA_ "U_U611_U625_MY20_Hev_Tx" SG_ 934 SodAlrtLeft_D_Stat 1;
BA_ "U_U611_U625_MY20_Gas_Tx" SG_ 934 SodAlrtLeft_D_Stat 1;
BA_ "U_C519_MY18_5_Gas_Tx" SG_ 934 SodAlrtLeft_D_Stat 1;
BA_ "U_C519_MY18_5_Diesel_Tx" SG_ 934 SodAlrtLeft_D_Stat 1;
BA_ "U_B515_MCA_MY17_Gas_Tx" SG_ 934 SodAlrtLeft_D_Stat 1;
BA_ "U_B515_MCA_MY17_Diesel_Tx" SG_ 934 SodAlrtLeft_D_Stat 1;
BA_ "U_B479_MY17_Diesel_Tx" SG_ 934 SodAlrtLeft_D_Stat 1;
BA_ "U_B479_MY17_Gas_Tx" SG_ 934 SodAlrtLeft_D_Stat 1;
BA_ "U_CX727_MY2021_Rx" SG_ 934 SodAlrtLeft_D_Stat 1;
BA_ "U_P702_MY2021_Rx" SG_ 934 SodAlrtLeft_D_Stat 1;
BA_ "U_CX430_MY2021_Rx" SG_ 934 SodAlrtLeft_D_Stat 1;
BA_ "U_U611_U625_MY20_Phev_Rx" SG_ 934 SodAlrtLeft_D_Stat 1;
BA_ "U_CX482_CX483_MY20_Rx" SG_ 934 SodAlrtLeft_D_Stat 1;
BA_ "U_U611_U625_MY20_Hev_Rx" SG_ 934 SodAlrtLeft_D_Stat 1;
BA_ "U_U611_U625_MY20_Gas_Rx" SG_ 934 SodAlrtLeft_D_Stat 1;
BA_ "U_C519_MY18_5_Gas_Rx" SG_ 934 SodAlrtLeft_D_Stat 1;
BA_ "U_C519_MY18_5_Diesel_Rx" SG_ 934 SodAlrtLeft_D_Stat 1;
BA_ "U_B515_MCA_MY17_Gas_Rx" SG_ 934 SodAlrtLeft_D_Stat 1;
BA_ "U_B515_MCA_MY17_Diesel_Rx" SG_ 934 SodAlrtLeft_D_Stat 1;
BA_ "U_B479_MY17_Diesel_Rx" SG_ 934 SodAlrtLeft_D_Stat 1;
BA_ "U_B479_MY17_Gas_Rx" SG_ 934 SodAlrtLeft_D_Stat 1;
BA_ "GenSigSendType" SG_ 934 SodAlrtLeft_D_Stat 3;
BA_ "CrossOver_InfoCAN" SG_ 934 SodAlrtLeft_D_Stat 1;
BA_ "U_CX727_MY2021_Tx" SG_ 934 SodWarnLeft_Prd_Rq 1;
BA_ "U_CX430_MY2021_Tx" SG_ 934 SodWarnLeft_Prd_Rq 1;
BA_ "U_U611_U625_MY20_Phev_Tx" SG_ 934 SodWarnLeft_Prd_Rq 1;
BA_ "U_CX482_CX483_MY20_Tx" SG_ 934 SodWarnLeft_Prd_Rq 1;
BA_ "U_U611_U625_MY20_Hev_Tx" SG_ 934 SodWarnLeft_Prd_Rq 1;
BA_ "U_U611_U625_MY20_Gas_Tx" SG_ 934 SodWarnLeft_Prd_Rq 1;
BA_ "U_C519_MY18_5_Gas_Tx" SG_ 934 SodWarnLeft_Prd_Rq 1;
BA_ "U_C519_MY18_5_Diesel_Tx" SG_ 934 SodWarnLeft_Prd_Rq 1;
BA_ "U_B515_MCA_MY17_Gas_Tx" SG_ 934 SodWarnLeft_Prd_Rq 1;
BA_ "U_B515_MCA_MY17_Diesel_Tx" SG_ 934 SodWarnLeft_Prd_Rq 1;
BA_ "U_B479_MY17_Diesel_Tx" SG_ 934 SodWarnLeft_Prd_Rq 1;
BA_ "U_B479_MY17_Gas_Tx" SG_ 934 SodWarnLeft_Prd_Rq 1;
BA_ "U_CX727_MY2021_Rx" SG_ 934 SodWarnLeft_Prd_Rq 1;
BA_ "U_P702_MY2021_Rx" SG_ 934 SodWarnLeft_Prd_Rq 1;
BA_ "U_CX430_MY2021_Rx" SG_ 934 SodWarnLeft_Prd_Rq 1;
BA_ "U_U611_U625_MY20_Phev_Rx" SG_ 934 SodWarnLeft_Prd_Rq 1;
BA_ "U_CX482_CX483_MY20_Rx" SG_ 934 SodWarnLeft_Prd_Rq 1;
BA_ "U_U611_U625_MY20_Hev_Rx" SG_ 934 SodWarnLeft_Prd_Rq 1;
BA_ "U_U611_U625_MY20_Gas_Rx" SG_ 934 SodWarnLeft_Prd_Rq 1;
BA_ "U_C519_MY18_5_Gas_Rx" SG_ 934 SodWarnLeft_Prd_Rq 1;
BA_ "U_C519_MY18_5_Diesel_Rx" SG_ 934 SodWarnLeft_Prd_Rq 1;
BA_ "U_B515_MCA_MY17_Gas_Rx" SG_ 934 SodWarnLeft_Prd_Rq 1;
BA_ "U_B515_MCA_MY17_Diesel_Rx" SG_ 934 SodWarnLeft_Prd_Rq 1;
BA_ "U_B479_MY17_Diesel_Rx" SG_ 934 SodWarnLeft_Prd_Rq 1;
BA_ "U_B479_MY17_Gas_Rx" SG_ 934 SodWarnLeft_Prd_Rq 1;
BA_ "GenSigStartValue" SG_ 934 SodWarnLeft_Prd_Rq 14;
BA_ "GenSigStartValueInteger" SG_ 934 SodWarnLeft_Prd_Rq 14;
BA_ "CrossOver_InfoCAN" SG_ 934 SodWarnLeft_Prd_Rq 1;
BA_ "U_CX727_MY2021_Tx" SG_ 934 SodInnrLeft_D_Stat 1;
BA_ "U_CX430_MY2021_Tx" SG_ 934 SodInnrLeft_D_Stat 1;
BA_ "U_U611_U625_MY20_Phev_Tx" SG_ 934 SodInnrLeft_D_Stat 1;
BA_ "U_CX482_CX483_MY20_Tx" SG_ 934 SodInnrLeft_D_Stat 1;
BA_ "U_U611_U625_MY20_Hev_Tx" SG_ 934 SodInnrLeft_D_Stat 1;
BA_ "U_U611_U625_MY20_Gas_Tx" SG_ 934 SodInnrLeft_D_Stat 1;
BA_ "U_C519_MY18_5_Gas_Tx" SG_ 934 SodInnrLeft_D_Stat 1;
BA_ "U_C519_MY18_5_Diesel_Tx" SG_ 934 SodInnrLeft_D_Stat 1;
BA_ "U_B515_MCA_MY17_Gas_Tx" SG_ 934 SodInnrLeft_D_Stat 1;
BA_ "U_B515_MCA_MY17_Diesel_Tx" SG_ 934 SodInnrLeft_D_Stat 1;
BA_ "U_B479_MY17_Diesel_Tx" SG_ 934 SodInnrLeft_D_Stat 1;
BA_ "U_B479_MY17_Gas_Tx" SG_ 934 SodInnrLeft_D_Stat 1;
BA_ "U_CX727_MY2021_Rx" SG_ 934 SodInnrLeft_D_Stat 1;
BA_ "U_CX430_MY2021_Rx" SG_ 934 SodInnrLeft_D_Stat 1;
BA_ "U_U611_U625_MY20_Phev_Rx" SG_ 934 SodInnrLeft_D_Stat 1;
BA_ "U_CX482_CX483_MY20_Rx" SG_ 934 SodInnrLeft_D_Stat 1;
BA_ "U_U611_U625_MY20_Hev_Rx" SG_ 934 SodInnrLeft_D_Stat 1;
BA_ "U_U611_U625_MY20_Gas_Rx" SG_ 934 SodInnrLeft_D_Stat 1;
BA_ "U_C519_MY18_5_Gas_Rx" SG_ 934 SodInnrLeft_D_Stat 1;
BA_ "U_C519_MY18_5_Diesel_Rx" SG_ 934 SodInnrLeft_D_Stat 1;
BA_ "U_B562LC_MY15_Gas_Rx" SG_ 934 SodInnrLeft_D_Stat 1;
BA_ "GenSigSendType" SG_ 934 SodInnrLeft_D_Stat 3;
BA_ "CrossOver_InfoCAN" SG_ 934 SodInnrLeft_D_Stat 1;
BA_ "GenSigSendType" SG_ 969 Dimming_Level_Stat 3;
BA_ "GenSigSendType" SG_ 969 Current_Color_Stat 3;
BA_ "GenSigStartValue" SG_ 969 Current_Color_Stat 8;
BA_ "GenSigStartValueInteger" SG_ 969 Current_Color_Stat 8;
BA_ "GenSigSendType" SG_ 969 BlendedColorRed_Stat 3;
BA_ "GenSigSendType" SG_ 969 BlendedColorGreen_Stat 3;
BA_ "GenSigSendType" SG_ 969 BlendedColorBlue_Stat 3;
BA_ "GenSigSendType" SG_ 969 BlendedColor_Stat 3;
BA_ "GenSigStartValue" SG_ 969 BlendedColor_Stat 2;
BA_ "GenSigStartValueInteger" SG_ 969 BlendedColor_Stat 2;
BA_ "U_B479_MY17_Gas_Rx" SG_ 969 TurnLampRrOut_B_Stat 1;
BA_ "GenSigSendType" SG_ 969 TurnLampRrOut_B_Stat 3;
BA_ "ContentDependant" SG_ 969 TurnLampRrOut_B_Stat 1;
BA_ "WakeupSignal" SG_ 969 TurnLampRrOut_B_Stat 1;
BA_ "U_B479_MY17_Gas_Rx" SG_ 969 TurnLampRlOut_B_Stat 1;
BA_ "GenSigSendType" SG_ 969 TurnLampRlOut_B_Stat 3;
BA_ "ContentDependant" SG_ 969 TurnLampRlOut_B_Stat 1;
BA_ "WakeupSignal" SG_ 969 TurnLampRlOut_B_Stat 1;
BA_ "U_CX727_MY2021_Rx" SG_ 1070 HiElPwInhbt_B_Stat_UB 1;
BA_ "U_P702_MY2021_Rx" SG_ 1070 HiElPwInhbt_B_Stat_UB 1;
BA_ "U_CX430_MY2021_Rx" SG_ 1070 HiElPwInhbt_B_Stat_UB 1;
BA_ "U_U611_U625_MY20_Phev_Rx" SG_ 1070 HiElPwInhbt_B_Stat_UB 1;
BA_ "U_CX482_CX483_MY20_Rx" SG_ 1070 HiElPwInhbt_B_Stat_UB 1;
BA_ "U_U611_U625_MY20_Hev_Rx" SG_ 1070 HiElPwInhbt_B_Stat_UB 1;
BA_ "U_U611_U625_MY20_Gas_Rx" SG_ 1070 HiElPwInhbt_B_Stat_UB 1;
BA_ "U_C490_MY18_Rx" SG_ 1070 HiElPwInhbt_B_Stat_UB 1;
BA_ "U_C519_MY18_5_Gas_Rx" SG_ 1070 HiElPwInhbt_B_Stat_UB 1;
BA_ "U_C519_MY18_5_Diesel_Rx" SG_ 1070 HiElPwInhbt_B_Stat_UB 1;
BA_ "U_B515_MCA_MY17_Gas_Rx" SG_ 1070 HiElPwInhbt_B_Stat_UB 1;
BA_ "U_B515_MCA_MY17_Diesel_Rx" SG_ 1070 HiElPwInhbt_B_Stat_UB 1;
BA_ "U_B479_MY17_Diesel_Rx" SG_ 1070 HiElPwInhbt_B_Stat_UB 1;
BA_ "U_B479_MY17_Gas_Rx" SG_ 1070 HiElPwInhbt_B_Stat_UB 1;
BA_ "U_CX727_MY2021_Rx" SG_ 1070 HiElPwInhbt_B_Stat 1;
BA_ "U_P702_MY2021_Rx" SG_ 1070 HiElPwInhbt_B_Stat 1;
BA_ "U_CX430_MY2021_Rx" SG_ 1070 HiElPwInhbt_B_Stat 1;
BA_ "U_U611_U625_MY20_Phev_Rx" SG_ 1070 HiElPwInhbt_B_Stat 1;
BA_ "U_CX482_CX483_MY20_Rx" SG_ 1070 HiElPwInhbt_B_Stat 1;
BA_ "U_U611_U625_MY20_Hev_Rx" SG_ 1070 HiElPwInhbt_B_Stat 1;
BA_ "U_U611_U625_MY20_Gas_Rx" SG_ 1070 HiElPwInhbt_B_Stat 1;
BA_ "U_C490_MY18_Rx" SG_ 1070 HiElPwInhbt_B_Stat 1;
BA_ "U_C519_MY18_5_Gas_Rx" SG_ 1070 HiElPwInhbt_B_Stat 1;
BA_ "U_C519_MY18_5_Diesel_Rx" SG_ 1070 HiElPwInhbt_B_Stat 1;
BA_ "U_B515_MCA_MY17_Gas_Rx" SG_ 1070 HiElPwInhbt_B_Stat 1;
BA_ "U_B515_MCA_MY17_Diesel_Rx" SG_ 1070 HiElPwInhbt_B_Stat 1;
BA_ "U_B479_MY17_Diesel_Rx" SG_ 1070 HiElPwInhbt_B_Stat 1;
BA_ "U_B479_MY17_Gas_Rx" SG_ 1070 HiElPwInhbt_B_Stat 1;
BA_ "ContentDependant" SG_ 1070 HiElPwInhbt_B_Stat 1;
BA_ "CrossOver_InfoCAN" SG_ 1070 HiElPwInhbt_B_Stat 1;
BA_ "CrossOver_InfoCAN" SG_ 1070 StopStrtStdby_D_Indic 1;
BA_ "GenSigSendType" SG_ 1070 CoolantFanStepAct_UB 3;
BA_ "U_P702_MY2021_Rx" SG_ 1070 CoolantFanStepAct_UB 1;
BA_ "U_CX727_MY2021_Rx" SG_ 1070 CoolantFanStepAct_UB 1;
BA_ "U_H567_MY20_Rx" SG_ 1070 CoolantFanStepAct_UB 1;
BA_ "U_CX430_MY2021_Rx" SG_ 1070 CoolantFanStepAct_UB 1;
BA_ "U_U611_U625_MY20_Phev_Rx" SG_ 1070 CoolantFanStepAct_UB 1;
BA_ "U_CX482_CX483_MY20_Rx" SG_ 1070 CoolantFanStepAct_UB 1;
BA_ "U_U611_U625_MY20_Hev_Rx" SG_ 1070 CoolantFanStepAct_UB 1;
BA_ "U_U611_U625_MY20_Gas_Rx" SG_ 1070 CoolantFanStepAct_UB 1;
BA_ "U_B500_MY18_Diesel_Rx" SG_ 1070 CoolantFanStepAct_UB 1;
BA_ "U_B500_MY18_Gas_Rx" SG_ 1070 CoolantFanStepAct_UB 1;
BA_ "U_C519_MY18_5_Gas_Rx" SG_ 1070 CoolantFanStepAct_UB 1;
BA_ "U_C519_MY18_5_Diesel_Rx" SG_ 1070 CoolantFanStepAct_UB 1;
BA_ "U_B515_MCA_MY17_Gas_Rx" SG_ 1070 CoolantFanStepAct_UB 1;
BA_ "U_B515_MCA_MY17_Diesel_Rx" SG_ 1070 CoolantFanStepAct_UB 1;
BA_ "U_B479_MY17_Diesel_Rx" SG_ 1070 CoolantFanStepAct_UB 1;
BA_ "U_B479_MY17_Gas_Rx" SG_ 1070 CoolantFanStepAct_UB 1;
BA_ "GenSigSendType" SG_ 1070 CoolantFanStepAct 3;
BA_ "U_P702_MY2021_Rx" SG_ 1070 CoolantFanStepAct 1;
BA_ "U_CX727_MY2021_Rx" SG_ 1070 CoolantFanStepAct 1;
BA_ "U_H567_MY20_Rx" SG_ 1070 CoolantFanStepAct 1;
BA_ "U_CX430_MY2021_Rx" SG_ 1070 CoolantFanStepAct 1;
BA_ "U_U611_U625_MY20_Phev_Rx" SG_ 1070 CoolantFanStepAct 1;
BA_ "U_CX482_CX483_MY20_Rx" SG_ 1070 CoolantFanStepAct 1;
BA_ "U_U611_U625_MY20_Hev_Rx" SG_ 1070 CoolantFanStepAct 1;
BA_ "U_U611_U625_MY20_Gas_Rx" SG_ 1070 CoolantFanStepAct 1;
BA_ "U_B500_MY18_Diesel_Rx" SG_ 1070 CoolantFanStepAct 1;
BA_ "U_B500_MY18_Gas_Rx" SG_ 1070 CoolantFanStepAct 1;
BA_ "U_C519_MY18_5_Gas_Rx" SG_ 1070 CoolantFanStepAct 1;
BA_ "U_C519_MY18_5_Diesel_Rx" SG_ 1070 CoolantFanStepAct 1;
BA_ "U_B515_MCA_MY17_Gas_Rx" SG_ 1070 CoolantFanStepAct 1;
BA_ "U_B515_MCA_MY17_Diesel_Rx" SG_ 1070 CoolantFanStepAct 1;
BA_ "U_B479_MY17_Diesel_Rx" SG_ 1070 CoolantFanStepAct 1;
BA_ "U_B479_MY17_Gas_Rx" SG_ 1070 CoolantFanStepAct 1;
BA_ "CrossOver_InfoCAN" SG_ 1070 CoolantFanStepAct 1;
BA_ "GenSigSendType" SG_ 1070 RstrnImpactEvntStatus_UB 3;
BA_ "U_P702_MY2021_Rx" SG_ 1070 RstrnImpactEvntStatus_UB 1;
BA_ "U_CX727_MY2021_Rx" SG_ 1070 RstrnImpactEvntStatus_UB 1;
BA_ "U_CX430_MY2021_Rx" SG_ 1070 RstrnImpactEvntStatus_UB 1;
BA_ "U_U611_U625_MY20_Phev_Rx" SG_ 1070 RstrnImpactEvntStatus_UB 1;
BA_ "U_B562_MY18_Diesel_Rx" SG_ 1070 RstrnImpactEvntStatus_UB 1;
BA_ "U_U611_U625_MY20_Hev_Rx" SG_ 1070 RstrnImpactEvntStatus_UB 1;
BA_ "U_U611_U625_MY20_Gas_Rx" SG_ 1070 RstrnImpactEvntStatus_UB 1;
BA_ "U_B500_MY18_Diesel_Rx" SG_ 1070 RstrnImpactEvntStatus_UB 1;
BA_ "U_B500_MY18_Gas_Rx" SG_ 1070 RstrnImpactEvntStatus_UB 1;
BA_ "U_C490_MY18_Rx" SG_ 1070 RstrnImpactEvntStatus_UB 1;
BA_ "U_B562_MY18_Gas_Rx" SG_ 1070 RstrnImpactEvntStatus_UB 1;
BA_ "U_B515_MCA_MY17_Gas_Rx" SG_ 1070 RstrnImpactEvntStatus_UB 1;
BA_ "U_B515_MCA_MY17_Diesel_Rx" SG_ 1070 RstrnImpactEvntStatus_UB 1;
BA_ "U_B479_MY17_Diesel_Rx" SG_ 1070 RstrnImpactEvntStatus_UB 1;
BA_ "U_B479_MY17_Gas_Rx" SG_ 1070 RstrnImpactEvntStatus_UB 1;
BA_ "U_CX482_CX483_MY20_Rx" SG_ 1070 RstrnImpactEvntStatus_UB 1;
BA_ "U_C519_MY18_5_Gas_Rx" SG_ 1070 RstrnImpactEvntStatus_UB 1;
BA_ "U_C519_MY18_5_Diesel_Rx" SG_ 1070 RstrnImpactEvntStatus_UB 1;
BA_ "GenSigSendType" SG_ 1070 EngAirIn_Te_Actl_UB 3;
BA_ "U_P702_MY2021_Rx" SG_ 1070 EngAirIn_Te_Actl_UB 1;
BA_ "U_CX727_MY2021_Rx" SG_ 1070 EngAirIn_Te_Actl_UB 1;
BA_ "U_H567_MY20_Rx" SG_ 1070 EngAirIn_Te_Actl_UB 1;
BA_ "U_CX430_MY2021_Rx" SG_ 1070 EngAirIn_Te_Actl_UB 1;
BA_ "U_U611_U625_MY20_Phev_Rx" SG_ 1070 EngAirIn_Te_Actl_UB 1;
BA_ "U_CX482_CX483_MY20_Rx" SG_ 1070 EngAirIn_Te_Actl_UB 1;
BA_ "U_U611_U625_MY20_Hev_Rx" SG_ 1070 EngAirIn_Te_Actl_UB 1;
BA_ "U_U611_U625_MY20_Gas_Rx" SG_ 1070 EngAirIn_Te_Actl_UB 1;
BA_ "U_B500_MY18_Diesel_Rx" SG_ 1070 EngAirIn_Te_Actl_UB 1;
BA_ "U_B500_MY18_Gas_Rx" SG_ 1070 EngAirIn_Te_Actl_UB 1;
BA_ "U_C519_MY18_5_Gas_Rx" SG_ 1070 EngAirIn_Te_Actl_UB 1;
BA_ "U_C519_MY18_5_Diesel_Rx" SG_ 1070 EngAirIn_Te_Actl_UB 1;
BA_ "U_B515_MCA_MY17_Gas_Rx" SG_ 1070 EngAirIn_Te_Actl_UB 1;
BA_ "U_B515_MCA_MY17_Diesel_Rx" SG_ 1070 EngAirIn_Te_Actl_UB 1;
BA_ "U_B479_MY17_Diesel_Rx" SG_ 1070 EngAirIn_Te_Actl_UB 1;
BA_ "U_B479_MY17_Gas_Rx" SG_ 1070 EngAirIn_Te_Actl_UB 1;
BA_ "GenSigSendType" SG_ 1070 RstrnImpactEvntStatus 3;
BA_ "U_P702_MY2021_Rx" SG_ 1070 RstrnImpactEvntStatus 1;
BA_ "U_CX727_MY2021_Rx" SG_ 1070 RstrnImpactEvntStatus 1;
BA_ "U_CX430_MY2021_Rx" SG_ 1070 RstrnImpactEvntStatus 1;
BA_ "U_U611_U625_MY20_Phev_Rx" SG_ 1070 RstrnImpactEvntStatus 1;
BA_ "U_B562_MY18_Diesel_Rx" SG_ 1070 RstrnImpactEvntStatus 1;
BA_ "U_U611_U625_MY20_Hev_Rx" SG_ 1070 RstrnImpactEvntStatus 1;
BA_ "U_U611_U625_MY20_Gas_Rx" SG_ 1070 RstrnImpactEvntStatus 1;
BA_ "U_B500_MY18_Diesel_Rx" SG_ 1070 RstrnImpactEvntStatus 1;
BA_ "U_B500_MY18_Gas_Rx" SG_ 1070 RstrnImpactEvntStatus 1;
BA_ "U_C490_MY18_Rx" SG_ 1070 RstrnImpactEvntStatus 1;
BA_ "U_B562_MY18_Gas_Rx" SG_ 1070 RstrnImpactEvntStatus 1;
BA_ "U_B515_MCA_MY17_Gas_Rx" SG_ 1070 RstrnImpactEvntStatus 1;
BA_ "U_B515_MCA_MY17_Diesel_Rx" SG_ 1070 RstrnImpactEvntStatus 1;
BA_ "U_B479_MY17_Diesel_Rx" SG_ 1070 RstrnImpactEvntStatus 1;
BA_ "U_B479_MY17_Gas_Rx" SG_ 1070 RstrnImpactEvntStatus 1;
BA_ "U_CX482_CX483_MY20_Rx" SG_ 1070 RstrnImpactEvntStatus 1;
BA_ "U_C519_MY18_5_Gas_Rx" SG_ 1070 RstrnImpactEvntStatus 1;
BA_ "U_C519_MY18_5_Diesel_Rx" SG_ 1070 RstrnImpactEvntStatus 1;
BA_ "CrossOver_InfoCAN" SG_ 1070 RstrnImpactEvntStatus 1;
BA_ "WakeupSignal" SG_ 1070 RstrnImpactEvntStatus 1;
BA_ "GenSigSendType" SG_ 1070 EngAirIn_Te_Actl 3;
BA_ "U_P702_MY2021_Rx" SG_ 1070 EngAirIn_Te_Actl 1;
BA_ "U_CX727_MY2021_Rx" SG_ 1070 EngAirIn_Te_Actl 1;
BA_ "U_H567_MY20_Rx" SG_ 1070 EngAirIn_Te_Actl 1;
BA_ "U_CX430_MY2021_Rx" SG_ 1070 EngAirIn_Te_Actl 1;
BA_ "U_U611_U625_MY20_Phev_Rx" SG_ 1070 EngAirIn_Te_Actl 1;
BA_ "U_CX482_CX483_MY20_Rx" SG_ 1070 EngAirIn_Te_Actl 1;
BA_ "U_U611_U625_MY20_Hev_Rx" SG_ 1070 EngAirIn_Te_Actl 1;
BA_ "U_U611_U625_MY20_Gas_Rx" SG_ 1070 EngAirIn_Te_Actl 1;
BA_ "U_B500_MY18_Diesel_Rx" SG_ 1070 EngAirIn_Te_Actl 1;
BA_ "U_B500_MY18_Gas_Rx" SG_ 1070 EngAirIn_Te_Actl 1;
BA_ "U_C519_MY18_5_Gas_Rx" SG_ 1070 EngAirIn_Te_Actl 1;
BA_ "U_C519_MY18_5_Diesel_Rx" SG_ 1070 EngAirIn_Te_Actl 1;
BA_ "U_B515_MCA_MY17_Gas_Rx" SG_ 1070 EngAirIn_Te_Actl 1;
BA_ "U_B515_MCA_MY17_Diesel_Rx" SG_ 1070 EngAirIn_Te_Actl 1;
BA_ "U_B479_MY17_Diesel_Rx" SG_ 1070 EngAirIn_Te_Actl 1;
BA_ "U_B479_MY17_Gas_Rx" SG_ 1070 EngAirIn_Te_Actl 1;
BA_ "CrossOver_InfoCAN" SG_ 1070 EngAirIn_Te_Actl 1;
BA_ "GenSigSendType" SG_ 1070 EngAout_N_Actl_UB 3;
BA_ "U_P702_MY2021_Rx" SG_ 1070 EngAout_N_Actl_UB 1;
BA_ "U_CX727_MY2021_Rx" SG_ 1070 EngAout_N_Actl_UB 1;
BA_ "U_H567_MY20_Rx" SG_ 1070 EngAout_N_Actl_UB 1;
BA_ "U_CX430_MY2021_Rx" SG_ 1070 EngAout_N_Actl_UB 1;
BA_ "U_U611_U625_MY20_Phev_Rx" SG_ 1070 EngAout_N_Actl_UB 1;
BA_ "U_B562_MY18_Diesel_Rx" SG_ 1070 EngAout_N_Actl_UB 1;
BA_ "U_U611_U625_MY20_Hev_Rx" SG_ 1070 EngAout_N_Actl_UB 1;
BA_ "U_U611_U625_MY20_Gas_Rx" SG_ 1070 EngAout_N_Actl_UB 1;
BA_ "U_B500_MY18_Diesel_Rx" SG_ 1070 EngAout_N_Actl_UB 1;
BA_ "U_B500_MY18_Gas_Rx" SG_ 1070 EngAout_N_Actl_UB 1;
BA_ "U_C490_MY18_Rx" SG_ 1070 EngAout_N_Actl_UB 1;
BA_ "U_B562_MY18_Gas_Rx" SG_ 1070 EngAout_N_Actl_UB 1;
BA_ "U_B515_MCA_MY17_Gas_Rx" SG_ 1070 EngAout_N_Actl_UB 1;
BA_ "U_B515_MCA_MY17_Diesel_Rx" SG_ 1070 EngAout_N_Actl_UB 1;
BA_ "U_B479_MY17_Diesel_Rx" SG_ 1070 EngAout_N_Actl_UB 1;
BA_ "U_B479_MY17_Gas_Rx" SG_ 1070 EngAout_N_Actl_UB 1;
BA_ "U_CX482_CX483_MY20_Rx" SG_ 1070 EngAout_N_Actl_UB 1;
BA_ "U_C519_MY18_5_Gas_Rx" SG_ 1070 EngAout_N_Actl_UB 1;
BA_ "U_C519_MY18_5_Diesel_Rx" SG_ 1070 EngAout_N_Actl_UB 1;
BA_ "GenSigSendType" SG_ 1070 EngAout_N_Actl 3;
BA_ "U_P702_MY2021_Rx" SG_ 1070 EngAout_N_Actl 1;
BA_ "U_CX727_MY2021_Rx" SG_ 1070 EngAout_N_Actl 1;
BA_ "U_H567_MY20_Rx" SG_ 1070 EngAout_N_Actl 1;
BA_ "U_CX430_MY2021_Rx" SG_ 1070 EngAout_N_Actl 1;
BA_ "U_U611_U625_MY20_Phev_Rx" SG_ 1070 EngAout_N_Actl 1;
BA_ "U_B562_MY18_Diesel_Rx" SG_ 1070 EngAout_N_Actl 1;
BA_ "U_U611_U625_MY20_Hev_Rx" SG_ 1070 EngAout_N_Actl 1;
BA_ "U_U611_U625_MY20_Gas_Rx" SG_ 1070 EngAout_N_Actl 1;
BA_ "U_B500_MY18_Diesel_Rx" SG_ 1070 EngAout_N_Actl 1;
BA_ "U_B500_MY18_Gas_Rx" SG_ 1070 EngAout_N_Actl 1;
BA_ "U_C490_MY18_Rx" SG_ 1070 EngAout_N_Actl 1;
BA_ "U_B562_MY18_Gas_Rx" SG_ 1070 EngAout_N_Actl 1;
BA_ "U_B515_MCA_MY17_Gas_Rx" SG_ 1070 EngAout_N_Actl 1;
BA_ "U_B515_MCA_MY17_Diesel_Rx" SG_ 1070 EngAout_N_Actl 1;
BA_ "U_B479_MY17_Diesel_Rx" SG_ 1070 EngAout_N_Actl 1;
BA_ "U_B479_MY17_Gas_Rx" SG_ 1070 EngAout_N_Actl 1;
BA_ "U_CX482_CX483_MY20_Rx" SG_ 1070 EngAout_N_Actl 1;
BA_ "U_C519_MY18_5_Gas_Rx" SG_ 1070 EngAout_N_Actl 1;
BA_ "U_C519_MY18_5_Diesel_Rx" SG_ 1070 EngAout_N_Actl 1;
BA_ "CrossOver_InfoCAN" SG_ 1070 EngAout_N_Actl 1;
BA_ "GenSigSendType" SG_ 1070 VehVActlEng_D_Qf 3;
BA_ "U_B562_MY18_Diesel_Rx" SG_ 1070 VehVActlEng_D_Qf 1;
BA_ "U_B500_MY18_Diesel_Rx" SG_ 1070 VehVActlEng_D_Qf 1;
BA_ "U_B500_MY18_Gas_Rx" SG_ 1070 VehVActlEng_D_Qf 1;
BA_ "U_B562_MY18_Gas_Rx" SG_ 1070 VehVActlEng_D_Qf 1;
BA_ "U_VN127_MY20_Rx" SG_ 1070 VehVActlEng_D_Qf 1;
BA_ "U_H567_MY20_Rx" SG_ 1070 VehVActlEng_D_Qf 1;
BA_ "U_P702_MY2021_Rx" SG_ 1070 VehVActlEng_D_Qf 1;
BA_ "U_C490_MY18_Rx" SG_ 1070 VehVActlEng_D_Qf 1;
BA_ "U_B562LC_MY15_Gas_Rx" SG_ 1070 VehVActlEng_D_Qf 1;
BA_ "U_CX727_MY2021_Rx" SG_ 1070 VehVActlEng_D_Qf 1;
BA_ "U_CX430_MY2021_Rx" SG_ 1070 VehVActlEng_D_Qf 1;
BA_ "U_U611_U625_MY20_Phev_Rx" SG_ 1070 VehVActlEng_D_Qf 1;
BA_ "U_CX482_CX483_MY20_Rx" SG_ 1070 VehVActlEng_D_Qf 1;
BA_ "U_U611_U625_MY20_Hev_Rx" SG_ 1070 VehVActlEng_D_Qf 1;
BA_ "U_U611_U625_MY20_Gas_Rx" SG_ 1070 VehVActlEng_D_Qf 1;
BA_ "U_C519_MY18_5_Gas_Rx" SG_ 1070 VehVActlEng_D_Qf 1;
BA_ "U_C519_MY18_5_Diesel_Rx" SG_ 1070 VehVActlEng_D_Qf 1;
BA_ "U_B515_MCA_MY17_Gas_Rx" SG_ 1070 VehVActlEng_D_Qf 1;
BA_ "U_B515_MCA_MY17_Diesel_Rx" SG_ 1070 VehVActlEng_D_Qf 1;
BA_ "U_B479_MY17_Diesel_Rx" SG_ 1070 VehVActlEng_D_Qf 1;
BA_ "U_B479_MY17_Gas_Rx" SG_ 1070 VehVActlEng_D_Qf 1;
BA_ "MetaData" SG_ 1070 VehVActlEng_D_Qf 1;
BA_ "CrossOver_InfoCAN" SG_ 1070 VehVActlEng_D_Qf 1;
BA_ "GenSigSendType" SG_ 1070 Veh_V_ActlEng_UB 3;
BA_ "U_B562_MY18_Diesel_Rx" SG_ 1070 Veh_V_ActlEng_UB 1;
BA_ "U_B500_MY18_Diesel_Rx" SG_ 1070 Veh_V_ActlEng_UB 1;
BA_ "U_B500_MY18_Gas_Rx" SG_ 1070 Veh_V_ActlEng_UB 1;
BA_ "U_B562_MY18_Gas_Rx" SG_ 1070 Veh_V_ActlEng_UB 1;
BA_ "U_B562LC_MY15_Diesel_Rx" SG_ 1070 Veh_V_ActlEng_UB 1;
BA_ "U_VN127_MY20_Rx" SG_ 1070 Veh_V_ActlEng_UB 1;
BA_ "U_H567_MY20_Rx" SG_ 1070 Veh_V_ActlEng_UB 1;
BA_ "U_P702_MY2021_Rx" SG_ 1070 Veh_V_ActlEng_UB 1;
BA_ "U_C490_MY18_Rx" SG_ 1070 Veh_V_ActlEng_UB 1;
BA_ "U_CX727_MY2021_Rx" SG_ 1070 Veh_V_ActlEng_UB 1;
BA_ "U_CX430_MY2021_Rx" SG_ 1070 Veh_V_ActlEng_UB 1;
BA_ "U_U611_U625_MY20_Phev_Rx" SG_ 1070 Veh_V_ActlEng_UB 1;
BA_ "U_CX482_CX483_MY20_Rx" SG_ 1070 Veh_V_ActlEng_UB 1;
BA_ "U_U611_U625_MY20_Hev_Rx" SG_ 1070 Veh_V_ActlEng_UB 1;
BA_ "U_U611_U625_MY20_Gas_Rx" SG_ 1070 Veh_V_ActlEng_UB 1;
BA_ "U_C519_MY18_5_Gas_Rx" SG_ 1070 Veh_V_ActlEng_UB 1;
BA_ "U_C519_MY18_5_Diesel_Rx" SG_ 1070 Veh_V_ActlEng_UB 1;
BA_ "U_B515_MCA_MY17_Gas_Rx" SG_ 1070 Veh_V_ActlEng_UB 1;
BA_ "U_B515_MCA_MY17_Diesel_Rx" SG_ 1070 Veh_V_ActlEng_UB 1;
BA_ "U_B479_MY17_Diesel_Rx" SG_ 1070 Veh_V_ActlEng_UB 1;
BA_ "U_B479_MY17_Gas_Rx" SG_ 1070 Veh_V_ActlEng_UB 1;
BA_ "U_B562LC_MY15_Gas_Rx" SG_ 1070 Veh_V_ActlEng_UB 1;
BA_ "GenSigSendType" SG_ 1070 Veh_V_ActlEng 3;
BA_ "U_B562_MY18_Diesel_Rx" SG_ 1070 Veh_V_ActlEng 1;
BA_ "U_B500_MY18_Diesel_Rx" SG_ 1070 Veh_V_ActlEng 1;
BA_ "U_B500_MY18_Gas_Rx" SG_ 1070 Veh_V_ActlEng 1;
BA_ "U_B562_MY18_Gas_Rx" SG_ 1070 Veh_V_ActlEng 1;
BA_ "U_B562LC_MY15_Diesel_Rx" SG_ 1070 Veh_V_ActlEng 1;
BA_ "U_VN127_MY20_Rx" SG_ 1070 Veh_V_ActlEng 1;
BA_ "U_H567_MY20_Rx" SG_ 1070 Veh_V_ActlEng 1;
BA_ "U_P702_MY2021_Rx" SG_ 1070 Veh_V_ActlEng 1;
BA_ "U_C490_MY18_Rx" SG_ 1070 Veh_V_ActlEng 1;
BA_ "U_CX727_MY2021_Rx" SG_ 1070 Veh_V_ActlEng 1;
BA_ "U_CX430_MY2021_Rx" SG_ 1070 Veh_V_ActlEng 1;
BA_ "U_U611_U625_MY20_Phev_Rx" SG_ 1070 Veh_V_ActlEng 1;
BA_ "U_CX482_CX483_MY20_Rx" SG_ 1070 Veh_V_ActlEng 1;
BA_ "U_U611_U625_MY20_Hev_Rx" SG_ 1070 Veh_V_ActlEng 1;
BA_ "U_U611_U625_MY20_Gas_Rx" SG_ 1070 Veh_V_ActlEng 1;
BA_ "U_C519_MY18_5_Gas_Rx" SG_ 1070 Veh_V_ActlEng 1;
BA_ "U_C519_MY18_5_Diesel_Rx" SG_ 1070 Veh_V_ActlEng 1;
BA_ "U_B515_MCA_MY17_Gas_Rx" SG_ 1070 Veh_V_ActlEng 1;
BA_ "U_B515_MCA_MY17_Diesel_Rx" SG_ 1070 Veh_V_ActlEng 1;
BA_ "U_B479_MY17_Diesel_Rx" SG_ 1070 Veh_V_ActlEng 1;
BA_ "U_B479_MY17_Gas_Rx" SG_ 1070 Veh_V_ActlEng 1;
BA_ "U_B562LC_MY15_Gas_Rx" SG_ 1070 Veh_V_ActlEng 1;
BA_ "CrossOver_InfoCAN" SG_ 1070 Veh_V_ActlEng 1;
BA_ "GenSigStartValue" SG_ 1070 PassRstrnInd_Req 3;
BA_ "GenSigStartValueInteger" SG_ 1070 PassRstrnInd_Req 3;
BA_ "CrossOver_InfoCAN" SG_ 1070 PassRstrnInd_Req 1;
BA_ "GenSigSendType" SG_ 1050 CamraRearBttn_D_Stat 3;
BA_ "U_CX727_MY2021_Tx" SG_ 1050 AutoHoldSwtch_D_Stat 1;
BA_ "U_CX430_MY2021_Tx" SG_ 1050 AutoHoldSwtch_D_Stat 1;
BA_ "U_U611_U625_MY20_Phev_Tx" SG_ 1050 AutoHoldSwtch_D_Stat 1;
BA_ "U_CX482_CX483_MY20_Tx" SG_ 1050 AutoHoldSwtch_D_Stat 1;
BA_ "U_U611_U625_MY20_Hev_Tx" SG_ 1050 AutoHoldSwtch_D_Stat 1;
BA_ "U_U611_U625_MY20_Gas_Tx" SG_ 1050 AutoHoldSwtch_D_Stat 1;
BA_ "U_B500_MY18_Diesel_Tx" SG_ 1050 AutoHoldSwtch_D_Stat 1;
BA_ "U_B500_MY18_Gas_Tx" SG_ 1050 AutoHoldSwtch_D_Stat 1;
BA_ "U_C519_MY18_5_Gas_Tx" SG_ 1050 AutoHoldSwtch_D_Stat 1;
BA_ "U_C519_MY18_5_Diesel_Tx" SG_ 1050 AutoHoldSwtch_D_Stat 1;
BA_ "U_B515_MCA_MY17_Gas_Tx" SG_ 1050 AutoHoldSwtch_D_Stat 1;
BA_ "U_B515_MCA_MY17_Diesel_Tx" SG_ 1050 AutoHoldSwtch_D_Stat 1;
BA_ "U_B479_MY17_Diesel_Tx" SG_ 1050 AutoHoldSwtch_D_Stat 1;
BA_ "U_B479_MY17_Gas_Tx" SG_ 1050 AutoHoldSwtch_D_Stat 1;
BA_ "GenSigSendType" SG_ 1050 AutoHoldSwtch_D_Stat 3;
BA_ "U_CX727_MY2021_Tx" SG_ 1050 LpdbPtc3_B_Rq 1;
BA_ "U_CX430_MY2021_Tx" SG_ 1050 LpdbPtc3_B_Rq 1;
BA_ "U_U611_U625_MY20_Phev_Tx" SG_ 1050 LpdbPtc3_B_Rq 1;
BA_ "U_CX482_CX483_MY20_Tx" SG_ 1050 LpdbPtc3_B_Rq 1;
BA_ "U_U611_U625_MY20_Hev_Tx" SG_ 1050 LpdbPtc3_B_Rq 1;
BA_ "U_U611_U625_MY20_Gas_Tx" SG_ 1050 LpdbPtc3_B_Rq 1;
BA_ "U_C519_MY18_5_Gas_Tx" SG_ 1050 LpdbPtc3_B_Rq 1;
BA_ "U_C519_MY18_5_Diesel_Tx" SG_ 1050 LpdbPtc3_B_Rq 1;
BA_ "GenSigSendType" SG_ 1050 LpdbPtc3_B_Rq 3;
BA_ "U_CX727_MY2021_Tx" SG_ 1050 LpdbPtc2_B_Rq 1;
BA_ "U_CX430_MY2021_Tx" SG_ 1050 LpdbPtc2_B_Rq 1;
BA_ "U_U611_U625_MY20_Phev_Tx" SG_ 1050 LpdbPtc2_B_Rq 1;
BA_ "U_CX482_CX483_MY20_Tx" SG_ 1050 LpdbPtc2_B_Rq 1;
BA_ "U_U611_U625_MY20_Hev_Tx" SG_ 1050 LpdbPtc2_B_Rq 1;
BA_ "U_U611_U625_MY20_Gas_Tx" SG_ 1050 LpdbPtc2_B_Rq 1;
BA_ "U_C519_MY18_5_Gas_Tx" SG_ 1050 LpdbPtc2_B_Rq 1;
BA_ "U_C519_MY18_5_Diesel_Tx" SG_ 1050 LpdbPtc2_B_Rq 1;
BA_ "GenSigSendType" SG_ 1050 LpdbPtc2_B_Rq 3;
BA_ "U_CX727_MY2021_Tx" SG_ 1050 LpdbPtc1_B_Rq 1;
BA_ "U_CX430_MY2021_Tx" SG_ 1050 LpdbPtc1_B_Rq 1;
BA_ "U_U611_U625_MY20_Phev_Tx" SG_ 1050 LpdbPtc1_B_Rq 1;
BA_ "U_CX482_CX483_MY20_Tx" SG_ 1050 LpdbPtc1_B_Rq 1;
BA_ "U_U611_U625_MY20_Hev_Tx" SG_ 1050 LpdbPtc1_B_Rq 1;
BA_ "U_U611_U625_MY20_Gas_Tx" SG_ 1050 LpdbPtc1_B_Rq 1;
BA_ "U_C519_MY18_5_Gas_Tx" SG_ 1050 LpdbPtc1_B_Rq 1;
BA_ "U_C519_MY18_5_Diesel_Tx" SG_ 1050 LpdbPtc1_B_Rq 1;
BA_ "GenSigSendType" SG_ 1050 LpdbPtc1_B_Rq 3;
BA_ "U_CX727_MY2021_Tx" SG_ 1050 LpdbHeatWiprPrk_B_Rq 1;
BA_ "U_CX430_MY2021_Tx" SG_ 1050 LpdbHeatWiprPrk_B_Rq 1;
BA_ "U_U611_U625_MY20_Phev_Tx" SG_ 1050 LpdbHeatWiprPrk_B_Rq 1;
BA_ "U_CX482_CX483_MY20_Tx" SG_ 1050 LpdbHeatWiprPrk_B_Rq 1;
BA_ "U_U611_U625_MY20_Hev_Tx" SG_ 1050 LpdbHeatWiprPrk_B_Rq 1;
BA_ "U_U611_U625_MY20_Gas_Tx" SG_ 1050 LpdbHeatWiprPrk_B_Rq 1;
BA_ "U_C519_MY18_5_Gas_Tx" SG_ 1050 LpdbHeatWiprPrk_B_Rq 1;
BA_ "U_C519_MY18_5_Diesel_Tx" SG_ 1050 LpdbHeatWiprPrk_B_Rq 1;
BA_ "GenSigSendType" SG_ 1050 LpdbHeatWiprPrk_B_Rq 3;
BA_ "U_CX727_MY2021_Tx" SG_ 1050 LpdbDfrstRearOn_B_Rq 1;
BA_ "U_CX430_MY2021_Tx" SG_ 1050 LpdbDfrstRearOn_B_Rq 1;
BA_ "U_U611_U625_MY20_Phev_Tx" SG_ 1050 LpdbDfrstRearOn_B_Rq 1;
BA_ "U_CX482_CX483_MY20_Tx" SG_ 1050 LpdbDfrstRearOn_B_Rq 1;
BA_ "U_U611_U625_MY20_Hev_Tx" SG_ 1050 LpdbDfrstRearOn_B_Rq 1;
BA_ "U_U611_U625_MY20_Gas_Tx" SG_ 1050 LpdbDfrstRearOn_B_Rq 1;
BA_ "U_C519_MY18_5_Gas_Tx" SG_ 1050 LpdbDfrstRearOn_B_Rq 1;
BA_ "U_C519_MY18_5_Diesel_Tx" SG_ 1050 LpdbDfrstRearOn_B_Rq 1;
BA_ "GenSigSendType" SG_ 1050 LpdbDfrstRearOn_B_Rq 3;
BA_ "U_CX727_MY2021_Tx" SG_ 1050 LpdbDfrstFrOn_B_Rq 1;
BA_ "U_CX430_MY2021_Tx" SG_ 1050 LpdbDfrstFrOn_B_Rq 1;
BA_ "U_U611_U625_MY20_Phev_Tx" SG_ 1050 LpdbDfrstFrOn_B_Rq 1;
BA_ "U_CX482_CX483_MY20_Tx" SG_ 1050 LpdbDfrstFrOn_B_Rq 1;
BA_ "U_U611_U625_MY20_Hev_Tx" SG_ 1050 LpdbDfrstFrOn_B_Rq 1;
BA_ "U_U611_U625_MY20_Gas_Tx" SG_ 1050 LpdbDfrstFrOn_B_Rq 1;
BA_ "U_C519_MY18_5_Gas_Tx" SG_ 1050 LpdbDfrstFrOn_B_Rq 1;
BA_ "U_C519_MY18_5_Diesel_Tx" SG_ 1050 LpdbDfrstFrOn_B_Rq 1;
BA_ "GenSigSendType" SG_ 1050 LpdbDfrstFrOn_B_Rq 3;
BA_ "U_CX727_MY2021_Tx" SG_ 1050 LpdbDfrstFlOn_B_Rq 1;
BA_ "U_CX430_MY2021_Tx" SG_ 1050 LpdbDfrstFlOn_B_Rq 1;
BA_ "U_U611_U625_MY20_Phev_Tx" SG_ 1050 LpdbDfrstFlOn_B_Rq 1;
BA_ "U_CX482_CX483_MY20_Tx" SG_ 1050 LpdbDfrstFlOn_B_Rq 1;
BA_ "U_U611_U625_MY20_Hev_Tx" SG_ 1050 LpdbDfrstFlOn_B_Rq 1;
BA_ "U_U611_U625_MY20_Gas_Tx" SG_ 1050 LpdbDfrstFlOn_B_Rq 1;
BA_ "U_C519_MY18_5_Gas_Tx" SG_ 1050 LpdbDfrstFlOn_B_Rq 1;
BA_ "U_C519_MY18_5_Diesel_Tx" SG_ 1050 LpdbDfrstFlOn_B_Rq 1;
BA_ "GenSigSendType" SG_ 1050 LpdbDfrstFlOn_B_Rq 3;
BA_ "U_P702_MY2021_Tx" SG_ 1050 SteWhlHeat_D_Rq 1;
BA_ "U_CX727_MY2021_Tx" SG_ 1050 SteWhlHeat_D_Rq 1;
BA_ "U_CX430_MY2021_Tx" SG_ 1050 SteWhlHeat_D_Rq 1;
BA_ "U_U611_U625_MY20_Phev_Tx" SG_ 1050 SteWhlHeat_D_Rq 1;
BA_ "U_CX482_CX483_MY20_Tx" SG_ 1050 SteWhlHeat_D_Rq 1;
BA_ "U_U611_U625_MY20_Hev_Tx" SG_ 1050 SteWhlHeat_D_Rq 1;
BA_ "U_U611_U625_MY20_Gas_Tx" SG_ 1050 SteWhlHeat_D_Rq 1;
BA_ "U_B500_MY18_Diesel_Tx" SG_ 1050 SteWhlHeat_D_Rq 1;
BA_ "U_B500_MY18_Gas_Tx" SG_ 1050 SteWhlHeat_D_Rq 1;
BA_ "U_C519_MY18_5_Gas_Tx" SG_ 1050 SteWhlHeat_D_Rq 1;
BA_ "U_C519_MY18_5_Diesel_Tx" SG_ 1050 SteWhlHeat_D_Rq 1;
BA_ "U_B515_MCA_MY17_Gas_Tx" SG_ 1050 SteWhlHeat_D_Rq 1;
BA_ "U_B515_MCA_MY17_Diesel_Tx" SG_ 1050 SteWhlHeat_D_Rq 1;
BA_ "U_B479_MY17_Diesel_Tx" SG_ 1050 SteWhlHeat_D_Rq 1;
BA_ "U_B479_MY17_Gas_Tx" SG_ 1050 SteWhlHeat_D_Rq 1;
BA_ "GenSigSendType" SG_ 1050 SteWhlHeat_D_Rq 3;
BA_ "U_P702_MY2021_Tx" SG_ 1050 MirrorHeatOn_B_Rq 1;
BA_ "U_CX727_MY2021_Tx" SG_ 1050 MirrorHeatOn_B_Rq 1;
BA_ "U_CX430_MY2021_Tx" SG_ 1050 MirrorHeatOn_B_Rq 1;
BA_ "U_U611_U625_MY20_Phev_Tx" SG_ 1050 MirrorHeatOn_B_Rq 1;
BA_ "U_CX482_CX483_MY20_Tx" SG_ 1050 MirrorHeatOn_B_Rq 1;
BA_ "U_U611_U625_MY20_Hev_Tx" SG_ 1050 MirrorHeatOn_B_Rq 1;
BA_ "U_U611_U625_MY20_Gas_Tx" SG_ 1050 MirrorHeatOn_B_Rq 1;
BA_ "U_B500_MY18_Diesel_Tx" SG_ 1050 MirrorHeatOn_B_Rq 1;
BA_ "U_B500_MY18_Gas_Tx" SG_ 1050 MirrorHeatOn_B_Rq 1;
BA_ "U_C519_MY18_5_Gas_Tx" SG_ 1050 MirrorHeatOn_B_Rq 1;
BA_ "U_C519_MY18_5_Diesel_Tx" SG_ 1050 MirrorHeatOn_B_Rq 1;
BA_ "U_B515_MCA_MY17_Gas_Tx" SG_ 1050 MirrorHeatOn_B_Rq 1;
BA_ "U_B515_MCA_MY17_Diesel_Tx" SG_ 1050 MirrorHeatOn_B_Rq 1;
BA_ "U_B479_MY17_Diesel_Tx" SG_ 1050 MirrorHeatOn_B_Rq 1;
BA_ "U_B479_MY17_Gas_Tx" SG_ 1050 MirrorHeatOn_B_Rq 1;
BA_ "U_CX727_MY2021_Rx" SG_ 1050 MirrorHeatOn_B_Rq 1;
BA_ "U_P702_MY2021_Rx" SG_ 1050 MirrorHeatOn_B_Rq 1;
BA_ "U_CX430_MY2021_Rx" SG_ 1050 MirrorHeatOn_B_Rq 1;
BA_ "U_U611_U625_MY20_Phev_Rx" SG_ 1050 MirrorHeatOn_B_Rq 1;
BA_ "U_CX482_CX483_MY20_Rx" SG_ 1050 MirrorHeatOn_B_Rq 1;
BA_ "U_U611_U625_MY20_Hev_Rx" SG_ 1050 MirrorHeatOn_B_Rq 1;
BA_ "U_U611_U625_MY20_Gas_Rx" SG_ 1050 MirrorHeatOn_B_Rq 1;
BA_ "U_C490_MY18_Rx" SG_ 1050 MirrorHeatOn_B_Rq 1;
BA_ "U_C519_MY18_5_Gas_Rx" SG_ 1050 MirrorHeatOn_B_Rq 1;
BA_ "U_C519_MY18_5_Diesel_Rx" SG_ 1050 MirrorHeatOn_B_Rq 1;
BA_ "U_B515_MCA_MY17_Gas_Rx" SG_ 1050 MirrorHeatOn_B_Rq 1;
BA_ "U_B515_MCA_MY17_Diesel_Rx" SG_ 1050 MirrorHeatOn_B_Rq 1;
BA_ "U_B479_MY17_Diesel_Rx" SG_ 1050 MirrorHeatOn_B_Rq 1;
BA_ "U_B479_MY17_Gas_Rx" SG_ 1050 MirrorHeatOn_B_Rq 1;
BA_ "GenSigSendType" SG_ 1050 MirrorHeatOn_B_Rq 3;
BA_ "U_P702_MY2021_Tx" SG_ 1050 Outside_Air_Temp_Stat 1;
BA_ "U_CX727_MY2021_Tx" SG_ 1050 Outside_Air_Temp_Stat 1;
BA_ "U_H567_MY20_Tx" SG_ 1050 Outside_Air_Temp_Stat 1;
BA_ "U_CX430_MY2021_Tx" SG_ 1050 Outside_Air_Temp_Stat 1;
BA_ "U_U611_U625_MY20_Phev_Tx" SG_ 1050 Outside_Air_Temp_Stat 1;
BA_ "U_B562_MY18_Diesel_Tx" SG_ 1050 Outside_Air_Temp_Stat 1;
BA_ "U_CX482_CX483_MY20_Tx" SG_ 1050 Outside_Air_Temp_Stat 1;
BA_ "U_U611_U625_MY20_Hev_Tx" SG_ 1050 Outside_Air_Temp_Stat 1;
BA_ "U_U611_U625_MY20_Gas_Tx" SG_ 1050 Outside_Air_Temp_Stat 1;
BA_ "U_B500_MY18_Diesel_Tx" SG_ 1050 Outside_Air_Temp_Stat 1;
BA_ "U_B500_MY18_Gas_Tx" SG_ 1050 Outside_Air_Temp_Stat 1;
BA_ "U_C490_MY18_Tx" SG_ 1050 Outside_Air_Temp_Stat 1;
BA_ "U_B562_MY18_Gas_Tx" SG_ 1050 Outside_Air_Temp_Stat 1;
BA_ "U_C519_MY18_5_Gas_Tx" SG_ 1050 Outside_Air_Temp_Stat 1;
BA_ "U_C519_MY18_5_Diesel_Tx" SG_ 1050 Outside_Air_Temp_Stat 1;
BA_ "U_B515_MCA_MY17_Gas_Tx" SG_ 1050 Outside_Air_Temp_Stat 1;
BA_ "U_B515_MCA_MY17_Diesel_Tx" SG_ 1050 Outside_Air_Temp_Stat 1;
BA_ "U_B479_MY17_Diesel_Tx" SG_ 1050 Outside_Air_Temp_Stat 1;
BA_ "U_B479_MY17_Gas_Tx" SG_ 1050 Outside_Air_Temp_Stat 1;
BA_ "U_CX727_MY2021_Rx" SG_ 1050 Outside_Air_Temp_Stat 1;
BA_ "U_P702_MY2021_Rx" SG_ 1050 Outside_Air_Temp_Stat 1;
BA_ "U_CX430_MY2021_Rx" SG_ 1050 Outside_Air_Temp_Stat 1;
BA_ "U_U611_U625_MY20_Phev_Rx" SG_ 1050 Outside_Air_Temp_Stat 1;
BA_ "U_U611_U625_MY20_Hev_Rx" SG_ 1050 Outside_Air_Temp_Stat 1;
BA_ "U_U611_U625_MY20_Gas_Rx" SG_ 1050 Outside_Air_Temp_Stat 1;
BA_ "U_C490_MY18_Rx" SG_ 1050 Outside_Air_Temp_Stat 1;
BA_ "U_B515_MCA_MY17_Gas_Rx" SG_ 1050 Outside_Air_Temp_Stat 1;
BA_ "U_B515_MCA_MY17_Diesel_Rx" SG_ 1050 Outside_Air_Temp_Stat 1;
BA_ "U_B479_MY17_Diesel_Rx" SG_ 1050 Outside_Air_Temp_Stat 1;
BA_ "U_B479_MY17_Gas_Rx" SG_ 1050 Outside_Air_Temp_Stat 1;
BA_ "U_CX482_CX483_MY20_Rx" SG_ 1050 Outside_Air_Temp_Stat 1;
BA_ "U_C519_MY18_5_Gas_Rx" SG_ 1050 Outside_Air_Temp_Stat 1;
BA_ "U_C519_MY18_5_Diesel_Rx" SG_ 1050 Outside_Air_Temp_Stat 1;
BA_ "GenSigSendType" SG_ 1050 Outside_Air_Temp_Stat 3;
BA_ "GenSigStartValue" SG_ 1050 Outside_Air_Temp_Stat 254;
BA_ "GenSigStartValueInteger" SG_ 1050 Outside_Air_Temp_Stat 254;
BA_ "CrossOver_InfoCAN" SG_ 1050 Outside_Air_Temp_Stat 1;
BA_ "U_P702_MY2021_Tx" SG_ 1050 Remote_Start_QuietMode 1;
BA_ "U_CX727_MY2021_Tx" SG_ 1050 Remote_Start_QuietMode 1;
BA_ "U_CX430_MY2021_Tx" SG_ 1050 Remote_Start_QuietMode 1;
BA_ "U_U611_U625_MY20_Phev_Tx" SG_ 1050 Remote_Start_QuietMode 1;
BA_ "U_CX482_CX483_MY20_Tx" SG_ 1050 Remote_Start_QuietMode 1;
BA_ "U_U611_U625_MY20_Hev_Tx" SG_ 1050 Remote_Start_QuietMode 1;
BA_ "U_U611_U625_MY20_Gas_Tx" SG_ 1050 Remote_Start_QuietMode 1;
BA_ "U_B500_MY18_Diesel_Tx" SG_ 1050 Remote_Start_QuietMode 1;
BA_ "U_B500_MY18_Gas_Tx" SG_ 1050 Remote_Start_QuietMode 1;
BA_ "U_C519_MY18_5_Gas_Tx" SG_ 1050 Remote_Start_QuietMode 1;
BA_ "U_C519_MY18_5_Diesel_Tx" SG_ 1050 Remote_Start_QuietMode 1;
BA_ "U_B515_MCA_MY17_Gas_Tx" SG_ 1050 Remote_Start_QuietMode 1;
BA_ "U_B515_MCA_MY17_Diesel_Tx" SG_ 1050 Remote_Start_QuietMode 1;
BA_ "U_B479_MY17_Diesel_Tx" SG_ 1050 Remote_Start_QuietMode 1;
BA_ "U_B479_MY17_Gas_Tx" SG_ 1050 Remote_Start_QuietMode 1;
BA_ "GenSigSendType" SG_ 1050 Remote_Start_QuietMode 3;
BA_ "U_P702_MY2021_Rx" SG_ 1856 TesterPhysicalReqDDM 1;
BA_ "U_CX727_MY2021_Rx" SG_ 1856 TesterPhysicalReqDDM 1;
BA_ "U_CX430_MY2021_Rx" SG_ 1856 TesterPhysicalReqDDM 1;
BA_ "U_U611_U625_MY20_Phev_Rx" SG_ 1856 TesterPhysicalReqDDM 1;
BA_ "U_CX482_CX483_MY20_Rx" SG_ 1856 TesterPhysicalReqDDM 1;
BA_ "U_U611_U625_MY20_Hev_Rx" SG_ 1856 TesterPhysicalReqDDM 1;
BA_ "U_U611_U625_MY20_Gas_Rx" SG_ 1856 TesterPhysicalReqDDM 1;
BA_ "U_C490_MY18_Rx" SG_ 1856 TesterPhysicalReqDDM 1;
BA_ "U_C519_MY18_5_Gas_Rx" SG_ 1856 TesterPhysicalReqDDM 1;
BA_ "U_C519_MY18_5_Diesel_Rx" SG_ 1856 TesterPhysicalReqDDM 1;
BA_ "U_B515_MCA_MY17_Gas_Rx" SG_ 1856 TesterPhysicalReqDDM 1;
BA_ "U_B515_MCA_MY17_Diesel_Rx" SG_ 1856 TesterPhysicalReqDDM 1;
BA_ "U_B479_MY17_Diesel_Rx" SG_ 1856 TesterPhysicalReqDDM 1;
BA_ "U_B479_MY17_Gas_Rx" SG_ 1856 TesterPhysicalReqDDM 1;
BA_ "GenSigSendType" SG_ 1856 TesterPhysicalReqDDM 3;
BA_ "U_P702_MY2021_Tx" SG_ 1864 TesterPhysicalResDDM 1;
BA_ "U_CX727_MY2021_Tx" SG_ 1864 TesterPhysicalResDDM 1;
BA_ "U_CX430_MY2021_Tx" SG_ 1864 TesterPhysicalResDDM 1;
BA_ "U_U611_U625_MY20_Phev_Tx" SG_ 1864 TesterPhysicalResDDM 1;
BA_ "U_CX482_CX483_MY20_Tx" SG_ 1864 TesterPhysicalResDDM 1;
BA_ "U_U611_U625_MY20_Hev_Tx" SG_ 1864 TesterPhysicalResDDM 1;
BA_ "U_U611_U625_MY20_Gas_Tx" SG_ 1864 TesterPhysicalResDDM 1;
BA_ "U_C490_MY18_Tx" SG_ 1864 TesterPhysicalResDDM 1;
BA_ "U_C519_MY18_5_Gas_Tx" SG_ 1864 TesterPhysicalResDDM 1;
BA_ "U_C519_MY18_5_Diesel_Tx" SG_ 1864 TesterPhysicalResDDM 1;
BA_ "U_B515_MCA_MY17_Gas_Tx" SG_ 1864 TesterPhysicalResDDM 1;
BA_ "U_B515_MCA_MY17_Diesel_Tx" SG_ 1864 TesterPhysicalResDDM 1;
BA_ "U_B479_MY17_Diesel_Tx" SG_ 1864 TesterPhysicalResDDM 1;
BA_ "U_B479_MY17_Gas_Tx" SG_ 1864 TesterPhysicalResDDM 1;
BA_ "GenSigSendType" SG_ 1864 TesterPhysicalResDDM 3;
BA_ "U_P702_MY2021_Rx" SG_ 1937 TesterPhysicalReqTRM 1;
BA_ "U_CX430_MY2021_Rx" SG_ 1937 TesterPhysicalReqTRM 1;
BA_ "U_U611_U625_MY20_Phev_Rx" SG_ 1937 TesterPhysicalReqTRM 1;
BA_ "U_CX482_CX483_MY20_Rx" SG_ 1937 TesterPhysicalReqTRM 1;
BA_ "U_U611_U625_MY20_Gas_Rx" SG_ 1937 TesterPhysicalReqTRM 1;
BA_ "U_C519_MY18_5_Gas_Rx" SG_ 1937 TesterPhysicalReqTRM 1;
BA_ "U_C519_MY18_5_Diesel_Rx" SG_ 1937 TesterPhysicalReqTRM 1;
BA_ "U_B515_MCA_MY17_Gas_Rx" SG_ 1937 TesterPhysicalReqTRM 1;
BA_ "U_B515_MCA_MY17_Diesel_Rx" SG_ 1937 TesterPhysicalReqTRM 1;
BA_ "U_B479_MY17_Diesel_Rx" SG_ 1937 TesterPhysicalReqTRM 1;
BA_ "U_B479_MY17_Gas_Rx" SG_ 1937 TesterPhysicalReqTRM 1;
BA_ "GenSigSendType" SG_ 1937 TesterPhysicalReqTRM 3;
VAL_ 806 ClimtDeltaLoad_Pw_Actl 63 "Faulty" 62 "NoDataExists" ;
VAL_ 806 StopStrtDrvMde_B_RqBtn 1 "Pressed" 0 "Not_Pressed" ;
VAL_ 806 WndwFrontHeat_B_Stat 1 "On" 0 "Off" ;
VAL_ 806 ClimtHeat_D_Rq 7 "NotUsed4" 6 "NotUsed3" 5 "NotUsed2" 4 "PtcHtrTestMde" 3 "Defrost_Defog" 2 "FastTempPullDownHeatingReq" 1 "OpportunisticHeatingReq" 0 "NoHeatingRequest" ;
VAL_ 806 ClimtCool_D_Rq 7 "NotUsed4" 6 "NotUsed3" 5 "NotUsed2" 4 "ElACTestMde" 3 "Defrost_Defog" 2 "FastTempPullDownCoolReq" 1 "OpportunisticCoolingReq" 0 "NoCoolingRequest" ;
VAL_ 806 HvacEvap_Te_Actl 1023 "Fault" ;
VAL_ 806 HvacAirCond_B_Rq 1 "Yes" 0 "No" ;
VAL_ 806 ClimtPw_B_Rq 1 "Yes" 0 "No" ;
VAL_ 950 Modulation_Ctrl 3 "Unused" 2 "FSK" 1 "ASK_FSK" 0 "ASK" ;
VAL_ 950 TirePress_Filter_Ctrl 3 "Streaming" 2 "Filter" 1 "Not_Used" 0 "Null" ;
VAL_ 857 LHS_Temp_Disp_Digit3 2 "_5" 1 "_0" 0 "OFF" ;
VAL_ 857 Front_Blower_Ind 15 "Display_Blank" 14 "14_Indicators_On" 13 "13_Indicators_On" 12 "12_Indicators_On" 11 "11_Indicators_On" 10 "10_Indicators_On" 9 "9_Indicators_On" 8 "8_Indicators_On" 7 "7_Indicators_On" 6 "6_Indicators_On" 5 "5_Indicators_On" 4 "4_Indicators_On" 3 "3_Indicators_On" 2 "2_Indicators_On" 1 "1_Indicator_On" 0 "Indicators_Off" ;
VAL_ 857 EATC_LHS_Unit 2 "Fahrenheit" 1 "Celsius" 0 "Off" ;
VAL_ 856 ClimtRearView_D_Stat 3 "ThirdRow" 2 "SecondRow" 1 "Both" 0 "NotDisplayed" ;
VAL_ 856 Rr_Btn_Status_2nd 31 "NotUsed_7" 30 "NotUsed_6" 29 "NotUsed_5" 28 "NotUsed_4" 27 "NotUsed_3" 26 "NotUsed_2" 25 "NotUsed_1" 24 "Third_Sync_Pressed" 23 "Third_Rr_Pwr_Pressed" 22 "Third_Auto_Pressed" 21 "Third_Pnl_Flr_Pressed" 20 "Third_Floor_Pressed" 19 "Third_Panel_Pressed" 18 "Third_Blwr_Dec_Pressed" 17 "Third_Blwr_Inc_Pressed" 16 "Rear_Lock_Pressed" 15 "RHS_Cld_Seat_Pressed" 14 "LHS_Cld_Seat_Pressed" 13 "RHS_Htd_Seat_Pressed" 12 "LHS_Htd_Seat_Pressed" 11 "Rear_Power_Pressed" 10 "AUTO_Pressed" 9 "Blwr_Dec_Pressed" 8 "Blwr_Inc_Pressed" 7 "RHS_Temp_Dec_Pressed" 6 "RHS_Temp_Inc_Pressed" 5 "LHS_Temp_Dec_Pressed" 4 "LHS_Temp_Inc_Pressed" 3 "Floor_Pressed" 2 "Panel_Floor_Pressed" 1 "Panel_Pressed" 0 "None_Pressed" ;
VAL_ 856 Rr_Btn_Status_1st 31 "NotUsed_7" 30 "NotUsed_6" 29 "NotUsed_5" 28 "NotUsed_4" 27 "NotUsed_3" 26 "NotUsed_2" 25 "NotUsed_1" 24 "Third_Sync_Pressed" 23 "Third_Rr_Pwr_Pressed" 22 "Third_Auto_Pressed" 21 "Third_Pnl_Flr_Pressed" 20 "Third_Floor_Pressed" 19 "Third_Panel_Pressed" 18 "Third_Blwr_Dec_Pressed" 17 "Third_Blwr_Inc_Pressed" 16 "Rear_Lock_Pressed" 15 "RHS_Cld_Seat_Pressed" 14 "LHS_Cld_Seat_Pressed" 13 "RHS_Htd_Seat_Pressed" 12 "LHS_Htd_Seat_Pressed" 11 "Rear_Power_Pressed" 10 "AUTO_Pressed" 9 "Blwr_Dec_Pressed" 8 "Blwr_Inc_Pressed" 7 "RHS_Temp_Dec_Pressed" 6 "RHS_Temp_Inc_Pressed" 5 "LHS_Temp_Dec_Pressed" 4 "LHS_Temp_Inc_Pressed" 3 "Floor_Pressed" 2 "Panel_Floor_Pressed" 1 "Panel_Pressed" 0 "None_Pressed" ;
VAL_ 856 Frt_Btn_Status_2nd 36 "MdeMnu_Pressed" 35 "AAR_Pressed" 34 "Heat_Pressed" 33 "RearMnu_Pressed" 32 "FrontMnu_Pressed" 31 "Defrost_Pressed" 30 "Htg_Strg_Whl_Pressed" 29 "RHS_Cld_Seat_Pressed" 28 "LHS_Cld_Seat_Pressed" 27 "RHS_Htd_Seat_Pressed" 26 "LHS_Htd_Seat_Pressed" 25 "Max_Defrost_Pressed" 24 "My_Temp_Pressed" 23 "Front_Power_Pressed" 22 "Rear_Defrost_Pressed" 21 "Pnl_Flr_Ws_Pressed" 20 "Pnl_Ws_Pressed" 19 "Windscreen_Pressed" 18 "Htd_Frt_Wsh_Pressed" 17 "Auto_Recirc_Pressed" 16 "Outside_Pressed" 15 "Recirc_Pressed" 14 "Max_AC_Pressed" 13 "AUTO_Pressed" 12 "Blwr_Dec_Pressed" 11 "Blwr_Inc_Pressed" 10 "RHS_Temp_Dec_Pressed" 9 "RHS_Temp_Inc_Pressed" 8 "LHS_Temp_Dec_Pressed" 7 "LHS_Temp_Inc_Pressed" 6 "Dual_Pressed" 5 "AC_Pressed" 4 "Floor_Ws_Pressed" 3 "Floor_Pressed" 2 "Panel_Floor_Pressed" 1 "Panel_Pressed" 0 "None_Pressed" ;
VAL_ 856 Frt_Btn_Status_1st 36 "MdeMnu_Pressed" 35 "AAR_Pressed" 34 "Heat_Pressed" 33 "RearMnu_Pressed" 32 "FrontMnu_Pressed" 31 "Defrost_Pressed" 30 "Htg_Strg_Whl_Pressed" 29 "RHS_Cld_Seat_Pressed" 28 "LHS_Cld_Seat_Pressed" 27 "RHS_Htd_Seat_Pressed" 26 "LHS_Htd_Seat_Pressed" 25 "Max_Defrost_Pressed" 24 "My_Temp_Pressed" 23 "Front_Power_Pressed" 22 "Rear_Defrost_Pressed" 21 "Pnl_Flr_Ws_Pressed" 20 "Pnl_Ws_Pressed" 19 "Windscreen_Pressed" 18 "Htd_Frt_Wsh_Pressed" 17 "Auto_Recirc_Pressed" 16 "Outside_Pressed" 15 "Recirc_Pressed" 14 "Max_AC_Pressed" 13 "AUTO_Pressed" 12 "Blwr_Dec_Pressed" 11 "Blwr_Inc_Pressed" 10 "RHS_Temp_Dec_Pressed" 9 "RHS_Temp_Inc_Pressed" 8 "LHS_Temp_Dec_Pressed" 7 "LHS_Temp_Inc_Pressed" 6 "Dual_Pressed" 5 "AC_Pressed" 4 "Floor_Ws_Pressed" 3 "Floor_Pressed" 2 "Panel_Floor_Pressed" 1 "Panel_Pressed" 0 "None_Pressed" ;
VAL_ 856 Frt_Blower_Speed 3 "NotUsed" 2 "Max_Blower" 1 "Min_Blower" 0 "No_Request" ;
VAL_ 856 Drv_Set_Temp 31 "HI" 30 "29_5" 29 "29_0" 28 "28_5" 27 "28_0" 26 "27_5" 25 "27_0" 24 "26_5" 23 "26_0" 22 "25_5" 21 "25_0" 20 "24_5" 19 "24_0" 18 "23_5" 17 "23_0" 16 "22_5" 15 "22_0" 14 "21_5" 13 "21_0" 12 "20_5" 11 "20_0" 10 "19_5" 9 "19_0" 8 "18_5" 7 "18_0" 6 "17_5" 5 "17_0" 4 "16_5" 3 "16_0" 2 "15_5" 1 "LO" 0 "No_Request" ;
VAL_ 854 SelDrvMdeSwtch_D_Stat2 3 "Faulty" 2 "SwitchState2" 1 "SwitchState1" 0 "NotPressed" ;
VAL_ 854 CC_Fr_Stat_User_Adj 7 "Unused4" 6 "Unused3" 5 "Unused2" 4 "Unused1" 3 "Fr_Blwr_Spd_Selection" 2 "FRHS_SetPt_Selection" 1 "FLHS_SetPt_Selection" 0 "None" ;
VAL_ 854 Front_Blower_Indicate 15 "Display_Blank" 14 "14_Indicators_On" 13 "13_Indicators_On" 12 "12_Indicators_On" 11 "11_Indicators_On" 10 "10_Indicators_On" 9 "9_Indicators_On" 8 "8_Indicators_On" 7 "7_Indicators_On" 6 "6_Indicators_On" 5 "5_Indicators_On" 4 "4_Indicators_On" 3 "3_Indicators_On" 2 "2_Indicators_On" 1 "1_Indicator_On" 0 "Indicators_Off" ;
VAL_ 854 CC_Diagnostics_Active 1 "Yes" 0 "No" ;
VAL_ 854 RHS_Temp_Display_Digit3 2 "_5" 1 "_0" 0 "OFF" ;
VAL_ 854 LHS_Temp_Display_Digit3 2 "_5" 1 "_0" 0 "OFF" ;
VAL_ 854 EATC_RHS_Units 2 "Fahrenheit" 1 "Celsius" 0 "Off" ;
VAL_ 854 EATC_LHS_Units 2 "Fahrenheit" 1 "Celsius" 0 "Off" ;
VAL_ 534 WhlDirRr_D_Actl 3 "Failed" 2 "Unknown" 1 "Backward" 0 "Forward" ;
VAL_ 534 WhlDirRl_D_Actl 3 "Failed" 2 "Unknown" 1 "Backward" 0 "Forward" ;
VAL_ 534 WhlDirFr_D_Actl 3 "Failed" 2 "Unknown" 1 "Backward" 0 "Forward" ;
VAL_ 534 WhlDirFl_D_Actl 3 "Failed" 2 "Unknown" 1 "Backward" 0 "Forward" ;
VAL_ 772 SeatScrnDrvOn_B_Rq 1 "On" 0 "Off" ;
VAL_ 772 SeatPos_D_Stat 7 "NotUsed3" 6 "NotUsed2" 5 "Error" 4 "Drive" 3 "Moving" 2 "Pending" 1 "EasyEntry" 0 "Null" ;
VAL_ 772 MemDrvDeny_B_Stat 1 "Yes" 0 "No" ;
VAL_ 772 Memory_Feedback_Rqst 1 "Yes" 0 "No" ;
VAL_ 772 Easy_Entry_Rqst 2 "Easy_Entry" 1 "Drive" 0 "Null" ;
VAL_ 772 Memory_Cmd 7 "Recall_3" 4 "Store_4" 3 "Store_3" 6 "Recall_2" 5 "Recall_1" 2 "Store_2" 1 "Store_1" 0 "Null" 8 "Recall_4" ;
VAL_ 772 Cancel_Auto_Movement 1 "Cancel" 0 "Null" ;
VAL_ 935 LcwaRight_D_Stat 7 "Faulty" 6 "NotUsed_3" 5 "NotUsed_2" 4 "NotUsed_1" 3 "Disabled" 2 "TemporaryUnavailable" 1 "SensorBlocked" 0 "Available" ;
VAL_ 935 LcwaDetctRight2_B_Stat 1 "Yes" 0 "No" ;
VAL_ 935 LcwaDetctRight1_B_Stat 1 "Yes" 0 "No" ;
VAL_ 935 RbaCtaRight_D_Stat 7 "Faulty" 6 "NotUsed_2" 5 "NotUsed_1" 4 "Invalid" 3 "Disabled" 2 "On" 1 "Trailer_Tow_Off" 0 "Off" ;
VAL_ 935 BttRight_D_Stat 7 "NotUsed" 6 "Disabled" 5 "Off" 4 "OffTemp" 3 "NotConnected" 2 "Pending" 1 "Connected" 0 "NotDetermined" ;
VAL_ 935 BttRight_D_RqDrv 3 "NotUsed" 2 "Request" 1 "NoRequest" 0 "Null" ;
VAL_ 935 CtaAlrtRight2_D_Stat 7 "NotUsed3" 6 "NotUsed2" 5 "NotUsed1" 4 "AlertZone4" 3 "AlertZone3" 2 "AlertZone2" 1 "AlertZone1" 0 "Off" ;
VAL_ 935 CtaRightBrkEnbl_B_Rq 1 "Enable" 0 "Disable" ;
VAL_ 935 CtaRightBrkDecel_B_Rq 1 "Enable" 0 "Disable" ;
VAL_ 935 CtaSnsRight_D_Stat 3 "Invalid" 2 "System_Failure" 1 "Blocked" 0 "Clear" ;
VAL_ 935 CtaAlrtRight_D_Stat 1 "On" 0 "Off" ;
VAL_ 935 CtaRight_D_Stat 7 "NotUsed_3" 6 "NotUsed_2" 5 "NotUsed_1" 4 "Invalid" 3 "Disabled" 2 "On" 1 "Trailer_Tow_Off" 0 "Off" ;
VAL_ 935 SodRight_D_Stat 7 "NotUsed_3" 6 "NotUsed_2" 5 "NotUsed_1" 4 "Invalid" 3 "Disabled" 2 "On" 1 "Trailer_Tow_Off" 0 "Off" ;
VAL_ 935 SodSnsRight_D_Stat 3 "Second_Warning_Audio" 2 "System_Failure" 1 "Blocked" 0 "Clear" ;
VAL_ 935 SodAlrtRight_D_Stat 3 "Bulb_Proveout" 2 "Flash" 1 "On" 0 "Off" ;
VAL_ 935 SodDetctRight_D_Stat 4 "Sensor_Blocked" 3 "Sensor_Fault" 2 "Flash_On" 1 "Alert_On" 0 "AlertOff_FlashOff_SensrClr" ;
VAL_ 935 SodInnrRight_D_Stat 3 "Reporting" 2 "Not_Reporting" 1 "System_Standby" 0 "Initialization" ;
VAL_ 935 CtaInnrRight_D_Stat 3 "Reporting" 2 "Not_Reporting" 1 "System_Standby" 0 "Initialization" ;
VAL_ 934 RbaCtaLeft_D_Stat 7 "Faulty" 6 "NotUsed_2" 5 "NotUsed_1" 4 "Invalid" 3 "Disabled" 2 "On" 1 "Trailer_Tow_Off" 0 "Off" ;
VAL_ 934 LcwaLeft_D_Stat 7 "Faulty" 6 "NotUsed_3" 5 "NotUsed_2" 4 "NotUsed_1" 3 "Disabled" 2 "TemporaryUnavailable" 1 "SensorBlocked" 0 "Available" ;
VAL_ 934 LcwaDetctLeft2_B_Stat 1 "Yes" 0 "No" ;
VAL_ 934 LcwaDetctLeft1_B_Stat 1 "Yes" 0 "No" ;
VAL_ 934 BttLeft_D_Stat 7 "NotUsed" 6 "Disabled" 5 "Off" 4 "OffTemp" 3 "NotConnected" 2 "Pending" 1 "Connected" 0 "NotDetermined" ;
VAL_ 934 BttLeft_D_RqDrv 3 "NotUsed" 2 "Request" 1 "NoRequest" 0 "Null" ;
VAL_ 934 CtaAlrtLeft2_D_Stat 7 "NotUsed3" 6 "NotUsed2" 5 "NotUsed1" 4 "AlertZone4" 3 "AlertZone3" 2 "AlertZone2" 1 "AlertZone1" 0 "Off" ;
VAL_ 934 CtaLeftBrkDecel_B_Rq 1 "Enable" 0 "Disable" ;
VAL_ 934 CtaLeftBrkEnbl_B_Rq 1 "Enable" 0 "Disable" ;
VAL_ 934 CtaInnrLeft_D_Stat 3 "Reporting" 2 "Not_Reporting" 1 "System_Standby" 0 "Initialization" ;
VAL_ 934 CtaSnsLeft_D_Stat 3 "Invalid" 2 "System_Failure" 1 "Blocked" 0 "Clear" ;
VAL_ 934 SodDetctLeft_D_Stat 4 "Sensor_Blocked" 3 "Sensor_Fault" 2 "Flash_On" 1 "Alert_On" 0 "AlertOff_FlashOff_SensrClr" ;
VAL_ 934 CtaLeft_D_Stat 7 "NotUsed_3" 6 "NotUsed_2" 5 "NotUsed_1" 4 "Invalid" 3 "Disabled" 2 "On" 1 "Trailer_Tow_Off" 0 "Off" ;
VAL_ 934 CtaAlrtLeft_D_Stat 1 "On" 0 "Off" ;
VAL_ 934 SodLeft_D_Stat 7 "NotUsed_3" 6 "NotUsed_2" 5 "NotUsed_1" 4 "Invalid" 3 "Disabled" 2 "On" 1 "Trailer_Tow_Off" 0 "Off" ;
VAL_ 934 SodSnsLeft_D_Stat 3 "Second_Warning_Audio" 2 "System_Failure" 1 "Blocked" 0 "Clear" ;
VAL_ 934 SodAlrtLeft_D_Stat 3 "Bulb_Proveout" 2 "Flash" 1 "On" 0 "Off" ;
VAL_ 934 SodInnrLeft_D_Stat 3 "Reporting" 2 "Not_Reporting" 1 "System_Standby" 0 "Initialization" ;
VAL_ 969 Dimming_Level_Stat 3 "Low" 2 "Not_Used" 1 "High" 0 "Null" ;
VAL_ 969 Current_Color_Stat 15 "NotUsed7" 14 "NotUsed6" 13 "NotUsed5" 12 "NotUsed4" 11 "NotUsed3" 10 "NotUsed2" 9 "NotUsed1" 8 "Null" 7 "Color7" 6 "Color6" 5 "Color5" 4 "Color4" 3 "Color3" 2 "Color2" 1 "Color1" 0 "Off" ;
VAL_ 969 BlendedColorRed_Stat 15 "NotUsed10" 14 "NotUsed9" 13 "NotUsed8" 12 "NotUsed7" 11 "NotUsed6" 10 "NotUsed5" 9 "NotUsed4" 8 "NotUsed3" 7 "NotUsed2" 6 "NotUsed1" 5 "_5" 4 "_4" 3 "_3" 2 "_2" 1 "_1" 0 "Null" ;
VAL_ 969 BlendedColorGreen_Stat 15 "NotUsed10" 14 "NotUsed9" 13 "NotUsed8" 12 "NotUsed7" 11 "NotUsed6" 10 "NotUsed5" 9 "NotUsed4" 8 "NotUsed3" 7 "NotUsed2" 6 "NotUsed1" 5 "_5" 4 "_4" 3 "_3" 2 "_2" 1 "_1" 0 "Null" ;
VAL_ 969 BlendedColorBlue_Stat 15 "NotUsed10" 14 "NotUsed9" 13 "NotUsed8" 12 "NotUsed7" 11 "NotUsed6" 10 "NotUsed5" 9 "NotUsed4" 8 "NotUsed3" 7 "NotUsed2" 6 "NotUsed1" 5 "_5" 4 "_4" 3 "_3" 2 "_2" 1 "_1" 0 "Null" ;
VAL_ 969 BlendedColor_Stat 3 "NotUsed" 2 "Null" 1 "On" 0 "Off" ;
VAL_ 969 TurnLampRrOut_B_Stat 1 "Out" 0 "Null" ;
VAL_ 969 TurnLampRlOut_B_Stat 1 "Out" 0 "Null" ;
VAL_ 1070 StopStrtStdby_D_Indic_UB 1 "Fresh_data" 0 "Unchanged_data" ;
VAL_ 1070 PassRstrnInd_Req_UB 1 "Fresh_data" 0 "Unchanged_data" ;
VAL_ 1070 HiElPwInhbt_B_Stat_UB 1 "Fresh_data" 0 "Unchanged_data" ;
VAL_ 1070 HiElPwInhbt_B_Stat 1 "Inhibit" 0 "No_Inibit" ;
VAL_ 1070 StopStrtStdby_D_Indic 6 "NotUsed2" 5 "Telltale_Struck_Out" 4 "Telltale_Flashing_Amber" 3 "Telltale_On_Amber" 2 "Telltale_Flashing_Green" 1 "Telltale_On_Green" 0 "Telltale_Off" 7 "NotUsed3" ;
VAL_ 1070 CoolantFanStepAct_UB 1 "Fresh_data" 0 "Unchanged_data" ;
VAL_ 1070 CoolantFanStepAct 31 "Unused7" 30 "Unused6" 29 "Unused5" 28 "Unused4" 27 "Unused3" 26 "Unused2" 25 "Unused1" 23 "Step23" 22 "Step22" 21 "Step21" 20 "Step20" 19 "Step19" 18 "Step18" 17 "Step17" 16 "Step16" 15 "Step15" 14 "Step14" 13 "Step13" 12 "Step12" 11 "Step11" 10 "Step10" 9 "Step9" 8 "Step8" 7 "Step7" 6 "Step6" 5 "Step5" 4 "Step4" 3 "Step3" 2 "Step2" 1 "Step1" 24 "Max_Fan_Speed_Req" 0 "Fan_Cmd_Off" ;
VAL_ 1070 RstrnImpactEvntStatus_UB 1 "Fresh_data" 0 "Unchanged_data" ;
VAL_ 1070 EngAirIn_Te_Actl_UB 1 "Fresh_data" 0 "Unchanged_data" ;
VAL_ 1070 RstrnImpactEvntStatus 7 "Invalid" 6 "Not_Used_4" 5 "Threshold_2_Exceeded" 4 "Not_Used_3" 3 "Threshold_1_Exceeded" 2 "Not_Used_2" 1 "Not_Used_1" 0 "Normal" ;
VAL_ 1070 EngAirIn_Te_Actl 1023 "Fault" 1022 "Unknown" ;
VAL_ 1070 EngAout_N_Actl_UB 1 "Fresh_data" 0 "Unchanged_data" ;
VAL_ 1070 VehVActlEng_D_Qf 3 "OK" 2 "Not_Within_Specifications" 1 "No_Data_Exists" 0 "Faulty" ;
VAL_ 1070 Veh_V_ActlEng_UB 1 "Fresh_data" 0 "Unchanged_data" ;
VAL_ 1070 PassRstrnInd_Req 3 "ABOnNotIllum_OffNotIllum" 2 "AirbagOnNot_Illum_OffIllum" 1 "AirbagOn_Illum_OffNotIllum" 0 "AirbagOn_Illum_Off_Illum" ;
VAL_ 1050 CamraRearBttn_D_Stat 1 "Pressed" 0 "Not_Pressed" ;
VAL_ 1050 AutoHoldSwtch_D_Stat 3 "Faulty" 2 "NotUsed" 1 "Pressed" 0 "Not_Pressed" ;
VAL_ 1050 LpdbPtc3_B_Rq 1 "On" 0 "Off" ;
VAL_ 1050 LpdbPtc2_B_Rq 1 "On" 0 "Off" ;
VAL_ 1050 LpdbPtc1_B_Rq 1 "On" 0 "Off" ;
VAL_ 1050 LpdbHeatWiprPrk_B_Rq 1 "On" 0 "Off" ;
VAL_ 1050 LpdbDfrstRearOn_B_Rq 1 "On" 0 "Off" ;
VAL_ 1050 LpdbDfrstFrOn_B_Rq 1 "On" 0 "Off" ;
VAL_ 1050 LpdbDfrstFlOn_B_Rq 1 "On" 0 "Off" ;
VAL_ 1050 SteWhlHeat_D_Rq 15 "NotUsed6" 14 "NotUsed5" 13 "NotUsed4" 12 "NotUsed3" 11 "NotUsed2" 10 "NotUsed1" 9 "Reserved_3" 8 "Reserved_2" 7 "Reserved_1" 6 "Level_3_Heating" 5 "Level_3_Heating_LS" 4 "Level_2_Heating" 3 "Level_2_Heating_LS" 2 "Level_1_Heating" 1 "Level_1_Heating_LS" 0 "Off" ;
VAL_ 1050 MirrorHeatOn_B_Rq 1 "True" 0 "False" ;
VAL_ 1050 Outside_Air_Temp_Stat 255 "Invalid" 254 "Unknown" ;
VAL_ 1050 Remote_Start_QuietMode 1 "Quiet" 0 "Not_Quiet" ;
